VERSION ""

NS_ :

BS_:

BU_: SOBDMB_AWDC BCMC_CPDB BECMB_EPM PACM GWM _delete BCM ACCM DCDC_HEV GENERIC TSTR
VAL_TABLE_ AwdLckMde_D_Stat 7 "NotUsed_2" 6 "NotUsed_1" 5 "PrimaryAxleSpeedControl" 4 "DualAxleSpeedControl" 3 "EfficiencySplit" 2 "SecondaryAxleTorqueCtrl" 1 "SecondaryAxleSpeedCtrl" 0 "Off" ;
VAL_TABLE_ TlghtTestPrecnd_D2_Stat 7 "TrailerNotConnected" 6 "NotStationary" 5 "InteractionPresent" 4 "PreconditionsPassed" 3 "BattSocLessThan75Percent" 2 "TailLightsOn" 1 "IgnitionNotOn" 0 "Null" ;
VAL_TABLE_ TlghtTestLght_D2_Stat 7 "TestingRearFogLights" 6 "AllOff" 5 "TestingReverseLights" 4 "TestingBrakeLights" 3 "TestingLeftTurnSignal" 2 "TestingRightTurnSignal" 1 "ParkingLightsIlluminated" 0 "Null" ;
VAL_TABLE_ NoReqReqNoDataExistsFaulty 3 "Faulty" 2 "NoDataExists" 1 "Request" 0 "NoRequest" ;
VAL_TABLE_ LaActvStats_D2_Dsply 31 "Unused7" 30 "LA_Off" 29 "ECE_OFF_RTT" 28 "Unused4" 27 "Unused3" 26 "Unused2" 25 "Unused1" 24 "InerveneLeft_InterveneRght" 23 "WarnLeft_InterveneRight" 22 "SuppressLeft_InterveneRght" 21 "AvailLeft_InterveneRhtt" 20 "NoLeft_InterveneRight" 19 "InterveneLeft_WarnRight" 18 "WarnLeft_WarnRight" 17 "SuppressLeft_WarnRight" 16 "AvailableLeft_WarnRight" 15 "NoLeft_WarnRight" 14 "InterveneLeft_SuppressRght" 13 "WarnLeft_SuppressRight" 12 "SuppressLeft_SuppressRight" 11 "AvailLeft_SuppressRight" 10 "NoLeft_SuppressRight" 9 "InterveneLeft_AvailRight" 8 "WarnLeft_AvailRight" 7 "SuppressLeft_AvailRight" 6 "AvailableLeft_AvailRight" 5 "NoLeft_AvailableRight" 4 "InterveneLeft_NoRight" 3 "WarnLeft_NoRight" 2 "SuppressLeft_NoRight" 1 "AvailableLeft_NoRight" 0 "NoLeft_NoRight" ;
VAL_TABLE_ PwTrnkFrontRleas_D_Rq 7 "NotUsed_2" 6 "NotUsed_1" 5 "ActivationButtonRequest" 4 "FrontTrunkDiagnostics" 3 "ManualCinch" 2 "EmergencyRelease" 1 "IpSwitchRelease" 0 "Null" ;
VAL_TABLE_ PwTrnkFrontRleas_D_Src 15 "NotUsed_5" 14 "NotUsed_4" 13 "NotUsed_3" 12 "NotUsed_2" 11 "NotUsed_1" 10 "SelfTest" 9 "Diagnostics" 8 "EmergencyReleaseSwitch" 7 "ManualCinch" 6 "ExteriorSwitch" 5 "IpSwitch" 4 "Cpp" 3 "Sync" 2 "Keypad" 1 "Remote" 0 "PowerOff" ;
VAL_TABLE_ OffOnOverruled 3 "NotUsed" 2 "Overruled" 1 "On" 0 "Off" ;
VAL_TABLE_ BattTracThrml_D_Stat 15 "NotUsed_5" 14 "NotUsed_4" 13 "NotUsed_3" 12 "NotUsed_2" 11 "NotUsed_1" 10 "SysFill" 9 "AirPurge" 8 "VlvCalib" 7 "InActvHeaterCoreClntFlw" 6 "ActvHeaterCoreClntFlw" 5 "MxChlrClntFlw" 4 "ChlrClntFlw" 3 "RadClntFlwFan" 2 "RadClntFlwWoFan" 1 "ClntFlw" 0 "ThrmlSysOff" ;
VAL_TABLE_ Null_NoYes_NotUsed 3 "NotUsed" 2 "Yes" 1 "No" 0 "Null" ;
VAL_TABLE_ Bpt_D_StatEvse 15 "Faulty" 14 "NoDataExists" 13 "NotUsed_6" 12 "NotUsed_5" 11 "NotUsed_4" 10 "NotUsed_3" 9 "NotUsed_2" 8 "NotUsed_1" 7 "EvseFault" 6 "EvseEnergyTransferActive" 5 "EvsePreChargeReady" 4 "EvseBptReady" 3 "ConnectionTglNotConfirmed" 2 "ConnectionTglConfirmed" 1 "Initialization" 0 "NotReady" ;
VAL_TABLE_ BptComm_D_Stat 7 "Faulty" 6 "NoDataExists" 5 "LostCommunicationWithTcu" 4 "LostCommunicationWithEvse" 3 "CommunicationEstablished" 2 "EstablishingCommunication" 1 "EvseNotDetected" 0 "Standby" ;
VAL_TABLE_ BptStrtStop_D_Stat 3 "NotUsed_1" 2 "Start" 1 "Stop" 0 "NoRequest" ;
VAL_TABLE_ BptComm_D_RqHtrn 9 "EnergyTransferFault" 8 "EnergyTransferEnd" 7 "VehicleEnergyTransferActv" 6 "VehicleEnergyTransferReady" 5 "VehiclePreChargeReady" 4 "VehicleEnergyTransferWait" 3 "ConfirmConnection" 2 "VehicleReadyToToggle" 1 "AttemptDgtlCommunication" 0 "NoDigitalCommunication" 15 "NotUsed_6" 14 "NotUsed_5" 13 "NotUsed_4" 12 "NotUsed_3" 11 "NotUsed_2" 10 "NotUsed_1" ;
VAL_TABLE_ Bpt_D_StatHtrn 15 "Faulty" 14 "NotUsed_8" 13 "NotUsed_7" 12 "NotUsed_6" 11 "NotUsed_5" 10 "NotUsed_4" 9 "NotUsed_3" 8 "NotUsed_2" 7 "NotUsed_1" 6 "VehicleFault" 5 "EvseFault" 4 "BptActive" 3 "Precharge" 2 "BptReady" 1 "Initialization" 0 "NotReady" ;
VAL_TABLE_ BptMde_D_Stat 7 "NotUsed_4" 6 "NotUsed_3" 5 "NotUsed_2" 4 "NotUsed_1" 3 "Automatic" 2 "Manual" 1 "Off" 0 "Null" ;
VAL_TABLE_ Bpt_D_StatBattTrac 7 "Faulty" 6 "NotUsed_3" 5 "NotUsed_2" 4 "NotUsed_1" 3 "Active" 2 "Ready" 1 "Wait" 0 "NotReady" ;
VAL_TABLE_ OffRoadMde_D_Stat 7 "NotUsed_5" 6 "NotUsed_4" 5 "NotUsed_3" 4 "NotUsed_2" 3 "NotUsed_1" 2 "Off_Road2" 1 "Off_Road1" 0 "On_Road" ;
VAL_TABLE_ PersCtaSplitView_D_Rq 3 "EnabledFull" 2 "Enabled_180SwitchOnly" 1 "Disabled" 0 "Null" ;
VAL_TABLE_ BattChrgInhbt_D2_Rq 7 "NotUsed_4" 6 "NotUsed_3" 5 "NotUsed_2" 4 "NotUsed_1" 3 "MaintainTargetSoc" 2 "EndAtTarget" 1 "InhibitCharging" 0 "Enable_Charging" ;
VAL_TABLE_ AhbFeat_D_Stat 3 "ADB" 2 "GFHB" 1 "AHBC" 0 "None" ;
VAL_TABLE_ NotDetClosedAjarDisabled 5 "NotUsed_2" 4 "NotUsed_1" 3 "Disabled" 2 "Ajar" 1 "Closed" 0 "NotDetermined" 7 "Faulty" 6 "NotUsed_3" ;
VAL_TABLE_ TwoStatePressedNotPressed 3 "NotDetermined" 2 "SwitchState2" 1 "SwitchState1" 0 "NotPressed" ;
VAL_TABLE_ HybSov_D_Falt 7 "FetLowSideOpenOrShort" 6 "FetLifeLimitReached" 5 "FetOpenCircuit" 4 "FetOutputShortToPower" 3 "FetOutputShortToGround" 2 "FetNotControlled" 1 "OnPowerToLoad" 0 "OffNoPowerToLoad" ;
VAL_TABLE_ PaaKMyKeyChng_D_Stat 3 "NotUsed" 2 "ClearAll" 1 "MyKey" 0 "Null" ;
VAL_TABLE_ TemperatureColorDsply 3 "NotUsed" 2 "ColorForSeverlyLimited" 1 "ColorForLimited" 0 "ColorForNormal" ;
VAL_TABLE_ DcacRdy_D_Stat 7 "NotUsed_2" 6 "NotUsed_1" 5 "Faulted" 4 "ProtectionTempearture" 3 "ProtectionOverload" 2 "ProtectionGfci" 1 "Active" 0 "Idle" ;
VAL_TABLE_ HvacCmprLim_D_Stat 7 "NotUsed_2" 6 "NotUsed_1" 5 "CompressorHeadPressure" 4 "AvailableTorque" 3 "PedalPosition" 2 "RPM" 1 "ECT" 0 "NoLimit" ;
VAL_TABLE_ EvseDcChrgIso_D_Stat 7 "Faulty" 6 "NoDataExists" 5 "NotUsed_3" 4 "NotUsed_2" 3 "NotUsed_1" 2 "Valid" 1 "Warning" 0 "Invalid" ;
VAL_TABLE_ PtRmtRprt_D_Stat 15 "NotUsed_4" 14 "NotUsed_3" 13 "NotUsed_2" 12 "PlugInToMaintain12vBattery" 11 "SettingUpdated" 10 "FastChargeComplete" 9 "ChargeNotOccurring" 8 "OneTimeSocReached" 7 "BatteryTemperatureRemind" 6 "ReducedPerformance" 5 "LimitedPerformance" 4 "ChargeFault" 3 "ChargeComplete" 2 "VehiclePreconditioned" 1 "TripDistanceAchieved" 0 "NoReportRequest" ;
VAL_TABLE_ VehOnSrc_D_Stat 15 "NotUsed_11" 14 "NotUsed_10" 13 "NotUsed_9" 12 "NotUsed_8" 11 "NotUsed_7" 10 "NotUsed_6" 9 "EsclRssd" 8 "AutonomousVehicle" 7 "SecureIdle" 6 "FleetVehicleInhibit" 5 "StolenVehicleInhibit" 4 "OverTheAir" 3 "RemoteParkAssist" 2 "RemoteStart" 1 "Manual" 0 "Off" ;
VAL_TABLE_ OfbChrgSetSync_D_Rq 3 "Fail" 2 "Success" 1 "InProgress" 0 "NoSyncInProgress" ;
VAL_TABLE_ StrtrMtrCtlMsgTxt_D2_Rq 3 "NoRequestPcmStartingMsgCtl" 2 "ShiftToNeutralToStart" 1 "ShiftToParkToStart" 0 "NoRequestBcmStartingMsgCtl" ;
VAL_TABLE_ InvalidNotSupported_FE_FF 255 "NotSupported" 254 "Invalid" ;
VAL_TABLE_ PaakMyKey_D_Rq 3 "NotUsed" 2 "ConfirmNewPaakMyKey" 1 "RequestNewPaakMyKey" 0 "None" ;
VAL_TABLE_ PaakMyKeySearch_D_Stat 7 "PhoneErased" 6 "LockButtonTimeOut" 5 "PressLockButton" 4 "ConfirmHmi" 3 "MyKeyPaakFound" 2 "StandardPaakFound" 1 "NoValidPaakFound" 0 "Null" ;
VAL_TABLE_ GearPrkLck_D_Stat 7 "NotUsed_1" 6 "FetLifeLimitReached" 5 "FetOpenCircuit" 4 "FetOutputShortToPower" 3 "FetOutputShortToGround" 2 "FetNotControlled" 1 "OnPowerToLoad" 0 "OffNoPowerToLoad" ;
VAL_TABLE_ DcChrgRdy_D_Stat 15 "Faulty" 14 "NotUsed_4" 13 "NotUsed_3" 12 "NotUsed_2" 11 "CableCheck" 10 "EvseFault" 9 "EvseNotCompatible" 8 "EvsePaused" 7 "GbtPrecharge" 6 "ChargeComplete" 5 "Charging" 4 "Precharge" 3 "WeldCheck" 2 "ChargeReady" 1 "Initialization" 0 "NotReady" ;
VAL_TABLE_ DgtlCommGtwyMde_D_Stat 11 "NotUsed_3" 10 "DgtlCommFailed" 9 "DgtlCommEstablished" 8 "Inactive" 7 "RestartRequest" 6 "AcPnc_Eim" 5 "AcPnc" 4 "AcEim" 3 "DcPnc_Eim" 2 "DcPnc" 1 "DcEim" 0 "NotDetected" 15 "NotUsed_7" 14 "NotUsed_6" 13 "NotUsed_5" 12 "NotUsed_4" ;
VAL_TABLE_ InvalidValidWarningFaulty 3 "Faulty" 2 "Warning" 1 "Valid" 0 "Invalid" ;
VAL_TABLE_ BattChrgMde_D_Actl 3 "NotUsed" 2 "ConstantCurrent" 1 "ConstantVoltage" 0 "NotCharging" ;
VAL_TABLE_ BattTracType_D_Actl 15 "NotUsed_7" 14 "NotUsed_6" 13 "NotUsed_5" 12 "NotUsed_4" 11 "NotUsed_3" 10 "NotUsed_2" 9 "NotUsed_1" 8 "Other" 7 "LithiumTitanateOxide" 6 "LithiumIonPolymer" 5 "TernaryMaterial" 4 "LithiumCobaltOxide" 3 "LithiumManganese" 2 "LithiumIronPhosphate" 1 "NickelMetalHydride" 0 "LeadAcid" ;
VAL_TABLE_ PaakAddErase_D_Rq 3 "EraseAll" 2 "Erase" 1 "Add" 0 "Null" ;
VAL_TABLE_ NoSelect_LowMed_High 3 "High" 2 "Medium" 1 "Low" 0 "NoSelection" ;
VAL_TABLE_ LcwaMsgTxt_D_Stat 3 "SodXFaulty" 2 "SodXBlocked" 1 "TrailerConnected" 0 "NoMessage" ;
VAL_TABLE_ AirCondClu_D_Stat 7 "NotUsed" 6 "FetLifeLimitReached" 5 "FetOpenCircuit" 4 "FetOutputShortToPower" 3 "FetOutputShortToGround" 2 "FetNotControlled" 1 "OnPowerToLoad" 0 "OffNoPowerToLoad" ;
VAL_TABLE_ BattChrgTrgtSoC_D_Rq 7 "Percent_50" 6 "Percent_60" 5 "Percent_70" 4 "Percent_80" 3 "Percent_85" 2 "Percent_90" 1 "Percent_95" 0 "Percent_100" ;
VAL_TABLE_ KeyPadCodeProg_D_Rq 7 "NotUsed_3" 6 "NotUsed_2" 5 "NotUsed_1" 4 "DeleteAll" 3 "Delete" 2 "Add" 1 "ProgrammingMode" 0 "Null" ;
VAL_TABLE_ KeyPadCodeProg_D_Stat 7 "NotUsed_2" 6 "Duplicate" 5 "ProgrammingFailure" 4 "DeleteAll" 3 "Delete" 2 "Add" 1 "LearningMode" 0 "NormalMode" ;
VAL_TABLE_ FobTrgtZone_D_Rq 15 "NotUsed_9" 14 "NotUsed_8" 13 "NotUsed_7" 12 "NotUsed_6" 11 "NotUsed_5" 10 "NotUsed_4" 9 "NotUsed_3" 8 "NotUsed_2" 7 "NotUsed_1" 6 "Approach" 5 "RearInterior" 4 "RearExterior" 3 "Passenger" 2 "Driver" 1 "Interior" 0 "Null" ;
VAL_TABLE_ FobTrgtType_D_Rq 7 "NotUsed_4" 6 "NotUsed_3" 5 "NotUsed_2" 4 "NotUsed_1" 3 "Polling" 2 "Registry" 1 "Crypto" 0 "Null" ;
VAL_TABLE_ DgtlCommGtwyMde_D_Rq 15 "NotUsed_10" 14 "NotUsed_9" 13 "NotUsed_8" 12 "NotUsed_7" 11 "NotUsed_6" 10 "NotUsed_5" 9 "NotUsed_4" 8 "NotUsed_3" 7 "NotUsed_2" 6 "NotUsed_1" 5 "AcPnC" 4 "AcEIM" 3 "DcPnC" 2 "DcEIM" 1 "AttemptDgtlComm" 0 "NoDgtlComm" ;
VAL_TABLE_ BattDcCnnct_D_Cmd 7 "NotUsed_3" 6 "NotUsed_2" 5 "NotUsed_1" 4 "WeldCheck" 3 "OkToDischarge" 2 "Closed" 1 "Precharge" 0 "Open" ;
VAL_TABLE_ Null_NoFault_Fault 3 "NotUsed" 2 "Fault" 1 "NoFault" 0 "Null" ;
VAL_TABLE_ ModemReset_D_Stat 15 "NotUsed_10" 14 "NotUsed_9" 13 "NotUsed_8" 12 "NotUsed_7" 11 "NotUsed_6" 10 "NotUsed_5" 9 "NotUsed_4" 8 "NotUsed_3" 7 "NotUsed_2" 6 "NotUsed_1" 5 "WifiHotSpotResetComplete" 4 "CcsResetComplete" 3 "OnlineTrafficResetComplete" 2 "PaakResetComplete" 1 "ResetNotComplete" 0 "Null" ;
VAL_TABLE_ ModemReset_D_Rq 15 "NotUsed_11" 14 "NotUsed_10" 13 "NotUsed_9" 12 "NotUsed_8" 11 "NotUsed_7" 10 "NotUsed_6" 9 "NotUsed_5" 8 "NotUsed_4" 7 "NotUsed_3" 6 "BrandConnectReset2" 5 "BrandConnectReset1" 4 "CcsReset" 3 "OnlineTrafficReset" 2 "PaakReset" 1 "WifiHotspotReset" 0 "Null" ;
VAL_TABLE_ RstrnOnPsngr_D_RqMnu 15 "Faulty" 14 "NotUsed_11" 13 "NotUsed_10" 12 "ConfiguredOff" 11 "NotUsed_9" 10 "On" 9 "NotUsed_8" 8 "NotUsed_7" 7 "NotUsed_6" 6 "NotUsed_5" 5 "Off" 4 "NotUsed_4" 3 "NotUsed_3" 2 "NotUsed_2" 1 "NotUsed_1" 0 "NoAction" ;
VAL_TABLE_ SldrlUnlckSwtch_D_Stat 3 "InnerHandle" 2 "RearInteriorSwitch" 1 "IpSwitch" 0 "Null" ;
VAL_TABLE_ Sldrl_D_Stat 3 "NotCalibrated" 2 "Closing" 1 "Opening" 0 "NotMoving" ;
VAL_TABLE_ Null_NotAvail_Avail 3 "NotUsed" 2 "Available" 1 "NotAvailable" 0 "Null" ;
VAL_TABLE_ ChrgGoTMnte_D_Stat 15 "NotUsed_4" 14 "NotUsed_3" 13 "NotUsed_2" 12 "NotUsed_1" 11 "Minute_55" 10 "Minute_50" 9 "Minute_45" 8 "Minute_40" 7 "Minute_35" 6 "Minute_30" 5 "Minute_25" 4 "Minute_20" 3 "Minute_15" 2 "Minute_10" 1 "Minute_5" 0 "Minute_0" ;
VAL_TABLE_ NoData_Faulty_1E_1F 31 "Faulty" 30 "NoDataExists" ;
VAL_TABLE_ TrlrTngLoad_D_Stat 7 "Faulty" 6 "NoDataExists" 5 "NotUsed_3" 4 "NotUsed_2" 3 "NotUsed_1" 2 "AboveRange" 1 "InRange" 0 "BelowRange" ;
VAL_TABLE_ NoRequestReqNotUsedFaulty 3 "Faulty" 2 "NotUsed" 1 "Request" 0 "NoRequest" ;
VAL_TABLE_ VehFalr_D_Stat 7 "Faulty" 6 "NotUsed_3" 5 "NotUsed_2" 4 "NotUsed_1" 3 "HeightCorrectionCompleted" 2 "SecondMeasurementCollected" 1 "FirstMeasurementCollected" 0 "NotActive" ;
VAL_TABLE_ VehFalr_D_Rq 7 "NotUsed_3" 6 "NotUsed_2" 5 "NotUsed_1" 4 "NotComplete" 3 "Complete" 2 "RequestSecondMeasurement" 1 "RequestFirstMeasurement" 0 "NoRequest" ;
VAL_TABLE_ TailLghtLoadMde_D_Rq 7 "NotUsed_3" 6 "NotUsed_2" 5 "NotUsed_1" 4 "DeactivateAll" 3 "ActivateFalrMode" 2 "ActivateHitchLoadMode" 1 "ActivatePayloadMode" 0 "NoCommand" ;
VAL_TABLE_ VehPayloadScrn_D_Rq 7 "CheckLoadScreenActive" 6 "WeightCarryScreenActive" 5 "GooseneckScreenActive" 4 "FifthWheelScreenActive" 3 "WeightDistScreenActive" 2 "AddMassEstScreenActive" 1 "PayloadEstScreenActive" 0 "ScaleScreenNotActive" ;
VAL_TABLE_ TailLghtLoadMde_D_Stat 7 "Faulty" 6 "NotUsed_2" 5 "NotUsed_1" 4 "TailLightModeOverride" 3 "FalrModeActive" 2 "HitchLoadModeActive" 1 "PayloadModeActive" 0 "NoTailLightActive" ;
VAL_TABLE_ DrvBhavAudioAlrt_D_Rq 58 "NotUsed_51" 57 "NotUsed_50" 56 "NotUsed_49" 55 "NotUsed_48" 54 "NotUsed_47" 53 "NotUsed_46" 52 "NotUsed_45" 25 "NotUsed_18" 24 "NotUsed_17" 23 "NotUsed_16" 22 "NotUsed_15" 21 "NotUsed_14" 20 "NotUsed_13" 19 "NotUsed_12" 18 "NotUsed_11" 17 "NotUsed_10" 16 "NotUsed_9" 15 "NotUsed_8" 14 "NotUsed_7" 13 "NotUsed_6" 12 "NotUsed_5" 11 "NotUsed_4" 10 "NotUsed_3" 9 "NotUsed_2" 8 "NotUsed_1" 7 "ExcessiveIdleAndUnbuckled" 6 "ExcessiveSpeedAndUnbuckled" 5 "SeatbeltUnbuckled" 4 "HardBrakingBegin" 3 "HardAccelerationBegin" 2 "ExcessiveSpeedBegin" 1 "ExcessiveIdleBegin" 0 "NoMessage" 63 "NotUsed_56" 62 "NotUsed_55" 61 "NotUsed_54" 60 "NotUsed_53" 59 "NotUsed_52" ;
VAL_TABLE_ DcacFaltMsgTxt_D2_Rq 63 "NotUsed_47" 17 "NotUsed_1" 16 "HevDerate" 15 "HvacOn" 14 "OvercurrentLP" 13 "EngineRun" 12 "Service" 11 "NotAvailable" 10 "PlugWarn" 9 "PlugWarnDrive" 8 "BreakerC" 7 "BreakerB" 6 "BreakerA" 5 "FuelLow" 4 "AcOnOutput" 3 "Temperature" 2 "Gfci" 1 "Overcurrent" 0 "Ok" ;
VAL_TABLE_ NotAvail_OffOn_Faulty 3 "Faulty" 2 "On" 1 "Off" 0 "NotAvailable" ;
VAL_TABLE_ Mtr4_D_StatMntr 7 "Faulty" 6 "NotDataExists" 5 "NotUsed" 4 "ReadinessState" 3 "DeactivationState" 2 "PowerGeneration" 1 "PowerConsumption" 0 "Null" ;
VAL_TABLE_ Hour5bitNull 31 "NotUsed_7" 30 "NotUsed_6" 29 "NotUsed_5" 28 "NotUsed_4" 27 "NotUsed_3" 26 "NotUsed_2" 25 "NotUsed_1" 24 "Hour23_11pm" 23 "Hour22_10pm" 22 "Hour21_9pm" 21 "Hour20_8pm" 20 "Hour19_7pm" 19 "Hour18_6pm" 18 "Hour17_5pm" 17 "Hour16_4pm" 16 "Hour15_3pm" 15 "Hour14_2pm" 14 "Hour13_1pm" 13 "Hour12_12pm" 12 "Hour11_11am" 11 "Hour10_10am" 10 "Hour9_9am" 9 "Hour8_8am" 8 "Hour7_7am" 7 "Hour6_6am" 6 "Hour5_5am" 5 "Hour4_4am" 4 "Hour3_3am" 3 "Hour2_2am" 2 "Hour1_1am" 1 "Hour0_12am" 0 "Null" ;
VAL_TABLE_ SdarsAudioRtng_D_Stat 3 "NotUsed" 2 "APIMStereoOut" 1 "X40l2SStereoOut" 0 "NotDetermined" ;
VAL_TABLE_ OffOnOutageFaulty 3 "Faulty" 2 "Outage" 1 "On" 0 "Off" ;
VAL_TABLE_ PrkMde_D_ET 3 "NotUsed" 2 "FreeDrive" 1 "ParkIn" 0 "None" ;
VAL_TABLE_ RmtCtlPrkInSlot_D_ET 7 "NotUsed_3" 6 "NotUsed_2" 5 "NotUsed_1" 4 "Right" 3 "Left" 2 "Rear" 1 "Front" 0 "None" ;
VAL_TABLE_ MoveDir_D_ET 3 "NotUsed" 2 "Backward" 1 "Forward" 0 "None" ;
VAL_TABLE_ ApaMsgTxt_D2_Stat 15 "ReducedFunction" 14 "TrailerFeatureNotAvailable" 13 "AcceleratorPedalInactive" 12 "SensorsBlocked" 11 "TrailerAttached" 10 "TcsDeactivated" 9 "WheelSlip" 8 "HighInclination" 7 "DoorOpen" 6 "SteeringInteraction" 5 "WrongDirection" 4 "SpeedLimitExceeded" 3 "BrakeEvent" 2 "ObstacleInPath" 1 "WaitForSteering" 0 "None" ;
VAL_TABLE_ ApaDrvRq1MsgTxt_D_Rq 7 "NotUsed" 6 "ExitVehicle" 5 "PressApaButton" 4 "ShiftToP" 3 "ShiftToN" 2 "ShiftToD" 1 "ShiftToR" 0 "NoRequest" ;
VAL_TABLE_ DisplayMode 3 "NotUsed" 2 "FullScreen" 1 "Menu" 0 "Off" ;
VAL_TABLE_ ApaSys_D2_Stat 15 "NotUsed_5" 14 "NotUsed_4" 13 "NotUsed_3" 12 "NotUsed_2" 11 "NotUsed_1" 10 "NoSideSelectable" 9 "RightSideSelectable" 8 "LeftSideSelectable" 7 "BothSidesSelectable" 6 "Faulty" 5 "Finished" 4 "Cancelled" 3 "NotAvailable" 2 "Overspeed" 1 "Pause" 0 "NormalOperation" ;
VAL_TABLE_ ApaDrvRq2MsgTxt_D_Rq 15 "NotUsed_7" 14 "NotUsed_6" 13 "NotUsed_5" 12 "NotUsed_4" 11 "NotUsed_3" 10 "NotUsed_2" 9 "NotUsed_1" 8 "CloseDoor" 7 "TakeControl" 6 "ReleaseEpb" 5 "ReleaseSteering" 4 "ReleaseBrake" 3 "DriveBackward" 2 "DriveForward" 1 "Stop" 0 "NoRequest" ;
VAL_TABLE_ ApaSlotTrgt_D_Stat 15 "NotUsed_7" 14 "NotUsed_6" 13 "NotUsed_5" 12 "NotUsed_4" 11 "NotUsed_3" 10 "NotUsed_2" 9 "NotUsed_1" 8 "Front" 7 "Rear" 6 "Right3" 5 "Right2" 4 "Right1" 3 "Left3" 2 "Left2" 1 "Left1" 0 "None" ;
VAL_TABLE_ NtfctnConflict1_D_Rq 7 "NotUsed_4" 6 "NotUsed_3" 5 "NotUsed_2" 4 "NotUsed_1" 3 "ChargeWindow" 2 "DepartureTime" 1 "NoConflictExists" 0 "Null" ;
VAL_TABLE_ InactiveDisableEnableNotUsed 3 "NotUsed" 0 "Inactive" 2 "Enable" 1 "Disable" ;
VAL_TABLE_ ChrgStat_D2_Dsply 15 "ChargeStopCommanded" 14 "ChargeStartCommanded" 13 "ChargeTargetReached" 12 "DriveConditioning" 11 "CabinPreconditioning" 10 "ChargingSystemMaintain" 9 "ChargingInductive" 8 "ChargingDCFastCharge" 7 "ChargingAC" 6 "ChargeScheduled" 5 "EvsePaused" 4 "EvseNotDetected" 3 "EvseNotCompatible" 2 "FaultOutsideCar" 1 "FaultInsideCar" 0 "NotReady" ;
VAL_TABLE_ Null_Manual_Automatic 3 "NotUsed" 2 "Automatic" 1 "Manual" 0 "Null" ;
VAL_TABLE_ BattChrgStrtStop_D_Rq 3 "ReturnToSettings" 2 "StopCharge" 1 "StartCharge" 0 "NoNewRequest" ;
VAL_TABLE_ NoRequest_Mode1_2_3 3 "Mode_3" 2 "Mode_2" 1 "Mode_1" 0 "NoRequest" ;
VAL_TABLE_ RvltnMatchAllw_D_Stat 3 "RevolutionMatchDisabled" 2 "RevolutionMatchEnabled" 1 "ChangeWithDriveMode" 0 "NoSelection" ;
VAL_TABLE_ BattTracCnnct_D_Cmd 7 "NotUsed_3" 6 "NotUsed_2" 5 "NotUsed_1" 4 "WeldCheck" 3 "OkToDischarge" 2 "Closed" 1 "Precharge" 0 "Open" ;
VAL_TABLE_ Faulty_1F 31 "Faulty" ;
VAL_TABLE_ NotDiagnose_FailPass 3 "NotUsed" 2 "Pass" 1 "Fail" 0 "Not_Diagnose_Yet" ;
VAL_TABLE_ Off_On_NotUsed 3 "NotUsed_2" 2 "NotUsed_1" 1 "On" 0 "Off" ;
VAL_TABLE_ OffNoPowerToLoad 7 "NotUsed_1" 6 "FetLifeLimitReached" 5 "FetOpenCircuit" 4 "FetOutputShortToPower" 3 "FetOutputShortToGround" 2 "FetNotControlled" 1 "OnPowerToLoad" 0 "OffNoPowerToLoad" ;
VAL_TABLE_ BrkAppl_D_RqPt 3 "BrakesSlowRelease" 2 "BrakesFastRelease" 1 "BrakesEngage" 0 "NotActive" ;
VAL_TABLE_ TrailCtl_D_Stat 7 "Faulty" 6 "DescentOnly" 5 "EnabledDeny" 4 "StandbyOverThreshold" 3 "StandbyOverride" 2 "Active" 1 "EnabledDescent" 0 "Off" ;
VAL_TABLE_ Faulty_3F 63 "Faulty" ;
VAL_TABLE_ Quality_Data_Faulty 3 "OK" 2 "Not_Within_Specifications" 1 "Eval_In_Progress" 0 "Faulty" ;
VAL_TABLE_ AirAmbTePlgIn_D_Dsply 3 "NotUsed" 2 "Hot_Outside_Plg_In_Msg" 1 "Cold_Outside_Plg_In_Msg" 0 "No_Plg_In_Msg" ;
VAL_TABLE_ NoFault_Fault 1 "Fault" 0 "No_Fault" ;
VAL_TABLE_ OtaTrg_D_Stat 3 "NotUsed_1" 2 "Accepted" 1 "NotAccepted" 0 "Null" ;
VAL_TABLE_ PaakTrgtType_D_Rq 7 "NotUsed_4" 6 "NotUsed_3" 5 "NotUsed_2" 4 "NotUsed_1" 3 "Polling" 2 "Registry" 1 "Crypto" 0 "Null" ;
VAL_TABLE_ PaakTrgtZone_D_Rq 15 "NotUsed_9" 14 "NotUsed_8" 13 "NotUsed_7" 12 "NotUsed_6" 11 "NotUsed_5" 10 "NotUsed_4" 9 "NotUsed_3" 8 "NotUsed_2" 7 "NotUsed_1" 6 "Approach" 5 "RearInterior" 4 "RearExterior" 3 "Passenger" 2 "Driver" 1 "Interior" 0 "Null" ;
VAL_TABLE_ PaakTrgtData_D_Rq 5 "NotUsed_2" 4 "Not_Used1" 3 "Target1_IdBlock2" 2 "Target1_IdBlock1" 1 "Challenge" 0 "Idle" 7 "NotUsed_4" 6 "NotUsed_3" ;
VAL_TABLE_ PaakCtlActv_D_Rq 31 "NotUsed_13" 30 "NotUsed_12" 29 "NotUsed_11" 28 "NotUsed_10" 27 "NotUsed_9" 26 "NotUsed_8" 25 "NotUsed_7" 24 "NotUsed_6" 23 "NotUsed_5" 22 "NotUsed_4" 21 "NotUsed_3" 20 "TrunkFrontRelease" 19 "RemoteStop" 18 "RemoteStart" 17 "PowerDecklid" 16 "RightPowerSlidingDoor" 15 "LeftPowerSlidingDoor" 14 "PowerLiftgate" 13 "GlobalClose" 12 "GlobalOpen" 11 "PanicOff" 10 "PanicOn" 9 "LiftgateGlassRelease" 8 "LiftgateRelease" 7 "DecklidRelease" 6 "DoubleLock" 5 "LockAll" 4 "UnlockAllDoorsPlusCargo" 3 "UnlockCargoDoor" 2 "UnlockAllDoors" 1 "UnlockDriverDoor" 0 "Null" ;
VAL_TABLE_ Null_Invalid_Valid 3 "NotUsed" 2 "Valid" 1 "Invalid" 0 "Null" ;
VAL_TABLE_ PaakCtlData_D_Stat 7 "NotUsed_3" 6 "NotUsed_2" 5 "NotUsed_1" 4 "Response" 3 "EchoTargetIdBlock1" 2 "RequestTargetIdBlock2" 1 "RequestTargetIdBlock1" 0 "Idle" ;
VAL_TABLE_ EngAirFiltMsgTxt_D_Rq 7 "NotUsed_2" 6 "ReducedEngPwCheckAirFilter" 5 "EngineAirFilterMonitorFalt" 4 "ResetComplete" 3 "Clogged" 2 "ReplaceNow" 1 "ReplaceSoon" 0 "NoMessage" ;
VAL_TABLE_ ElPwPoint_D_Rq 3 "On" 2 "Off2" 1 "Off1" 0 "Null" ;
VAL_TABLE_ RearDiffThrml_D_Stat 3 "NotUsed_1" 2 "AboveThermalLimit" 1 "ThermalLimit" 0 "Normal" ;
VAL_TABLE_ NoInhibit_Inhibit 1 "Inhibit" 0 "NoInhibit" ;
VAL_TABLE_ PersRecallSrc_D_Actl 7 "NotUsed_3" 6 "NotUsed_2" 5 "NotUsed_1" 4 "MemorySwitch" 3 "RemoteStart" 2 "KeyFob" 1 "CenterStack" 0 "Null" ;
VAL_TABLE_ BattTracChiller_D_Stat 3 "NotUsed" 2 "ChillerNotAvailable" 1 "ChillerBrieflyAvailable" 0 "ChillerAvailable" ;
VAL_TABLE_ VehShutDownMsgTxt_D_Rq 3 "NotUsed" 2 "ProhibitedRestart" 1 "ShutdownWarning" 0 "NoMessage" ;
VAL_TABLE_ TrnkFrontRleas_D_Src 7 "NotUsed_3" 6 "NotUsed_2" 5 "NotUsed_1" 4 "Cpp" 3 "Sync" 2 "Keypad" 1 "Remote" 0 "Null" ;
VAL_TABLE_ StopoverType_D_Stat 7 "Faulty" 6 "NotUsed_1" 5 "Other" 4 "Work" 3 "Home" 2 "ChargeStation" 1 "FinalDestination" 0 "Null" ;
VAL_TABLE_ NoData_Faulty_3FFFE_3FFFF 262143 "Faulty" 262142 "NoDataExists" ;
VAL_TABLE_ KeylessIdl_D_Rq 3 "Cancel" 2 "IgnitionOff" 1 "Active" 0 "Inactive" ;
VAL_TABLE_ OBCCSerial_D_Rq 3 "PresentAndProvisioned" 2 "PresentAndProvAlertAck" 1 "PresentAndUnprovisioned" 0 "NotPresent" ;
VAL_TABLE_ VehInhbtMde_D_Stat 7 "NotUsed_3" 6 "NotUsed_2" 5 "NotUsed_1" 4 "FullVehicleOta" 3 "Iviota" 2 "SyncOta" 1 "NoOtaSupport" 0 "Unconfigured" ;
VAL_TABLE_ DsmcMsgTxt_D_Dsply 3 "Blockage" 2 "DriverNotSeen" 1 "Fault" 0 "NoMessage" ;
VAL_TABLE_ DgtlCommPnc_D_Stat 7 "Faulty" 6 "NotUsed_3" 5 "NotUsed_2" 4 "NotUsed_1" 3 "Enable" 2 "Disable" 1 "NoContractsInstalled" 0 "Null" ;
VAL_TABLE_ TlghtTest_D_Stat 3 "InProgress" 2 "Ended" 1 "Completed" 0 "Null" ;
VAL_TABLE_ TlghtTestPrecnd_D_Stat 7 "Error" 6 "NotStationary" 5 "InteractionPresent" 4 "PreconditionsPassed" 3 "BattSocLessThan75Percent" 2 "TailLightsOn" 1 "IgnitionNotOn" 0 "Null" ;
VAL_TABLE_ TlghtTestLght_D_Stat 7 "Error" 6 "AllOff" 5 "TestingReverseLights" 4 "TestingBrakeLights" 3 "TestingLeftTurnSignal" 2 "TestingRightTurnSignal" 1 "ParkingLightsIlluminated" 0 "Null" ;
VAL_TABLE_ TlightTest_D_Rq 3 "TestEndAcknowledge" 2 "StartTest" 1 "StopTest" 0 "Null" ;
VAL_TABLE_ NoFaultFaultTemporary 3 "NotUsed" 2 "TemporaryFault" 1 "Fault" 0 "NoFault" ;
VAL_TABLE_ Null_Disabled_Enabled 3 "NotUsed" 2 "Enabled" 1 "Disabled" 0 "Null" ;
VAL_TABLE_ LghtAmbDrvMde_B_Stat 1 "Automatic" 0 "Manual" ;
VAL_TABLE_ LghtAmbDrvMde_D_Rq 3 "NotUsed" 2 "Automatic" 1 "Manual" 0 "Null" ;
VAL_TABLE_ PaakLoclzd_D_Stat 15 "NotUsed_12" 14 "NotUsed_11" 13 "NotUsed_10" 12 "NotUsed_9" 11 "NotUsed_8" 10 "NotUsed_7" 9 "NotUsed_6" 8 "NotUsed_5" 7 "NotUsed_4" 6 "NotUsed_3" 5 "NotUsed_2" 4 "NotUsed_1" 3 "FullLoc" 2 "PausedLoc" 1 "MaintainLink" 0 "BackgroundScan" ;
VAL_TABLE_ NullMphKph 3 "NotUsed" 2 "Kph" 1 "Mph" 0 "Null" ;
VAL_TABLE_ GoTEditMnte_T_RqMnu 15 "Faulty" 14 "NoDataExists" 13 "NotUsed_2" 12 "NotUsed_1" 11 "Minute_55" 10 "Minute_50" 9 "Minute_45" 8 "Minute_40" 7 "Minute_35" 6 "Minute_30" 5 "Minute_25" 4 "Minute_20" 3 "Minute_15" 2 "Minute_10" 1 "Minute_5" 0 "Minute_0" ;
VAL_TABLE_ OffOnSuspendedFaulty 3 "Faulty" 2 "Suspended" 1 "On" 0 "Off" ;
VAL_TABLE_ DgtlCommGtwy_D_Falt 127 "NotUsed_63" 65 "NotUsed_1" 64 "EvseGbtCommTimeout" 63 "EvseGbtCrgVoltMismatch" 62 "EvseGbtChrgCurrntMismatch" 61 "EvseGbtOtherFalt" 60 "EvseGbtEmergShutdown" 59 "EvseGbtEnergyTransFalt" 58 "EvseGbtIntOverTemp" 57 "EvseGbtConnectorFalt" 56 "EvseGbtOverTemp" 55 "EvseResCpsRootCaCertRev" 54 "EvseResSubCA2CertRev" 53 "EvseResSubCA1CertRev" 52 "EvseResCpsProvCertRev" 51 "EvseResRootCaCertRev" 50 "EvseResMoSubCa2CertRev" 49 "EvseResMoSubCa1CertRev" 48 "EvseResMoProvCertRev" 47 "EvseResOemSubCa2CertRev" 46 "EvseResOemSubCa1CertRev" 45 "EvseResOemProvCertRev" 44 "EvseResMoUnknown" 43 "EvseResContractNotAccept" 42 "EvseResNoSuppAppProt" 41 "EvseResCertNotAllowed" 40 "EvseResContractErr" 39 "EvseResNoChrgSvcSelect" 38 "EvseResMeterSignNotVld" 37 "EvseResPwrDelNotApplied" 36 "EvseResTrfSelectInvld" 35 "EvseResChrgProfileInvld" 34 "EvseResWrongChrgParam" 33 "EvseResWrongEnrgyTransMde" 32 "EvseResChlgInvld" 31 "EvseResContractCancel" 30 "EvseResCertChainErr" 29 "EvseResNoCertAvail" 28 "EvseResCertRvk" 27 "EvseResCertExp" 26 "EvseResPymtSelectInvld" 25 "EvseResSvcldInvld" 24 "EvseResUnknownSession" 23 "EvseResSignErr" 22 "EvseResSeqErr" 21 "EvseResFailed" 20 "EvsePreChrgTimeout" 19 "EvseCableCheckTimeout" 18 "EvseCommSetupTimeout" 17 "EvseMsgTimeout" 16 "EvseTlsUnknownCA" 15 "EvseTlsCertExpired" 14 "EvseTlsBadCert" 13 "EvseTlsHandshakeFail" 12 "EvseTlsDecryptFail" 11 "EvseTlsBadRecordMac" 10 "EvseTlsUnexpectedMsg" 9 "EvseTlsFail" 8 "EvseTcpCnnctFail" 7 "EvseUpdErr" 6 "EvseSlaacErr" 5 "EvseStopNotification" 4 "EvseMalfunction" 3 "EvseEmergShutdown" 2 "EvseStatUtilityIntrpt" 1 "EvseStatShutdown" 0 "NoFault" ;
VAL_TABLE_ CellLock_D_Rq 7 "BEC_Enable" 6 "Cargo_Unlock" 5 "Cabin_Unlock" 4 "TrunkRelPopGlassLgCargo" 3 "LockAllDoorsandTailgate" 2 "UnlockDriversDoor" 1 "UnlockAllDoorsandTailgate" 0 "NoRequest" ;
VAL_TABLE_ KeyPadCodeDgt1_D_Stat 15 "NotUsed_4" 14 "NotUsed_3" 13 "NotUsed_2" 12 "NotUsed_1" 11 "Button7_8and9_0" 10 "Button0" 9 "Button9_0or9" 8 "Button8" 7 "Button7_8or7" 6 "Button6" 5 "Button5_6or5" 4 "Button4" 3 "Button3_4or3" 2 "Button2" 1 "Button1_2or1" 0 "EndofString" ;
VAL_TABLE_ Closed_Open 1 "Open" 0 "Closed" ;
VAL_TABLE_ FactoryReset_St 3 "NotUsed_2" 2 "NotUsed_1" 1 "FactoryDefaultsRestored" 0 "Null" ;
VAL_TABLE_ TelematicsSrvc_D_St 7 "NotUsed" 6 "NotifyNotActivatedYet" 5 "NotActivatedYet" 4 "NotifyExpired" 3 "Expired" 2 "ExpiringSoon" 1 "Active" 0 "Null" ;
VAL_TABLE_ FactoryReset_Rq 1 "ResetFactoryDefaults" 0 "Inactive" ;
VAL_TABLE_ Null_NotConnected_Conn 3 "NotUsed" 2 "Connected" 1 "NotConnected" 0 "Null" ;
VAL_TABLE_ TCU_Init_Actvtn_St 3 "NotUsed" 2 "InitialActivateDeny" 1 "InitialActivateAccept" 0 "Invalid" ;
VAL_TABLE_ TCU_Final_Actvtn_St 3 "NotUsed" 2 "FinalActivateDeny" 1 "FinalActivateAccept" 0 "Invalid" ;
VAL_TABLE_ Null_Disable_Enable 3 "NotUsed" 2 "Enable" 1 "Disable" 0 "Null" ;
VAL_TABLE_ BattTracCoolLvl_D_Rq 7 "Faulty" 6 "NotUsed" 5 "ChillerCoolingBattFirst" 4 "ChillerCoolingCabinFirst" 3 "ForcedCoolingRadiator" 2 "OpportunisticCoolingRad" 1 "CoolantFlowBypassLine" 0 "Off" ;
VAL_TABLE_ BattClntVlvOvrrd_D_Rq 3 "NotUsed" 2 "OverrideTbcvToChiller" 1 "OverrideTbcvToRadiator" 0 "NoOverrideToTbcvCLogic" ;
VAL_TABLE_ AutoTowAllw_D_StatMnu 3 "TowHaulCommandedOn" 2 "AutoTowHaulEnabled" 1 "AutoTowHaulDisabled" 0 "NoSelection" ;
VAL_TABLE_ SpkrStd_D_Stat 3 "Faulty" 2 "Normal" 1 "NotPresent" 0 "Null" ;
VAL_TABLE_ RearDiff_D_Stat 15 "NotUsed_7" 14 "NotUsed_6" 13 "NotUsed_5" 12 "NotUsed_4" 11 "NotUsed_3" 10 "NotUsed_2" 9 "NotUsed_1" 8 "TorqueReqNotHonored" 7 "MissingSignal" 6 "ModuleFault" 5 "HydroTempSensorFault" 4 "ClutchPressSensorFault" 3 "AccumPressSensorFault" 2 "ControlValveFault" 1 "MotorFault" 0 "Normal" ;
VAL_TABLE_ NotAllowed_Allowed 1 "Allowed" 0 "NotAllowed" ;
VAL_TABLE_ EngTrlrCnnct_D_Stat 3 "NotUsed_1" 2 "UnverifiedTrailer" 1 "HeavyTrailer" 0 "NoTrailer" ;
VAL_TABLE_ Faulty_FFFF 65535 "Faulty" ;
VAL_TABLE_ NoData_Faulty_3FFE_3FFF 16383 "Faulty" 16382 "NoDataExists" ;
VAL_TABLE_ Faulty_3FFF 16383 "Faulty" ;
VAL_TABLE_ NotExceeded_Exceeded 1 "Exceeded" 0 "NotExceeded" ;
VAL_TABLE_ EmgcyCall_D_Stat 7 "NotUsed_3" 6 "NotUsed_2" 5 "NotUsed_1" 4 "ManualEmergencyCall" 3 "AutoEmergencyCall" 2 "NoEvent" 1 "EmergencyCallNotSupported" 0 "Null" ;
VAL_TABLE_ NotAsserted_Asserted 1 "Asserted" 0 "NotAsserted" ;
VAL_TABLE_ GearLvr_D_ActlDrv 15 "Fault" 14 "Unknown_Position" 13 "NotUsed_2" 12 "NotUsed_1" 11 "Range6" 10 "Range5" 9 "Range4" 8 "Range3_M3_L3" 7 "Range2_M2_L2" 6 "Range1_M1_L1" 5 "Low" 4 "Sport_DriveSport_Mposition" 3 "Drive" 2 "Neutral" 1 "Reverse" 0 "Park" ;
VAL_TABLE_ ChrgrInPwMde_D_Actl 15 "NotUsed_5" 14 "NotUsed_4" 13 "NotUsed_3" 12 "NotUsed_2" 11 "NotUsed_1" 10 "DcBpt" 9 "DigitalCommEnd" 8 "EvseFault" 7 "EvseNotCompatible" 6 "IcCharging" 5 "DcCharging" 4 "AcDigital" 3 "AcBasic" 2 "DigitalCommDetected" 1 "EvsePaused" 0 "EvseNotDetected" ;
VAL_TABLE_ ChrgCordLck_D_Stat 7 "Faulty" 6 "LockFail" 5 "UnlockFail" 4 "LockInProgress" 3 "UnlockInProgress" 2 "Lock" 1 "Unlock" 0 "Retain" ;
VAL_TABLE_ OffOnNoDataFaulty 3 "Faulty" 2 "No_Data_Exists" 1 "On" 0 "Off" ;
VAL_TABLE_ NoMessage_Msg1_3 3 "Message3" 2 "Message2" 1 "Message1" 0 "NoMessage" ;
VAL_TABLE_ TrnRng_D_RqGsm 15 "Fault" 14 "UnknownPosition" 13 "Undefined_2" 12 "Undefined_1" 11 "_6" 10 "_5" 9 "_4" 8 "_3" 7 "_2" 6 "_1" 5 "Low" 4 "Sport_DriveSport" 3 "Drive" 2 "Neutral" 1 "Reverse" 0 "Park" ;
VAL_TABLE_ PrkBrkActv_D_RqGsmGear 3 "NotUsed" 2 "RequestParkBrakeEngage" 1 "NoRequest" 0 "Null" ;
VAL_TABLE_ TrnPrkSys_D_Actl 15 "Faulty" 14 "NotUsed_5" 13 "NotUsed_4" 12 "NotUsed_3" 11 "NotUsed_2" 10 "NotUsed_1" 9 "FrequencyError" 8 "OutOfRangeHigh" 7 "OutOfRangeLow" 6 "Override" 5 "OutOfPark" 4 "TransitionCloseToOutOfPark" 3 "AtNoSpring" 2 "TransitionCloseToPark" 1 "Park" 0 "NotKnown" ;
VAL_TABLE_ OKLowUnknownInvalid 3 "Invalid" 2 "Unknown" 1 "Low" 0 "OK" ;
VAL_TABLE_ PrkAidDrvDir_D_Stat 7 "NotUsed_2" 6 "NotUsed_1" 5 "BackwardNegative" 4 "ForwardNegative" 3 "BackwardPositive" 2 "ForwardPositive" 1 "NoMotion" 0 "DirectionNotKnown" ;
VAL_TABLE_ Pers1Phone_D_Stat 7 "SevenPhoneAssociated" 6 "SixPhoneAssociated" 5 "FivePhoneAssociated" 4 "FourPhoneAssociated" 3 "ThreePhoneAssociated" 2 "TwoPhoneAssociated" 1 "OnePhoneAssociated" 0 "NoPhoneAssociated" ;
VAL_TABLE_ EngExhMdeQuiet_D2_Stat 7 "Faulty" 6 "NotUsed_2" 5 "NotUsed_1" 4 "Track" 3 "Sport" 2 "Normal" 1 "Stealth" 0 "Null" ;
VAL_TABLE_ GasPrtc_D_RqDsply 7 "NotUsed_5" 6 "NotUsed_4" 5 "NotUsed_3" 4 "NotUsed_2" 3 "NotUsed_1" 2 "GpfOverLimit" 1 "GpfAtLimit" 0 "NormalOperation" ;
VAL_TABLE_ Faulty_7FF 2047 "Faulty" ;
VAL_TABLE_ PwSrcULowMde_D_Actl 3 "BuckSpecial" 2 "ReverseBoost" 1 "ForwardBuck" 0 "Standby" ;
VAL_TABLE_ CamraViewSplit_D_Actl 3 "NotUsed" 2 "Inactive" 1 "Active" 0 "Invalid" ;
VAL_TABLE_ ApaTrgtDist_D_Stat 15 "Step15" 14 "Step14" 13 "Step13" 12 "Step12" 11 "Step11" 10 "Step10" 9 "Step9" 8 "Step8" 7 "Step7" 6 "Step6" 5 "Step5" 4 "Step4" 3 "Step3" 2 "Step2" 1 "Step1" 0 "Off" ;
VAL_TABLE_ ApaMsgTxt_D_Rq 15 "NotUsed_6" 14 "NotUsed_5" 13 "NotUsed_4" 12 "NotUsed_3" 11 "ReleaseEpb" 10 "TrailerFeatureNotAvailable" 9 "AccelPedalInactive" 8 "WrongDirection" 7 "SteeringInteraction" 6 "BrakingActive" 5 "HighInclination" 4 "SpeedLimitExceeded" 3 "TcsDisabled" 2 "WheelSlip" 1 "None" 0 "Null" ;
VAL_TABLE_ Memory_2_SwPsngr_Stat 1 "Pressed" 0 "Null" ;
VAL_TABLE_ Pers3Key_D_Stat 3 "NotUsed_1" 2 "KeyUnAssociated" 1 "KeyAssociated" 0 "Null" ;
VAL_TABLE_ PwSrcULoMde_D_Rq 3 "BuckSpecial" 2 "ReverseBoost" 1 "ForwardBuck" 0 "Standby" ;
VAL_TABLE_ WakeAlarm0_B_Typ 1 "CanAndEcuDriveCircuit" 0 "CanOnly" ;
VAL_TABLE_ WakeAlarm0_D_Stat 3 "PublisherReset" 2 "Wake" 1 "AlarmRunning" 0 "AlarmOff" ;
VAL_TABLE_ EmPrflNo_D_Rq 7 "NotUsed_3" 6 "NotUsed_2" 5 "NotUsed_1" 4 "Pers4" 3 "Pers3" 2 "Pers2" 1 "Pers1" 0 "Null" ;
VAL_TABLE_ EmPrflKeyAssoc_D_Rq 7 "NotUsed_3" 6 "DisassociatePhone" 5 "EnterPhoneAssociation" 4 "OverwriteKey" 3 "DisassociateKey" 2 "ExitKeyAssociation" 1 "EnterKeyAssociation" 0 "Null" ;
VAL_TABLE_ Em_D_Stat 3 "NotSupported" 2 "ProfilesOff" 1 "ProfilesOn" 0 "Null" ;
VAL_TABLE_ EmButtn_D_Stat 7 "ButtonAssociationFailed" 6 "ButtonAssociationExited" 5 "ButtonAssociationEntered" 4 "Button4Pressed" 3 "Button3Pressed" 2 "Button2Pressed" 1 "Button1Pressed" 0 "Null" ;
VAL_TABLE_ EmPrflNo_D_Stat 7 "NotUsed_3" 6 "NotUsed_2" 5 "NotUsed_1" 4 "Pers4" 3 "Pers3" 2 "Pers2" 1 "Pers1" 0 "Null" ;
VAL_TABLE_ EmPrflKeyAssoc_D_Stat 7 "WrongDevice" 6 "KeyAssociateFailed" 5 "KeyAssociateSuccess" 4 "KeyAlreadyInUse" 3 "KeyDisassociated" 2 "KeyAssociationExited" 1 "KeyAssociationEntered" 0 "Null" ;
VAL_TABLE_ PersNo_D_Actl 7 "Unused_3" 6 "Unused_2" 5 "NotDetermined" 4 "Vehicle" 3 "PERS_4" 2 "PERS_3" 1 "PERS_2" 0 "PERS_1" ;
VAL_TABLE_ WiprFront_D_Stat2 15 "NO_DATA_EXISTS" 14 "STALLED" 13 "NotUsed" 12 "AUTO_ADJUST" 11 "COURTESYWIPE" 10 "AUTO_HIGH" 9 "AUTO_LOW" 8 "WASH" 7 "MIST_FLICK" 6 "MAN_HIGH" 5 "MAN_LOW" 4 "MAN_INT_ON" 3 "MAN_INT_OFF" 2 "OFF_MOVING" 1 "AUTO_OFF" 0 "OFF" ;
VAL_TABLE_ TurnLghtSwtch_D_Stat2 3 "NotUsed" 2 "Right" 1 "Left" 0 "Off" ;
VAL_TABLE_ SelDrvMdePos01_D_Stat 31 "Faulty" 30 "SelDrvMde31" 29 "SelDrvMde30" 28 "SelDrvMde29" 27 "SelDrvMde28" 26 "SelDrvMde27" 25 "SelDrvMde26" 24 "SelDrvMde25" 23 "SelDrvMde24" 22 "SelDrvMde23" 21 "SelDrvMde22" 20 "SelDrvMde21" 19 "SelDrvMde20" 18 "SelDrvMde19" 17 "SelDrvMde18" 16 "SelDrvMde17" 15 "SelDrvMde16" 14 "SelDrvMde15" 13 "SelDrvMde14" 12 "SelDrvMde13" 11 "SelDrvMde12" 10 "SelDrvMde11" 9 "SelDrvMde10" 8 "SelDrvMde09" 7 "SelDrvMde08" 6 "SelDrvMde07" 5 "SelDrvMde06" 4 "SelDrvMde05" 3 "SelDrvMde04" 2 "SelDrvMde03" 1 "SelDrvMde02" 0 "SelDrvMde01" ;
VAL_TABLE_ ImmedFastMediumSlow 3 "Slow" 2 "Medium" 1 "Fast" 0 "Immediately" ;
VAL_TABLE_ AdbHiBeamKeepOff_D_Rq 3 "KeepBothOff" 2 "KeepLeftOff" 1 "KeepRightOff" 0 "BothFreeRunning" ;
VAL_TABLE_ AdbLampOnOff_D_Rq 3 "BothOn" 2 "LeftOnRightOff" 1 "RightOnLeftOff" 0 "BothOff" ;
VAL_TABLE_ Fault_Occupied_Empty_Un 3 "Unknown" 2 "Empty" 1 "Occupied" 0 "Fault" ;
VAL_TABLE_ Off_On_Flash_Triggered 3 "Triggered" 2 "Flash" 1 "On" 0 "Off" ;
VAL_TABLE_ KeyOffMde_D_Actl 15 "NotUsed_11" 14 "NotUsed_10" 13 "NotUsed_9" 12 "NotUsed_8" 11 "NotUsed_7" 10 "NotUsed_6" 9 "NotUsed_5" 8 "NotUsed_4" 7 "NotUsed_3" 6 "NotUsed_2" 5 "NotUsed_1" 4 "CriticalBattery" 3 "Hibernate" 2 "Transport" 1 "Factory" 0 "Normal" ;
VAL_TABLE_ IaccVLim_D_Rq 252 "NotUsed_2" 250 "LimitSpeed_250" 240 "LimitSpeed_240" 230 "LimitSpeed_230" 220 "LimitSpeed_220" 210 "LimitSpeed_210" 200 "LimitSpeed_200" 190 "LimitSpeed_190" 150 "LimitSpeed_150" 140 "LimitSpeed_140" 130 "LimitSpeed_130" 120 "LimitSpeed_120" 110 "LimitSpeed_110" 100 "LimitSpeed_100" 90 "LimitSpeed_90" 80 "LimitSpeed_80" 70 "LimitSpeed_70" 60 "LimitSpeed_60" 50 "LimitSpeed_50" 40 "LimitSpeed_40" 30 "LimitSpeed_30" 20 "LimtSpeed_20" 251 "NotUsed_1" 255 "Faulty" 254 "NoDataExists" 253 "NotUsed_3" 180 "LimitSpeed_180" 179 "LimitSpeed_179" 178 "LimitSpeed_178" 177 "LimitSpeed_177" 176 "LimitSpeed_176" 175 "LimitSpeed_175" 174 "LimitSpeed_174" 173 "LimitSpeed_173" 172 "LimitSpeed_172" 171 "LimitSpeed_171" 170 "LimitSpeed_170" 169 "LimitSpeed_169" 168 "LimitSpeed_168" 167 "LimitSpeed_167" 166 "LimitSpeed_166" 165 "LimitSpeed_165" 164 "LimitSpeed_164" 163 "LimitSpeed_163" 162 "LimitSpeed_162" 161 "LimitSpeed_161" 160 "LimitSpeed_160" 15 "LimitSpeed_15" 14 "LimitSpeed_14" 13 "LimitSpeed_13" 12 "LimitSpeed_12" 11 "LimitSpeed_11" 10 "LimitSpeed_10" 9 "LimitSpeed_9" 8 "LimitSpeed_8" 7 "LimitSpeed_7" 6 "LimitSpeed_6" 5 "LimitSpeed_5" 4 "LimitSpeed_4" 3 "LimitSpeed_3" 2 "LimitSpeed_2" 1 "LimitSpeed_1" 0 "LimitSpeed_0" ;
VAL_TABLE_ IaccVLimUnit_D_Rq 3 "NoDataExists" 2 "Mph" 1 "Kph" 0 "Null" ;
VAL_TABLE_ SelDrvMdeAwd_D_Rq 31 "Faulty" 30 "NotUsed_17" 29 "NotUsed_16" 28 "NotUsed_15" 27 "NotUsed_14" 26 "NotUsed_13" 25 "NotUsed_12" 24 "NotUsed_11" 23 "NotUsed_10" 22 "NotUsed_9" 21 "NotUsed_8" 20 "CustomMode" 19 "OnePedalDrive" 18 "DragMode" 17 "EvLaterChargeMode" 16 "EvNowMode" 15 "TrackMode" 14 "RoughRoadMode" 13 "NotAvailable" 12 "HighSpeedDesertMode_Baja" 11 "SportAdaptiveMode" 10 "RockCrawlMode" 9 "MudRutsMode" 8 "SandMode" 7 "EconomyMode" 6 "GrassGravelSnow" 5 "TowHaulMode" 4 "SportMode" 3 "Normal_4L" 2 "Normal_4A" 1 "Normal_2H" 0 "NormalMode" ;
VAL_TABLE_ SelDrvMdeAwd_D_Stat 0 "NotAvailable" 1 "Available" 2 "TemporarilyNotAvailable" 3 "Faulty" ;
VAL_TABLE_ RearDiffLckMsg2_D_Rq 15 "NotUsed_3" 14 "NotUsed_2" 13 "NotUsed_1" 12 "ElsdReduced" 11 "LockingFeatureNotAvailable" 10 "EsldOff" 9 "ElsdRestored" 8 "ElsdOverheated" 7 "Locker_Disabled" 6 "Locker_Enabled" 5 "LockerSpeed5" 4 "LockerSpeed4" 3 "LockerSpeed3" 2 "LockerSpeed2" 1 "LockerSpeed1" 0 "NormalNoMessage " ;
VAL_TABLE_ EmgcyAsstActv_D_Stat 3 "ConfiguredOff" 2 "Active" 1 "Inactive" 0 "Null" ;
VAL_TABLE_ HeadLghtHiPrmsn_D_Stat 3 "CancelAndSuppress" 2 "Cancel" 1 "Hold" 0 "AllowChange" ;
VAL_TABLE_ SelDrvMdeSwtch 3 "Faulty" 2 "SwitchState2" 1 "SwitchState1" 0 "NotPressed" ;
VAL_TABLE_ ChrgCompltMsgTxt_D_Rq 3 "NotUsed_1" 2 "ChargeToFull" 1 "ChargeToFastChargeLimit" 0 "DefaultLabel" ;
VAL_TABLE_ AwdDrvMde 7 "Faulty" 6 "NotAvailable" 5 "RockCrawl" 4 "Baja" 3 "MudAndSand" 2 "Weather" 1 "Sport" 0 "Normal" ;
VAL_TABLE_ SelDrvMdePt_D_Rq 31 "Faulty" 30 "NotUsed15" 29 "NotUsed14" 28 "NotUsed13" 27 "NotUsed12" 26 "NotUsed11" 25 "NotUsed10" 24 "NotUsed9" 23 "NotUsed8" 22 "NotUsed7" 21 "CustomMode" 20 "TrackMode" 19 "OnePedalDrive" 18 "EvLaterChargerMode" 17 "EvNowMode" 16 "DragMode" 15 "HighSpeedDesertMode_Baja" 14 "SportAdaptiveMode" 13 "NotAvailable_13" 12 "NotAvailable_12" 11 "NotAvailable_11" 10 "NotAvailable_10" 9 "RockCrawlMode" 8 "MudRutsMode" 7 "SandMode" 6 "EconomyMode" 5 "GrassGravelSnow" 4 "NotAvailable_04" 3 "TowHaulMode" 2 "NotAvailable_02" 1 "SportMode" 0 "NormalMode" ;
VAL_TABLE_ OffLockUnlockFaulty 3 "Faulty" 2 "Unlock" 1 "Lock" 0 "Off" ;
VAL_TABLE_ OffOnOutOfRange 3 "NotUsed" 2 "OutOfRange" 1 "On" 0 "Off" ;
VAL_TABLE_ NoMessage_Msg1_15 15 "Message15" 14 "Message14" 13 "Message13" 12 "Message12" 11 "Message11" 10 "Message10" 9 "Message9" 8 "Message8" 7 "Message7" 6 "Message6" 5 "Message5" 4 "Message4" 3 "Message3" 2 "Message2" 1 "Message1" 0 "NoMessage" ;
VAL_TABLE_ NotAvailable_Available 1 "Available" 0 "NotAvailable" ;
VAL_TABLE_ PwStep_D_DrvInhbt 3 "NotUsed" 2 "DriveInhibitMalfunction" 1 "DriveInhibited" 0 "DriveNotInhibited" ;
VAL_TABLE_ NoMessage_Msg1_31 31 "Message31" 30 "Message30" 29 "Message29" 28 "Message28" 27 "Message27" 26 "Message26" 25 "Message25" 24 "Message24" 23 "Message23" 22 "Message22" 21 "Message21" 20 "Message20" 19 "Message19" 18 "Message18" 17 "Message17" 16 "Message16" 15 "Message15" 14 "Message14" 13 "Message13" 12 "Message12" 11 "Message11" 10 "Message10" 9 "Message9" 8 "Message8" 7 "Message7" 6 "Message6" 5 "Message5" 4 "Message4" 3 "Message3" 2 "Message2" 1 "Message1" 0 "NoMessage" ;
VAL_TABLE_ TrnRng_D_RqFap 7 "NotUsed3" 6 "NotUsed2" 5 "NotUsed1" 4 "Backwards" 3 "Forwards" 2 "NoMotion" 1 "Immobilize" 0 "NoRequest" ;
VAL_TABLE_ FuelLvlWarn_D_ActlEng 7 "DteLevel5Lowest" 6 "DteLevel4" 5 "DteLevel3" 4 "DteLevel2NonMyKey" 3 "DteLevel1MyKey" 2 "VeryLow" 1 "Low" 0 "OK" ;
VAL_TABLE_ OffLowMedHigh 3 "High" 2 "Medium" 1 "Low" 0 "Off" ;
VAL_TABLE_ RstrnMdulePw_D_Falt 3 "NotUsed_1" 2 "NoFault" 1 "Fault" 0 "Null" ;
VAL_TABLE_ HeadLghtHiCtrl_D_RqAhb 7 "NotUsed2" 6 "NotUsed1" 5 "Auto_HiBeam" 4 "Auto_LoBeam" 3 "Flash" 2 "Man_HiBeam" 1 "Man_LoBeam" 0 "Null" ;
VAL_TABLE_ AhbHiBeam_D_Rq 3 "NotUsed" 2 "HighBeamRecommended" 1 "LowBeamRecommended" 0 "DeactivatedUnavailable" ;
VAL_TABLE_ AhbcRampingV_D_Rq 3 "Slow" 2 "Medium" 1 "Fast" 0 "Immediately" ;
VAL_TABLE_ ApaGearShif_D_RqDrv 7 "NotUSed2" 6 "NotUsed1" 5 "ShiftToP" 4 "ShiftToN" 3 "ShiftToD" 2 "ShiftToR" 1 "NoRequest" 0 "Null" ;
VAL_TABLE_ ApaLongCtl_D_RqDrv 7 "NotUsed3" 6 "NotUsed2" 5 "ReleaseBrake" 4 "DriveBackward" 3 "DriveForward" 2 "Stop" 1 "NoRequest" 0 "Null" ;
VAL_TABLE_ ApaActvSide2_D_Stat 3 "NoSide" 2 "Right" 1 "Left" 0 "Null" ;
VAL_TABLE_ ApaScan_D_Stat 3 "ParkSlotReady" 2 "ParkSlotFound" 1 "NoParkSlot" 0 "Null" ;
VAL_TABLE_ ApaSelSapp_D_Stat 3 "NotConfigured" 2 "NotSelectable" 1 "Selectable" 0 "Null" ;
VAL_TABLE_ ApaSys_D_Stat 7 "Faulty" 6 "Finished" 5 "NotAccessible" 4 "ApaCancelled" 3 "Overspeed" 2 "On" 1 "Off" 0 "Null" ;
VAL_TABLE_ ApaSteScanMde_D_Stat 3 "Steering" 2 "Scanning" 1 "NotScanning" 0 "Null" ;
VAL_TABLE_ ApaAcsy_D_RqDrv 7 "CloseDoor" 6 "SelectSideRight" 5 "SelectSideLeft" 4 "CheckForObject" 3 "PressApaButton" 2 "SelectSide" 1 "NoRequest" 0 "Null" ;
VAL_TABLE_ ApaSteWhl_D_RqDrv 3 "TakeControl" 2 "RemoveHands" 1 "NoRequest" 0 "Null" ;
VAL_TABLE_ WiprFrontSwtch_D_Stat 15 "NotUsed6" 14 "NotUsed5" 13 "NotUsed4" 12 "NotUsed3" 11 "NotUsed2" 10 "NotUsed1" 9 "PositionNotDetermined" 8 "High" 7 "Low" 6 "Position6" 5 "Position5" 4 "Position4" 3 "Position3" 2 "Position2" 1 "Position1" 0 "Off" ;
VAL_TABLE_ Chirp_D_RqTrlr 3 "NotUsed" 2 "Chirp_2" 1 "Chirp_1" 0 "NoRequest" ;
VAL_TABLE_ Off_On_Unknown_Invalid 3 "Invalid" 2 "Unknown" 1 "On" 0 "Off" ;
VAL_TABLE_ Unknown_7FFE_Invalid_7FFF 32767 "Invalid" 32766 "Unknown" ;
VAL_TABLE_ OffOnNotUsedFaulty 3 "Faulty" 2 "NotUsed" 1 "On" 0 "Off" ;
VAL_TABLE_ HeadLghtOn_D_Rq 7 "NotUsed2" 6 "NotUsed1" 5 "DrlBoth" 4 "DrlRight" 3 "DrlLeft" 2 "High" 1 "Low" 0 "Off" ;
VAL_TABLE_ PoliceIdlMde_D_Stat 15 "NotUsed_7" 14 "NotUsed_6" 13 "NotUsed_5" 12 "NotUsed_4" 11 "NotUsed_3" 10 "UtilityIdleActive" 9 "PepsActive" 8 "Decommissioned" 7 "ActiveFault" 6 "ArmFault" 5 "PrearmedFault" 4 "OffFault" 3 "Active" 2 "Arm" 1 "Prearmed" 0 "Off" ;
VAL_TABLE_ GrdAsstAllw_D_DsplyPt 3 "NotUsed" 2 "On" 1 "Off" 0 "NoModeSelected" ;
VAL_TABLE_ PrkBrkMsgTxt_D_Rq 15 "Message15" 14 "Message14" 13 "Message13" 12 "Message12" 11 "Message11" 10 "Message10" 9 "Message9" 8 "Message8" 7 "Message7" 6 "Message6" 5 "Message5" 4 "Message4" 3 "Message3" 2 "Message2" 1 "Message1" 0 "No_Message" ;
VAL_TABLE_ AutoRgenTxt_B_RqDsply 1 "AutExhFilterCleanOFF" 0 "AutExhFilterCleanON" ;
VAL_TABLE_ TrnGearMsgTxt_D_Rq 15 "Message_15" 14 "Message_14" 13 "Message_13" 12 "Message_12" 11 "Message_11" 10 "Message_10" 9 "Message_9" 8 "Message_8" 7 "Message_7" 6 "Message_6" 5 "Message_5" 4 "Message_4" 3 "Message_3" 2 "Message_2" 1 "Message_1" 0 "NoMessage" ;
VAL_TABLE_ ACU_AutoStoreResult_St 2 "No_Station_Found" 1 "Inactive" 0 "Invalid" ;
VAL_TABLE_ ACU_DirectTune_St 2 "Valid_Station" 1 "Invalid_Station" 0 "Invalid" ;
VAL_TABLE_ ACU_RadioSeekMode2_St 16 "ContAutoDown" 15 "ContAutoUp" 14 "PISeek" 13 "TpSeek" 12 "Autostore" 11 "PtySeekDown" 10 "PtySeekUp" 9 "ScanDown" 8 "ScanUp" 7 "ContManualDown" 6 "ContManualUp" 5 "ManSingleStepDown" 4 "ManSingleStepUp" 3 "AutoDown" 2 "AutoUp" 1 "SeekOff" 0 "Invalid" ;
VAL_TABLE_ ACU_CurrTUBand_St 10 "SAT2" 9 "SAT1" 8 "DAB2" 7 "DAB1" 6 "Fm3" 5 "AmAst" 4 "Am" 3 "FmAst" 2 "Fm2" 1 "Fm1" 0 "Invalid" 13 "reserved1" 15 "reserved_last" 12 "DAB3" 11 "SAT3" ;
VAL_TABLE_ ChargeProfIDPref_Rq 3 "NotUsed" 2 "Value" 1 "ChargeNow" 0 "Inactive" ;
VAL_TABLE_ EngExhMdeQuiet_D_Stat 3 "Faulty" 2 "QuietExhaust" 1 "LoudExhaust" 0 "Null" ;
VAL_TABLE_ GearSelLck_D_Rq 3 "PreventionBlocker" 2 "Unlock" 1 "Lock" 0 "Null" ;
VAL_TABLE_ SuspDrvMde_D_Rq 7 "Faulty" 6 "NotUsed2" 5 "NotUsed1" 4 "Drag" 3 "Track" 2 "Snow_Wet" 1 "Sport" 0 "Normal" ;
VAL_TABLE_ NotPressed_PressedNotUsed 3 "NotUsed2" 2 "NotUsed1" 1 "Pressed" 0 "Not_Pressed" ;
VAL_TABLE_ WhlRearDual_D_Stat 3 "NotUsed" 2 "Dual" 1 "Single" 0 "NoDataExists" ;
VAL_TABLE_ TracKeyMde_D_Stat 3 "NotUsed" 2 "NotActive" 1 "Active" 0 "ModeNotDetermined" ;
VAL_TABLE_ TrnManShifGear_D_IndDrv 7 "Indicate_Reverse_Gear" 6 "Indicate_Gear6" 5 "Indicate_Gear5" 4 "Indicate_Gear4" 3 "Indicate_Gear3" 2 "Indicate_Gear2" 1 "Indicate_Gear1" 0 "No_Indication" ;
VAL_TABLE_ LsmcBrkDecel_D_Stat 7 "NotUsed_3" 6 "NotUsed_2" 5 "NotUsed_1" 4 "Denied" 3 "FaultDegraded" 2 "FaultExt" 1 "On" 0 "Off" ;
VAL_TABLE_ OffOn_RampUpDown 3 "Ramp_Down" 2 "Ramp_Up" 1 "On" 0 "Off" ;
VAL_TABLE_ DieslMsgTxt_D_Rq 3 "NotUsed2" 2 "NotUsed1" 1 "ReducedEnginePower" 0 "NoMessage" ;
VAL_TABLE_ NoMessage_Msg1_7 7 "Message7" 6 "Message6" 5 "Message5" 4 "Message4" 3 "Message3" 2 "Message2" 1 "Message1" 0 "NoMessage" ;
VAL_TABLE_ LnchCtl 3 "NotUsed2" 2 "NotUsed1" 1 "LC_On" 0 "LC_Off" ;
VAL_TABLE_ LnchCtlSys_D_Stat 7 "NotUsed3" 6 "NotUsed2" 5 "NotUsed1" 4 "On_LC_Unavailable_TC_On" 3 "On_LC_Unavailable" 2 "On_LC_Available" 1 "On_LC_Active" 0 "LC_OFF" ;
VAL_TABLE_ Rght_Lefthand_Traffic 1 "Left_Hand_Traffic" 0 "Right_Hand_Traffic" ;
VAL_TABLE_ IsaOffst_D_Stat 15 "Faulty" 14 "Null" 13 "Thirteen" 12 "Twelve" 11 "Eleven" 10 "Ten" 9 "Nine" 8 "Eight" 7 "Seven" 6 "Six" 5 "Five" 4 "Four" 3 "Three" 2 "Two" 1 "One" 0 "Zero" ;
VAL_TABLE_ IsaVLimUnit_D_Rq 3 "NoDataExists" 2 "Mph" 1 "Kph" 0 "Null" ;
VAL_TABLE_ ApaChime_D_Rq 7 "NotUsed2" 6 "NotUsed1" 5 "Warning_Chime" 4 "Finish_Chime" 3 "Stop_Now_Chime" 2 "Spot_Ready_Chime" 1 "Spot_Found_Chime" 0 "No_Chime" ;
VAL_TABLE_ SlMde_D_RqDsply 3 "NotUsed" 2 "ManualSpeed_LimiterSymbol" 1 "AutoSpeed_LimiterSymbol" 0 "NoSpeed_LimiterSymbol" ;
VAL_TABLE_ SlMde_D_Rq 3 "IsaNotConfigured" 2 "Manual_Mode" 1 "Auto_Mode" 0 "Null" ;
VAL_TABLE_ Faulty_FF 255 "Faulty" ;
VAL_TABLE_ BrkDrvMde_D_Rq 7 "Faulty" 6 "RockCrawl" 5 "Baja" 4 "DragOrMudAndSand" 3 "Track" 2 "Snow_Wet" 1 "Sport" 0 "Normal" ;
VAL_TABLE_ NoYesNoDataFaulty 3 "Faulty" 2 "NoDataExists" 1 "Yes" 0 "No" ;
VAL_TABLE_ SidePrkSnsR4_D_Stat 15 "NotUsed" 14 "NotFullyScannedYet" 13 "NoObjectInSector" 12 "Zone12" 11 "Zone11" 10 "Zone10" 9 "Zone9" 8 "Zone8" 7 "Zone7" 6 "Zone6" 5 "Zone5" 4 "Zone4" 3 "Zone3" 2 "Zone2" 1 "Zone1" 0 "Off" ;
VAL_TABLE_ PtDrvMde_D_Rq 15 "Faulty" 14 "NotUsed11" 13 "NotUsed10" 12 "NotUsed9" 11 "NotUsed8" 10 "NotUsed7" 9 "NotUsed6" 8 "Track" 7 "Drag" 6 "Rock" 5 "Baja" 4 "Sand" 3 "TowHaulGradeAssist" 2 "SnowWet" 1 "Sport" 0 "Normal" ;
VAL_TABLE_ SteEffort_D_Stat 7 "NotUsed_3" 6 "NotUsed_2" 5 "NotUsed_1" 4 "SpecialMode_2" 3 "SpecialMode_1" 2 "Comfort" 1 "Sport" 0 "Normal" ;
VAL_TABLE_ Null_Off_On 3 "NotUsed" 2 "On" 1 "Off" 0 "Null" ;
VAL_TABLE_ NoData_Faulty_E_F 15 "Faulty" 14 "NoDataExists" ;
VAL_TABLE_ Invalid_7F 127 "Invalid" ;
VAL_TABLE_ Faulty_1FFF 8191 "Faulty" ;
VAL_TABLE_ VehStab_D_Stat 15 "Faulty" 14 "No_Data_Exists" 13 "NotUsed6" 12 "NotUsed5" 11 "NotUsed4" 10 "NotUsed3" 9 "NotUsed2" 8 "Combined_OS_and_US" 7 "High_SSRA_no_OS" 6 "Straight" 5 "Post_Oversteer" 4 "Post_Transition" 3 "Countersteer" 2 "Understeer" 1 "Oversteer" 0 "Linear" ;
VAL_TABLE_ FohEng_D_Rq 3 "AutoEnable_ParkEnable" 2 "AutoDisable_ParkEnable" 1 "AutoEnable_ParkDisable" 0 "Disable_Stop" ;
VAL_TABLE_ Null_Hi_NotUsed_Low 3 "Low" 2 "Not_Used" 1 "High" 0 "Null" ;
VAL_TABLE_ Current_Color 15 "NotUsed7" 14 "NotUsed6" 13 "NotUsed5" 12 "NotUsed4" 11 "NotUsed3" 10 "NotUsed2" 9 "NotUsed1" 8 "Null" 7 "Color7" 6 "Color6" 5 "Color5" 4 "Color4" 3 "Color3" 2 "Color2" 1 "Color1" 0 "Off" ;
VAL_TABLE_ Blended_Color 15 "NotUsed10" 14 "NotUsed9" 13 "NotUsed8" 12 "NotUsed7" 11 "NotUsed6" 10 "NotUsed5" 9 "NotUsed4" 8 "NotUsed3" 7 "NotUsed2" 6 "NotUsed1" 5 "_5" 4 "_4" 3 "_3" 2 "_2" 1 "_1" 0 "Null" ;
VAL_TABLE_ OffOn_Null_NotUsed 3 "NotUsed" 2 "Null" 1 "On" 0 "Off" ;
VAL_TABLE_ DieslPrtc2_D_RqDsply 15 "NotUsed4" 14 "NotUsed3" 13 "NotUsed2" 12 "NotUsed1" 11 "OCR_ExhFilterClean_Stopped" 10 "OCR_ExhFilterCleaned" 9 "RgnOff_AtLimit" 8 "RgnOff_Overloaded" 7 "RgnOff_Loaded" 6 "Exhaust_Filter_Full" 5 "DPF_Overlimit" 4 "DPF_AtLimit" 3 "ExhFilter_Drive_Completed" 2 "Cleaning_Exhaust_Filter" 1 "DPF_Overloaded" 0 "DPF_Normal_Operation" ;
VAL_TABLE_ Null_Pers1_4_Vehicle 7 "Unused_2" 6 "Unused_1" 5 "Vehicle" 4 "PERS_4" 3 "PERS_3" 2 "PERS_2" 1 "PERS_1" 0 "Null" ;
VAL_TABLE_ PrkLckCtlEnbl_D_RqIpc 3 "Rq_Towing" 2 "Rq_Enable" 1 "Rq_Disable" 0 "Null" ;
VAL_TABLE_ PrkLckCtlUnlck_D_Stat 3 "Trans_And_Steer_Unlckd" 2 "Steering_Unlckd" 1 "Transmission_Unlckd" 0 "Null" ;
VAL_TABLE_ VehKeyActv_D_Stat 15 "NotUsed7" 14 "NotUsed6" 13 "NotUsed5" 12 "NotUsed4" 11 "NotUsed3" 10 "NotUsed2" 9 "NotUsed1" 8 "Key8Active" 7 "Key7Active" 6 "Key6Active" 5 "Key5Active" 4 "Key4Active" 3 "Key3Active" 2 "Key2Active" 1 "Key1Active" 0 "NoKeyActive" ;
VAL_TABLE_ VehLckInd_D_Rq 3 "NotUsed" 2 "On_Day" 1 "On_Night" 0 "Off" ;
VAL_TABLE_ PrkBrkDynmc_D_Allw 3 "NotUsed" 2 "EPB_ECD_NotPossible" 1 "EPB_ECD_Possible" 0 "Used_at_Start_Up" ;
VAL_TABLE_ NoData_Faulty_3E_3F 63 "Faulty" 62 "NoDataExists" ;
VAL_TABLE_ Unknown_Invalid_3E_3F 63 "Invalid" 62 "Unknown" ;
VAL_TABLE_ Faulty_1FF 511 "Faulty" ;
VAL_TABLE_ NoData_Faulty_1FFF_1FFE 8191 "Faulty" 8190 "NoDataExists" ;
VAL_TABLE_ Null_Off_On_Faulty 3 "Faulty" 2 "On" 1 "Off" 0 "Null" ;
VAL_TABLE_ AwdSys_D_Stat 3 "Faulty" 2 "NotUsed" 1 "_4x4_L_H_Active" 0 "_4x4_L_H_Inactive" ;
VAL_TABLE_ EmotiveType_D_Dsply 3 "EmotiveDisplay_3" 2 "EmotiveDisplay_2" 1 "EmotiveDisplay_1" 0 "Null" ;
VAL_TABLE_ TrnSrvcRqd_B_Rq 1 "On" 0 "Off" ;
VAL_TABLE_ immoSecureIdleMode 3 "NotUsed2" 2 "NotUsed1" 1 "Active" 0 "Inactive" ;
VAL_TABLE_ SteMdule_D_Stat 7 "NotUsed" 6 "EPAS_Failure3" 5 "EPAS_Failure2" 4 "System_Failure" 3 "EPAS_Shutdown" 2 "Normal_Op_Full_Assist" 1 "Normal_Op_Limited_Assist" 0 "EPAS_Initialization" ;
VAL_TABLE_ Faulty_FFF 4095 "Faulty" ;
VAL_TABLE_ Faulty_3FF 1023 "Faulty" ;
VAL_TABLE_ Invalid_F 15 "Invalid" ;
VAL_TABLE_ Invalid_1F 31 "Invalid" ;
VAL_TABLE_ NoData_Faulty_FE_FF 255 "Faulty" 254 "NoDataExists" ;
VAL_TABLE_ PtRmtRprt_D_Rq 15 "NotUsed_4" 14 "NotUsed_3" 13 "NotUsed_2" 12 "PlugInToMaintain12vBattery" 11 "SettingUpdated" 10 "FastChargeComplete" 9 "ChargeNotOccurring" 8 "OneTimeSocReached" 7 "BatteryTemperatureReminder" 6 "ReducedPerformance" 5 "LimitedPerformance" 4 "ChargeFault" 3 "ChargeComplete" 2 "VehiclePreconditioned" 1 "TripDistanceAchieved" 0 "NoReportRequest" ;
VAL_TABLE_ Invalid_NotReq_Req 0 "Invalid" 1 "Not_Requested" 2 "Requested" 3 "NotUsed" ;
VAL_TABLE_ Inactive_NotReq_Req 0 "Inactive" 1 "Not_Requested" 2 "Requested" 3 "NotUsed" ;
VAL_TABLE_ BattElecPerf_D_Actl 7 "NotUsed" 6 "Hot_Batt_Severe_Lim_Perf" 5 "Hot_Batt_Reduced_Perf" 4 "Hot_Batt_Close_to_lim_Per" 3 "Cold_Batt_Severe_Lim_Perf" 2 "Cold_Batt_Reduced_Perf" 1 "Cold_Batt_Close_to_lim_Pe" 0 "Ok_no_message_displayed" ;
VAL_TABLE_ ChkPlgtoStrt_D_Dsply 3 "NotUsed" 2 "Is_VehicleUnplugged_Prompt" 1 "Check_Plug_to_Start" 0 "No_Message_Display" ;
VAL_TABLE_ PwrFlowTxt_D_Dsply 15 "NotUsed7" 14 "NotUsed6" 13 "NotUsed5" 12 "NotUsed4" 11 "Disply_Rgen_Chrg_Txt" 10 "Disp_Fast_Charge_Txt" 9 "Disp_Fast_Charge_Cmplt_Txt" 8 "Disp_Charge_Cmplt_Txt" 7 "Disp_Remote_Start_Txt" 6 "Disp_Eng_Drv_Txt" 5 "Disp_Elec_Drv_Txt" 4 "Disp_Idle_with_Chrg_Txt" 3 "Disp_Idle_Txt" 2 "Disp_Charg_HV_Batt_Txt" 1 "Disp_Hyb_Drive_Txt" 0 "No_Text" ;
VAL_TABLE_ EngOnMsg_D_Dsply 14 "_0xE_to_1F_NotUsed" 12 "Battery_Temperature" 11 "Hill_Decent_Control" 10 "Fuel_Maintenance" 9 "Oil_Maintenance" 8 "Normal_Operation" 7 "Low_Gear" 6 "Batt_Charging" 5 "Engine_Cold" 4 "Neutral_Gear" 3 "Heater_Setting" 2 "High_Speed" 1 "Acceleration" 0 "No_Display" 13 "Drive_Mode_Selection" ;
VAL_TABLE_ PtDataKeyId_D_Stat 15 "NotUsed5" 14 "NotUsed4" 13 "NotUsed3" 12 "NotUsed2" 11 "NotUsed1" 10 "Tot_Veh_NUT" 9 "Cust_4_NUT" 8 "Cust_3_NUT" 7 "Cust_2_NUT" 6 "Cust_1_NUT" 5 "Tot_Veh_Stat" 4 "Cust_4_Stat" 3 "Cust_3_Stat" 2 "Cust_2_Stat" 1 "Cust_1_Stat" 0 "Null" ;
VAL_TABLE_ ChrgStat_D_Dsply 7 "NotUsed" 6 "Complete" 5 "Scheduled" 4 "In_Progress" 3 "Fault_Outside_Car" 2 "Fault_Inside_Car" 1 "Fault_Unknown_Location" 0 "Not_Ready" ;
VAL_TABLE_ TrnLvrV_D_Rq 3 "Full_Speed" 2 "Aggressive" 1 "Normal" 0 "Quiet" ;
VAL_TABLE_ EngStrtStop_B_SrcOil 1 "Eng_start_stop_for_oilmnt" 0 "Not_Requested" ;
VAL_TABLE_ FuelMaintMde_D_Rq 3 "Feature_Not_Present" 2 "Fuel_Maint_Req_Now" 1 "Fuel_Maint_Req_Soon" 0 "NoRequest" ;
VAL_TABLE_ FuelMaintMde_D_Dsply 3 "Feature_Not_Present" 2 "In_Fuel_Maint_Mode" 1 "Close_to_Fuel_Maint" 0 "OK" ;
VAL_TABLE_ DynoMde_B_Cmd 1 "DynomometerMode" 0 "NormalOperation" ;
VAL_TABLE_ HvacPrecondRecirc_D_Rq 3 "Last_User_Setting" 2 "Auto" 1 "Recirc" 0 "Outside" ;
VAL_TABLE_ HvacPrecondAC_D_Rq 3 "Last_User_Setting" 2 "Auto" 1 "On" 0 "Off" ;
VAL_TABLE_ HybMdeStat_D_Dsply 7 "NotUsed2" 6 "EV_Charge" 5 "EV_Override" 4 "Forced_EV_Mode" 3 "Forced_Charge_Sustain_Mode" 2 "Auto_Charge_Sustain_Mode" 1 "Auto_Charge_Deplete_Mode" 0 "Null_State" ;
VAL_TABLE_ PwFlowPlgBatt_D_Dsply 3 "NotUsed" 2 "Flow_from_Plug_to_Batt" 1 "Flow_from_Batt_to_Plug" 0 "No_Flow" ;
VAL_TABLE_ PwFlowEngMtr_D_Dsply 3 "NotUsed" 2 "Flow_from_Eng_to_Mtr" 1 "Flow_from_Mtr_to_Eng" 0 "No_Flow" ;
VAL_TABLE_ PwFlowEngFuel_D_Dsply 3 "NotUsed" 2 "Flow_from_Eng_to_Fuel" 1 "Flow_from_Fuel_to_Eng" 0 "No_Flow" ;
VAL_TABLE_ PwFlowMtrDrv_D_Dsply 3 "NotUsed" 2 "Flow_from_Mtr_to_Axle" 1 "Flow_from_Axle_to_Mtr" 0 "No_FLow" ;
VAL_TABLE_ PwFlowEngDrv_D_Dsply 3 "NotUsed" 2 "Flow_from_Eng_to_Axle" 1 "Flow_from_Axle_to_Eng" 0 "No_Flow" ;
VAL_TABLE_ PwFlowBattMtr_D_Dsply 3 "NotUsed" 2 "Flow_from_Batt_to_Mtr" 1 "Flow_from_Mtr_to_Batt" 0 "No_Flow" ;
VAL_TABLE_ HybMdeLimMsgTxt_D_Rq 3 "Limited_Req_Full_Defrost" 2 "Limited_Climate_Defrost" 1 "Limited_System_Performance" 0 "Null" ;
VAL_TABLE_ CenterStackRing_D_Actl 3 "LimitedOn" 2 "On" 1 "Off" 0 "Null" ;
VAL_TABLE_ ConsTipUnitPt_D_Dsply 3 "NotUsed" 2 "FuelEconomy" 1 "Distance" 0 "Percentage" ;
VAL_TABLE_ ConsTipMsg1_D_Dsply 15 "NotUsed10" 14 "NotUsed9" 13 "NotUsed8" 12 "NotUsed7" 11 "NotUsed6" 10 "NotUsed5" 9 "NotUsed4" 8 "NotUsed3" 7 "NotUsed2" 6 "NotUsed1" 5 "ReduceIdleTime" 4 "ClimateUsage" 3 "VehicleSpeed" 2 "Deceleration" 1 "Acceleration" 0 "NoDisplay" ;
VAL_TABLE_ NoData_Faulty_FFFE_FFFF 65535 "Faulty" 65534 "NoDataExists" ;
VAL_TABLE_ NoData_Faulty_FFE_FFF 4095 "Faulty" 4094 "NoDataExists" ;
VAL_TABLE_ NoData_Faulty_7FFE_7FFF 32767 "Faulty" 32766 "NoDataExists" ;
VAL_TABLE_ NoData_Faulty_3FE_3FF 1023 "Faulty" 1022 "NoDataExists" ;
VAL_TABLE_ ReFuelSysStat_D_Dsply 7 "NotUsed3" 6 "NotUsed2" 5 "NotUsed1" 4 "Refuel_Err" 3 "Close_Fuel_Door" 2 "Refuel_Ready" 1 "Wait_To_Fuel" 0 "Null" ;
VAL_TABLE_ OffOn_NotUsed 3 "NotUsed2" 2 "NotUsed1" 1 "On" 0 "Off" ;
VAL_TABLE_ DrQltyDrv_D_StatGsm 7 "Faulty" 6 "NoDataExists" 5 "NotUsed2" 4 "NotUsed1" 3 "ClosedDegraded" 2 "OpenDegraded" 1 "ClosedOkay" 0 "OpenOkay" ;
VAL_TABLE_ ChrgrInPwType_D_Actl 6 "NotUsed3" 5 "NotUsed2" 4 "NotUsed1" 3 "DC_Fast_Charging" 2 "AC_Level2_240v" 1 "AC_Level1_120v" 0 "EVSE_Not_Detected" ;
VAL_TABLE_ ChrgrSysFalt1_D_Stat 3 "NotUsed" 2 "Pass" 1 "Fail" 0 "NotDiagnoseYet" ;
VAL_TABLE_ PepsKeyActv_D_Stat 15 "NotUsed11" 14 "NotUsed10" 13 "NotUsed9" 12 "NotUsed8" 11 "NotUsed7" 10 "NotUsed6" 9 "NotUsed5" 8 "Key4Active" 7 "NotUsed4" 6 "NotUsed3" 5 "NotUsed2" 4 "Key3Active" 3 "NotUsed1" 2 "Key2Active" 1 "Key1Active" 0 "NoKeyActive" ;
VAL_TABLE_ CellRstrt_D_Rq 3 "NotUsed" 2 "RemoteCancel" 1 "RemoteStart" 0 "NoRequest" ;
VAL_TABLE_ CellChirp_D_Rq 7 "NotUsed3" 6 "NotUsed2" 5 "NotUsed1" 4 "Honk" 3 "ChirpHonk" 2 "Chirp2" 1 "Chirp1" 0 "NoRequest" ;
VAL_TABLE_ CellLock_D_Rq_Rsm 7 "NotUsed3" 6 "NotUsed2" 5 "NotUsed1" 4 "TrunkRelPopGlassLgCargo" 3 "LockAllDoorsandTailgate" 2 "UnlockDriversDoor" 1 "UnlockAllDoorsandTailgate" 0 "NoRequest" ;
VAL_TABLE_ BattTracHazrd_D_Stat 3 "Disabled" 2 "HazardConfirmed" 1 "ExternalMonitoringRequired" 0 "NoHazardDetected" ;
VAL_TABLE_ RmtCtlBody_D_Stat 15 "NotUsed_6" 14 "NotUsed_5" 13 "NotUsed_4" 12 "NotUsed_3" 11 "NotUsed_2" 10 "NotUsed_1" 9 "Shutdown" 8 "ManeuverFinished" 7 "ReadyForResume" 6 "Pause" 5 "Maneuvering" 4 "ReadyForManeuvering" 3 "Activation" 2 "Initialize" 1 "Preparation" 0 "Disabled" ;
VAL_TABLE_ RmtCtlTrgt_D_Rq 3 "NotUsed" 2 "Null" 1 "RemoteParkAssist" 0 "ManeuverId" ;
VAL_TABLE_ RmtCtl_D_RqBody 7 "NotUsed_2" 6 "NotUsed_1" 5 "Error" 4 "Abort" 3 "PauseKeypad" 2 "PauseHazard" 1 "PauseDoorHandle" 0 "Null" ;
VAL_TABLE_ Null_NoPolling_Polling 3 "NotUsed" 2 "Polling" 1 "NoPolling" 0 "Null" ;
VAL_TABLE_ RmtCtl_D_Stat 15 "Faulty" 14 "NotUsed_5" 13 "NotUsed_4" 12 "NotUsed_3" 11 "NotUsed_2" 10 "NotUsed_1" 9 "Shutdown" 8 "ManeuverFinished" 7 "ReadyForResume" 6 "Pause" 5 "Maneuvering" 4 "ReadyForManeuvering" 3 "Activation" 2 "Initialize" 1 "Preparation" 0 "Disabled" ;
VAL_TABLE_ RmtCtlRngSet_D_Rq 3 "NotUsed" 2 "RangeSetB" 1 "RangeSetA" 0 "None" ;
VAL_TABLE_ SelDrvMde_1_31 31 "Faulty" 30 "SelDrvMde31" 29 "SelDrvMde30" 28 "SelDrvMde29" 27 "SelDrvMde28" 26 "SelDrvMde27" 25 "SelDrvMde26" 24 "SelDrvMde25" 23 "SelDrvMde24" 22 "SelDrvMde23" 21 "SelDrvMde22" 20 "SelDrvMde21" 19 "SelDrvMde20" 18 "SelDrvMde19" 17 "SelDrvMde18" 16 "SelDrvMde17" 15 "SelDrvMde16" 14 "SelDrvMde15" 13 "SelDrvMde14" 12 "SelDrvMde13" 11 "SelDrvMde12" 10 "SelDrvMde11" 9 "SelDrvMde10" 8 "SelDrvMde09" 7 "SelDrvMde08" 6 "SelDrvMde07" 5 "SelDrvMde06" 4 "SelDrvMde05" 3 "SelDrvMde04" 2 "SelDrvMde03" 1 "SelDrvMde02" 0 "SelDrvMde01" ;
VAL_TABLE_ WndwRearHeat_D_Stat 7 "NotUsed" 6 "FetLiftLimitReached" 5 "FetOpenCircuit" 4 "FetOutputShortToPower" 3 "FetOutputShortToGround" 2 "FetNotControlled" 1 "OnPowerToLoad" 0 "OffNoPowerToLoad" ;
VAL_TABLE_ Faulty_7F 63 "Faulty" ;
VAL_TABLE_ DcacHw_D_Confg 15 "NotUsed_11" 14 "NotUsed_10" 13 "NotUsed_9" 12 "NotUsed_8" 11 "NotUsed_7" 10 "NotUsed_6" 9 "NotUsed_5" 8 "NotUsed_4" 7 "NotUsed_3" 6 "NotUsed_2" 5 "NotUsed_1" 4 "Power_2300W" 3 "Power_7200W" 2 "Power_2400W" 1 "Power_2000W" 0 "NoDcacHardware" ;
VAL_TABLE_ DcacFaltMsgTxt_D_Rq 15 "HvacOn" 14 "OvercurrentLP" 13 "EngineRun" 12 "Service" 11 "NotAvailable" 10 "PlugWarn" 9 "PlugWarnDrive" 8 "BreakerC" 7 "BreakerB" 6 "BreakerA" 5 "FuelLow" 4 "AcOnOutput" 3 "Temperature" 2 "Gfci" 1 "Overcurrent" 0 "Ok" ;
VAL_TABLE_ DcacLoFuelMsgTxt_D_Rq 31 "Minute_31" 30 "Minute_30" 29 "Minute_29" 28 "Minute_28" 27 "Minute_27" 26 "Minute_26" 25 "Minute_25" 24 "Minute_24" 23 "Minute_23" 22 "Minute_22" 21 "Minute_21" 20 "Minute_20" 19 "Minute_19" 18 "Minute_18" 17 "Minute_17" 16 "Minute_16" 15 "Minute_15" 14 "Minute_14" 13 "Minute_13" 12 "Minute_12" 11 "Minute_11" 10 "Minute_10" 9 "Minute_9" 8 "Minute_8" 7 "Minute_7" 6 "Minute_6" 5 "Minute_5" 4 "Minute_4" 3 "Minute_3" 2 "Minute_2" 1 "Minute_1" 0 "Ok" ;
VAL_TABLE_ DcacEngOnMsgTxt_D_Rq 3 "NotUsed" 2 "DisplayQuestion" 1 "DisplayWarning" 0 "Ok" ;
VAL_TABLE_ OffPendingActiveNotUsed 3 "NotUsed" 2 "Active" 1 "Pending" 0 "Off" ;
VAL_TABLE_ OffLowHighNotUsed 3 "NotUsed" 2 "High" 1 "Low" 0 "Off" ;
VAL_TABLE_ Null_Off_On_NoControl 3 "NoControl" 2 "On" 1 "Off" 0 "Null" ;
VAL_TABLE_ NotDeterminedNotPresentFaulty 3 "Faulty" 2 "Present" 1 "NotPresent" 0 "NotDetermined" ;
VAL_TABLE_ VehStrtInhbt_D_Dsply 15 "NotUsed_12" 14 "NotUsed_11" 13 "NotUsed_10" 12 "NotUsed_9" 11 "NotUsed_8" 10 "NotUsed_7" 9 "NotUsed_6" 8 "NotUsed_5" 7 "NotUsed_4" 6 "FleetPhoneNumber" 5 "FleetGeneral" 4 "OtaSuccess" 3 "PostOtaActivatePermFail" 2 "PostOtaActivateWarning" 1 "DuringOtaActivate" 0 "NoMessage" ;
VAL_TABLE_ VehOnRqstr_D_Stat 11 "NotUsed_8" 10 "NotUsed_7" 9 "NotUsed_6" 8 "NotUsed_5" 7 "NotUsed_4" 6 "NotUsed_3" 5 "NotUsed_2" 4 "NotUsed_1" 3 "FleetVehInhbt" 2 "StolenVehInhbt" 1 "OverTheAir" 0 "NoRequestor" 15 "NotUsed_12" 14 "NotUsed_11" 13 "NotUsed_10" 12 "NotUsed_9" ;
VAL_TABLE_ OtaActv_D_Stat 15 "NotUsed_10" 14 "NotUsed_9" 13 "NotUsed_8" 12 "NotUsed_7" 11 "NotUsed_6" 10 "NotUsed_5" 9 "NotUsed_4" 8 "NotUsed_3" 7 "NotUsed_2" 6 "NotUsed_1" 5 "NonInterruptible_Pending" 4 "NonInterruptible_Config" 3 "NonInterruptible_ER" 2 "NonInterruptible_AB" 1 "Interruptible_AB" 0 "NoInVehicleOta" ;
VAL_TABLE_ ULoBattTransfer_D_Stat 7 "NotUsed_2" 6 "NotUsed_1" 5 "TransferError" 4 "TransferComplete" 3 "TransferThroughGridEnergy" 2 "InsufficientEnergyToXfer" 1 "TransferInProgress" 0 "NoTransfer" ;
VAL_TABLE_ PwRnngBoardPoll_D_Stat 3 "NotUsed" 2 "PkPresent" 1 "PkNotPresent" 0 "NotPolling" ;
VAL_TABLE_ BrkHold_D_Stat 7 "NotUsed_3" 6 "NotUsed_2" 5 "NotUsed_1" 4 "HeldSecondary" 3 "HeldSecure" 2 "Held" 1 "Inactive" 0 "Off" ;
VAL_TABLE_ Null_Left_Right 3 "NotUsed" 2 "Right" 1 "Left" 0 "Null" ;
VAL_TABLE_ TrlrHitch_D_RqMnu 15 "NotUsed_10" 14 "NotUsed_9" 13 "NotUsed_8" 12 "NotUsed_7" 11 "NotUsed_6" 10 "NotUsed_5" 9 "NotUsed_4" 8 "NotUsed_3" 7 "NotUsed_2" 6 "NotUsed_1" 5 "GoToTraileringDomain" 4 "Confirm" 3 "TurnOnTba" 2 "TurnOnAutohitch" 1 "CancelAutohitch" 0 "NoRequest" ;
VAL_TABLE_ DcacRdy_D2_Stat 3 "Faulted" 2 "RecoverableFault" 1 "Active" 0 "Idle" ;
VAL_TABLE_ NotFaulted_Faulted 1 "Faulted" 0 "NotFaulted" ;
VAL_TABLE_ BattULoChrgHyb_D_Stat 7 "NotUsed_4" 6 "NotUsed_3" 5 "NotUsed_2" 4 "NotUsed_1" 3 "VehicleServiceRequired" 2 "EvRangeLossDueToLoadActive" 1 "BatteryServiceRequired" 0 "Null" ;
VAL_TABLE_ PoliceDmngLvl_D_Stat 7 "NotUsed" 6 "Off_Night" 5 "Off_Day" 4 "Low1Night" 3 "Low1Day" 2 "Inactive" 1 "Decommissioned" 0 "Null" ;
VAL_TABLE_ VehWlcmFrwl_D_Stat 3 "RunStart" 2 "Farewell" 1 "Welcome" 0 "Null" ;
VAL_TABLE_ VehWlcmFrwlMde_D_Stat 7 "IlluminatedExit" 6 "CourtesyLightingDelayExt" 5 "CourtesyLightingExtended" 4 "CourtesyLightingDelayAll" 3 "CourtesyLightingAll" 2 "IlluminatedEntry" 1 "Approach" 0 "Null" ;
VAL_TABLE_ OnePdlDrvBrk_D_Rq 3 "Active_FbrkStandstillApply" 2 "Active_FbrkStopApply" 1 "Active_NoFbrkAllow" 0 "Inactive" ;
VAL_TABLE_ OnePdlDrv_D_Stat 3 "Enabled_BrkLampAndFbrk" 2 "Enabled_BrkLamp" 1 "Enabled_NoAction" 0 "Disabled" ;
VAL_TABLE_ HybMdeMsgTxt_D2_Rq 15 "NotUsed_4" 14 "NotUsed_3" 13 "NotUsed_2" 12 "NotUsed_1" 11 "EvOverride_Avail" 10 "EvLaterActv_EvAuto_NowAvai" 9 "EvNowActv_EvAuto_LaterAvai" 8 "EvAutoActv_EvNow_LaterAvai" 7 "EvAutoActv_NoOtherMdeAvail" 6 "EvChrgActv_EvAutoMdeAvail" 5 "EvAutoActv_EvChrgMdeAvail" 4 "EvChrgActv_AllPhevMdeAvail" 3 "EvLaterActv_AllPhevMdeAvai" 2 "EvNowActv_AllPhevMdeAvail" 1 "EvAutoActv_AllPhevMdeAvail" 0 "Null" ;
VAL_TABLE_ TsrRegionTxt_D_Stat 31 "Faulty" 30 "NotUsed_8" 29 "NotUsed_7" 28 "NotUsed_6" 27 "NotUsed_5" 26 "NotUsed_4" 25 "NotUsed_3" 24 "NotUsed_2" 23 "NotUsed_1" 22 "Region_22" 21 "Region_21" 20 "Region_20" 19 "Region_19" 18 "Region_18" 17 "Region_17" 16 "Region_16" 15 "Region_15" 14 "Region_14" 13 "Region_13" 12 "Region_12" 11 "Region_11" 10 "Region_10" 9 "Region_09" 8 "Region_08" 7 "Region_07" 6 "Region_06" 5 "Region_05" 4 "Region_04" 3 "Region_03" 2 "Region_02" 1 "Region_01" 0 "NotDetermined" ;
VAL_TABLE_ Inactive_On_NotUsed 7 "NotUsed_6" 6 "NotUsed_5" 5 "NotUsed_4" 4 "NotUsed_3" 0 "Inactive" 1 "On" 2 "NotUsed_1" 3 "NotUsed_2" ;
VAL_TABLE_ _S_No_Yes 1 "Yes" 0 "No" ;
VAL_TABLE_ UpDownNotUsedFaulty 3 "Faulty" 2 "NotUsed" 1 "Down" 0 "Up" ;
VAL_TABLE_ PtWakeReas_D_Stat 15 "NotUsed_9" 14 "NotUsed_8" 13 "NotUsed_7" 12 "NotUsed_6" 11 "NotUsed_5" 10 "NotUsed_4" 9 "NotUsed_3" 8 "NotUsed_2" 7 "NotUsed_1" 6 "ElapsedTime" 5 "ThirdPartyWakeup" 4 "DoorAjar" 3 "EarlyWake" 2 "NonMotiveStart" 1 "MotiveStart" 0 "Null" ;
VAL_TABLE_ ExtLghtLeft_D_RqMnu 7 "NotUsed" 6 "PressToOn3" 5 "PressToOff3" 4 "PressToOn2" 3 "PressToOff2" 2 "PressToOn1" 1 "PressToOff1" 0 "Reset" ;
VAL_TABLE_ ExtLght_D_Falt 3 "Error" 2 "NoStationary" 1 "StartEngine" 0 "Null" ;
VAL_TABLE_ MemStoreMsgTxt_D_Rq 10 "NotUsed_2" 9 "NotUsed_1" 8 "Mem4Saved_ShowLinkMsg" 7 "Mem3Saved_ShowLinkMsg" 6 "Mem2Saved_ShowLinkMsg" 5 "Mem1Saved_ShowLinkMsg" 4 "Mem4Saved_DoNotShowLinkMsg" 3 "Mem3Saved_DoNotShowLinkMsg" 2 "Mem2Saved_DoNotShowLinkMsg" 1 "Mem1Saved_DoNotShowLinkMsg" 0 "Null" ;
VAL_TABLE_ MemSetButtnMsgTxt_D_Rq 3 "NotUsed" 2 "Press1or2or3" 1 "Press1or2" 0 "Null" ;
VAL_TABLE_ MildHybStat_D_Dsply 7 "NotUsed" 6 "Recovery" 5 "Charge" 4 "Assist" 3 "Boost" 2 "SystemInhibited" 1 "SystemError" 0 "Off" ;
VAL_TABLE_ ChrgCrdLck_D_Falt 3 "NotUsed" 2 "HardwareFault" 1 "CsiFault" 0 "NoFault" ;
VAL_TABLE_ AltFuelLvlWarn_D_Actl 7 "DteLevel5Lowest" 6 "DteLevel4" 5 "DteLevel3" 4 "DteLevel2NonMyKey" 3 "DteLevel1MyKey" 2 "VeryLow" 1 "Low" 0 "Ok" ;
VAL_TABLE_ AltFuelOpMde_D_Stat 7 "NotUSed" 6 "AltFuelMde_To_GasMde" 5 "GasMde_To_AltFuelMde" 4 "ForcedAltFuelMde" 3 "AltFuelMde" 2 "ForcedGasMde_AltFuelSysErr" 1 "ForcedGasMde_AltFuelLow" 0 "GasMde" ;
VAL_TABLE_ Normal_FaultNoMIL 3 "NotUsed" 2 "Fault_MIL" 1 "Fault_NoMIL" 0 "Normal" ;
VAL_TABLE_ DgtlCommPnc_D_Rq 3 "DeleteAll" 2 "Disable" 1 "Reset" 0 "NoRequest" ;
VAL_TABLE_ BattTracClntVlv_D_Stat 7 "FetLowSideOpenOrShort" 6 "FetLifeLimitReached" 5 "FetOpenCircuit" 4 "FetOutputShortToPower" 3 "FetOutputShortToGround" 2 "FetNotControlled" 1 "OnPowerToLoad" 0 "OffNoPowerToLoad" ;
VAL_TABLE_ EngMdeMsgTxt_D_Rq 7 "NotUsed_3" 6 "NotUsed_2" 5 "NotUsed_1" 4 "Charge" 3 "GlowingCharge" 2 "Hybrid" 1 "Ev" 0 "NoMessage" ;
VAL_TABLE_ NoReqHiDecelLowDecel 3 "NotUsed" 2 "LowDecel" 1 "HighDecel" 0 "NoRequest" ;
VAL_TABLE_ BattRgenLoStat_D_Qlty 3 "OK" 2 "Not_Within_Spec" 1 "Eval_In_Progress" 0 "Faulty" ;
VAL_TABLE_ OpenClosedRetainDisable 3 "Disable" 2 "Retain" 1 "Closed" 0 "Open" ;
VAL_TABLE_ OpenClosedStuckOpenClosed 3 "StuckClosed" 2 "StuckOpen" 1 "Closed" 0 "Open" ;
VAL_TABLE_ OpenClosedRetainDoNotCare 3 "DoNotCare" 2 "Retain" 1 "Closed" 0 "Open" ;
VAL_TABLE_ NoData_Faulty_7FE_7FF 2047 "Faulty" 2046 "NoDataExists" ;
VAL_TABLE_ EngIdlShutDwnTxt_D_Rq 3 "NotUsed" 2 "EngineShutdownOnPrevDrive" 1 "FeatureDisabledDueToFault" 0 "NoMessage" ;
VAL_TABLE_ NoData_Fault_1FF_1FE 511 "Fault" 510 "NoDataExists" ;
VAL_TABLE_ NoData_Fault_FFE_FFF 4095 "Fault" 4094 "NoDataExists" ;
VAL_TABLE_ EngIdlShutDown_D_Stat 3 "Not_used" 2 "Engine_Shutdown" 1 "Initiated_Countdown" 0 "Normal_Operation" ;
VAL_TABLE_ StopStrtDrvMde_D_Indic 3 "NotUsed" 2 "StartStop_IndirectDeselect" 1 "StopStart_Deselected" 0 "StopStart_Selected" ;
VAL_TABLE_ StopStrtStdby_D_Indic 6 "Telltale_On_Grey" 5 "Telltale_Struck_Out" 4 "Telltale_Flashing_Amber" 3 "Telltale_On_Amber" 2 "Telltale_Flashing_Green" 1 "Telltale_On_Green" 0 "Telltale_Off" 7 "NotUsed3" ;
VAL_TABLE_ Quality_Faulty 3 "OK" 2 "Degraded" 1 "No_Data_Exists" 0 "Faulty" ;
VAL_TABLE_ TrnDtpCmd_D_Actl 7 "NotUsed4" 6 "NotUsed3" 5 "NotUsed2" 4 "Relatch" 3 "Deploy" 2 "Self_Test" 1 "No_Command" 0 "NotUsed1" ;
VAL_TABLE_ TrnGsmNtmState_D_Actl 3 "Faulty" 2 "Neutral_Tow_Mode" 1 "Car_Wash_Mode" 0 "None" ;
VAL_TABLE_ RgenBrkDynoMde_B_Actl 1 "TwoWheelDyno" 0 "NormalOperation" ;
VAL_TABLE_ Fault_3FFF 16383 "Fault" ;
VAL_TABLE_ PrkBrkActv_D_RqTrnGear 3 "NotUsed2" 2 "RequestParkBrakeEngage" 1 "NoRequest" 0 "NotUsed1" ;
VAL_TABLE_ NoRequest_Request 1 "Request" 0 "NoRequest" ;
VAL_TABLE_ Fault_FFF_NoData 4094 "NoDataExists" 4095 "Fault" ;
VAL_TABLE_ Fault_3FF_NoData 1022 "NoDataExists" 1023 "Fault" ;
VAL_TABLE_ Foh_D_Stat 7 "Unused3" 6 "Unused2" 5 "Unused1" 4 "Stopping" 3 "Running" 2 "Starting" 1 "Prestart" 0 "Off" ;
VAL_TABLE_ WindowPosition 7 "Unused2" 6 "Unused1" 5 "Fully_Open" 4 "Bet60Percent_FullyOpen" 3 "Bet10Percent_60Percent" 2 "BetFully_10PercentOpen" 1 "Fully_Closed" 0 "Undefined" ;
VAL_TABLE_ FohFalt_D_Stat 15 "NotUsed4" 14 "NotUsed3" 13 "NotUsed2" 12 "NotUsed1" 11 "FuelTypeDoesNotMatchFOH" 10 "Lifecycle_ModeNotSet" 9 "AuxElectricCoolantPumpInop" 8 "TimeDelayAvoidExcessCycl" 7 "Fuel_Level_OutofRange" 6 "External_Fault" 5 "Internal_Fault" 4 "Voltage_limitation" 3 "Impact_Event" 2 "CoolantTemp_OutofRange" 1 "AmbientTemp_OutofRange" 0 "No_Disable" ;
VAL_TABLE_ FohRqRun_B_Rq 1 "SubmitRequest_toRun" 0 "DoesNotSubmitRequest_toRun" ;
VAL_TABLE_ OffOnUnusedFault 3 "Fault" 2 "Unused" 1 "On" 0 "Off" ;
VAL_TABLE_ NoMessage_DisplayMessage 1 "DisplayMessage" 0 "NoMessage" ;
VAL_TABLE_ EngineBrakeOff_Active 1 "Engine_Braking_Activated" 0 "Engine_Braking_Off" ;
VAL_TABLE_ NoEngineBrake_Brake 1 "Engine_Braking" 0 "No_Engine_Braking" ;
VAL_TABLE_ PlgActv_D_ActlChrgr 3 "Faulty" 2 "NoDataExists" 1 "On_Plug__Connected_" 0 "Off_Plug__Disconnected_" ;
VAL_TABLE_ EngSrvcRqd_B_Rq 1 "Engine_Service_Required" 0 "No_engine_service_required" ;
VAL_TABLE_ Allowed_Denied 1 "Denied" 0 "Allowed" ;
VAL_TABLE_ PrkAidSns_D_Stat 15 "Zone_15" 14 "Zone_14" 13 "Zone_13" 12 "Zone_12" 11 "Zone_11" 10 "Zone_10" 9 "Zone_9" 8 "Zone_8" 7 "Zone_7" 6 "Zone_6" 5 "Zone_5" 4 "Zone_4" 3 "Zone_3" 2 "Zone_2" 1 "Zone_1" 0 "Off" ;
VAL_TABLE_ PrkAid_D_Falt 7 "NotUsed2" 6 "NotUsed1" 5 "Failure_Front_PSM_Sensors" 4 "No_Data_Exists" 3 "Failure_Rear_Sensors" 2 "Speaker_Fault" 1 "ECU_Fault" 0 "No_Fault" ;
VAL_TABLE_ OffOnNoDataFault 3 "Fault" 2 "No_Data_Exists" 1 "On" 0 "Off" ;
VAL_TABLE_ ApaMdeStat_D_RqDrv 7 "Faulty" 6 "Off" 5 "NotUsed2" 4 "NotUsed1" 3 "POA" 2 "PPA" 1 "SAPP" 0 "Inactive" ;
VAL_TABLE_ FrostWarn_D_Stat 3 "NotUsed" 2 "On_Amber" 1 "On_Red" 0 "Off" ;
VAL_TABLE_ SteWhlLckMsgTxt_D_Rq 3 "Message_3" 2 "Message_2" 1 "Message_1" 0 "No_Message" ;
VAL_TABLE_ Null_Off_LowHigh 3 "High" 2 "Low" 1 "Off" 0 "Null" ;
VAL_TABLE_ GearRvrse_D_Actl 7 "Fault" 6 "NotUsed_3" 5 "NotUsed_2" 4 "NotUsed_1" 3 "Active_confirmed" 2 "Active_not_confirmed" 1 "Inactive_confirmed" 0 "Inactive_not_confirmed" ;
VAL_TABLE_ DrTGate_D_Rq 3 "NotUsed" 2 "Closing" 1 "Opening" 0 "Not_Moving" ;
VAL_TABLE_ WndwSide_D_Stat 3 "BothWindow_Operating" 2 "RearWindow_Operating" 1 "FrontWindow_Operating" 0 "NoWindows_Operating" ;
VAL_TABLE_ DcacElPw_D_Rq 3 "NotUsed" 2 "AC_HighPower_Requested" 1 "AC_LowPower_Requested" 0 "AC_Power_NotRequested" ;
VAL_TABLE_ False_True 1 "True" 0 "False" ;
VAL_TABLE_ Null_Ack_Nack_NotUsed 3 "Not_Used" 2 "Nack" 1 "Ack" 0 "Null" ;
VAL_TABLE_ Null_Reset 1 "Reset" 0 "Null" ;
VAL_TABLE_ Unknown_FFFD_Invalid_NotSup 65535 "Not_Supported" 65534 "Invalid" 65533 "Unknown" ;
VAL_TABLE_ HvacBlwrFront_D_Stat 31 "Not_Used" 20 "Full_On" 19 "95_Percent" 18 "90_Percent" 17 "85_Percent" 16 "80_Percent" 15 "75_Percent" 14 "70_Percent" 13 "65_Percent" 12 "60_Percent" 11 "55_Percent" 10 "50_Percent" 9 "45_Percent" 8 "40_Percent" 7 "35_Percent" 6 "30_Percent" 5 "25_Percent" 4 "20_Percent" 3 "15_Percent" 2 "10_Percent" 1 "5_Percent" 0 "Off" ;
VAL_TABLE_ immoMsgTxt_D_Rq 15 "Immo_Msg_15" 14 "Immo_Msg_14" 13 "Immo_Msg_13" 12 "Immo_Msg_12" 11 "Immo_Msg_11" 10 "Immo_Msg_10" 9 "Immo_Msg_9" 8 "Immo_Msg_8" 7 "Immo_Msg_7" 6 "Immo_Msg_6" 5 "Immo_Msg_5" 4 "Immo_Msg_4" 3 "Immo_Msg_3" 2 "Immo_Msg_2" 1 "Immo_Msg_1" 0 "Immo_Msg_0_Null" ;
VAL_TABLE_ BattTracWarnLamp_B_Rq 1 "On" 0 "Off" ;
VAL_TABLE_ BattTracSrvcRqd_B_Rq 1 "On" 0 "Off" ;
VAL_TABLE_ HtrnWarnLamp_B_Dsply 1 "On" 0 "Off" ;
VAL_TABLE_ HtrnSrvcRqd_B_Dsply 1 "On" 0 "Off" ;
VAL_TABLE_ NoData_Faulty_7E_7F 127 "Faulty" 126 "NoDataExists" ;
VAL_TABLE_ PtWakeupActv1_B_Rq 1 "Wake_up_Powertrain_via_HW" 0 "Don_t_Wake_Up_Powertrain" ;
VAL_TABLE_ HMI_HMIMode_St 7 "NotUsed2" 6 "NotUsed1" 5 "Load_Shed_Active" 0 "Invalid" 1 "OffMode" 2 "On" 3 "Phone" 4 "Climate" ;
VAL_TABLE_ FuelPumpPwr_D_Stat 7 "NotUsed3" 6 "NotUsed2" 5 "NotUsed1" 4 "Power_Off_Default" 3 "Power_Off_Command" 2 "Power_Off_Service" 1 "Power_Off_Impact" 0 "Power_On" ;
VAL_TABLE_ ChrgrRdyStat_D_Actl 7 "NotUsed4" 6 "NotUsed3" 5 "NotUsed2" 4 "NotUsed1" 3 "Charging" 2 "ChargerFault" 1 "ChargerReady" 0 "NotReady" ;
VAL_TABLE_ PrmtrAlrmEvnt_D_Stat 15 "Diag_Tamper" 14 "Trailer" 13 "Shock_Sensor" 12 "Post_Crash" 11 "Panic" 10 "Intrusion" 9 "Inclination" 8 "Ign_Tamper" 7 "LG_Door" 6 "Decklid" 5 "Hood" 4 "PR_Door" 3 "PF_Door" 2 "DR_Door" 1 "DF_Door" 0 "Null" ;
VAL_TABLE_ SecurityMsgTxt_D_Rq 3 "Message3" 2 "Message2" 1 "Message1" 0 "NoMessage" ;
VAL_TABLE_ BattChrgRdyStat_D_Actl 7 "NotUsed2" 6 "NotUsed1" 5 "Faulted" 4 "ChargeComplete" 3 "Charging" 2 "BatteryChargeReady" 1 "ChargeWait" 0 "NotReady" ;
VAL_TABLE_ BattChrgInhbt_D_Rq 3 "MaintainTargetSoc" 2 "NotUsed" 1 "InhibitChargingThermal" 0 "Enable_Charging" ;
VAL_TABLE_ Fault_7FF_NoData 2047 "Fault" 2046 "NoDataExists" ;
VAL_TABLE_ Deactivate_Activate 1 "Activate" 0 "Deactivate" ;
VAL_TABLE_ PtcHtr_D_Stat 3 "Faulty" 2 "NotUsed" 1 "On" 0 "Off" ;
VAL_TABLE_ PtcHtr_D_Cmd 3 "TurnOn" 2 "AutoMode" 1 "TurnOff" 0 "NoDecision_Initializing" ;
VAL_TABLE_ Fault_FFFFFF 16777215 "Fault" ;
VAL_TABLE_ NoData_Fault_FFFE_FFFF 65535 "Fault" 65534 "NoDataExists" ;
VAL_TABLE_ EngOffTe_B_Dsply 1 "Eng_warm_engh_for_pd" 0 "Eng_not_warm_engh_for_pd" ;
VAL_TABLE_ DrvEffLvlIncDec_D_Cmd 3 "NotUsed" 2 "Decrease_Level_by_1" 1 "Increase_Level_by_1" 0 "Null_State" ;
VAL_TABLE_ Fault_FFFF_NoData_FFFE 65535 "Fault" 65534 "NoDataExists" ;
VAL_TABLE_ Fault_1FFF 8191 "Fault" ;
VAL_TABLE_ ElPw_D_StatStrtStop 15 "NotUsed6" 14 "NotUsed5" 13 "NotUsed4" 12 "NotUsed3" 11 "NotUsed2" 10 "NotUsed1" 9 "Supported_Level_4" 8 "Supported_Level_3" 7 "Supported_Level_2" 6 "Supported_Level_1" 5 "Limited_Support" 4 "Fault_Limited" 3 "LV_Event_in_Progress" 2 "Not_Supported_Imminent" 1 "Supported_All" 0 "Not_Supported" ;
VAL_TABLE_ ImpactEvntFdbck_D_Stat 3 "NotUsed" 2 "EventComplete" 1 "EventInProgress" 0 "Normal" ;
VAL_TABLE_ StopStrtIODTxt_D_Rq 31 "Message31" 30 "Message30" 29 "Message29" 28 "Message28" 27 "Message27" 26 "Message26" 25 "Message25" 24 "Message24" 23 "Message23" 22 "Message22" 21 "Message21" 20 "Message20" 19 "Message19" 18 "Message18" 17 "Message17" 16 "Message16" 15 "Message15" 14 "Message14" 13 "Message13" 12 "Message12" 11 "Message11" 10 "Message10" 9 "Message9" 8 "Message8" 7 "Message7" 6 "Message6" 5 "Message5" 4 "Message4" 3 "Message3" 2 "Message2" 1 "Message1" 0 "NoMessage" ;
VAL_TABLE_ NoData_Fault_7FFE_7FFF 32767 "Fault" 32766 "NoDataExists" ;
VAL_TABLE_ NoData_Fault_3E_3F 63 "Fault" 62 "NoDataExists" ;
VAL_TABLE_ DrvSte_D_Stat 15 "NotUsed10" 14 "NotUsed9" 13 "NotUsed8" 12 "NotUsed7" 11 "NotUsed6" 10 "NotUsed5" 9 "NotUsed4" 8 "NotUsed3" 7 "NotUsed2" 6 "NotUsed1" 5 "Request_Active" 4 "Ignition_Off" 3 "DSR_in_Normal_Idle_Mode" 2 "EPAS_Comm_Disturbed" 1 "DSR_Request_Not_Applicable" 0 "DSR_Deactivated" ;
VAL_TABLE_ StrtrMtrCtlMsgTxt_D_Rq 7 "Start_In_Gear_Allowed" 6 "Pending_Start_Cancelled" 5 "Start_Pending_Please_Wait" 4 "Cranking_Limit_Exceeded" 3 "Press_Brk_and_Shift_to_P_N" 2 "Press_Clutch_and_Brake" 1 "Press_Clutch_To_Start" 0 "No_Display" ;
VAL_TABLE_ Null_Open 1 "Open" 0 "Null" ;
VAL_TABLE_ HeadLghtHiFdbck_D_Stat 3 "NotUsed" 2 "Cancel" 1 "Hold" 0 "Allow_Change" ;
VAL_TABLE_ Backlit_LED_Status 15 "Unused3" 14 "Unused2" 13 "Unused1" 12 "Night_12" 11 "Night_11" 10 "Night_10" 9 "Night_9" 8 "Night_8" 7 "Night_7" 6 "Night_6" 5 "Night_5" 4 "Night_4" 3 "Night_3" 2 "Night_2" 1 "Night_1" 0 "Off" ;
VAL_TABLE_ Veh_Lock_Status 3 "UNLOCK_DRV" 2 "UNLOCK_ALL" 1 "LOCK_ALL" 0 "LOCK_DBL" ;
VAL_TABLE_ PrkLckCtlMsgTxt_D_Rq 3 "BTSI_DI_3" 2 "BTSI_DI_2" 1 "BTSI_DI_1" 0 "Null_BTSI_DI" ;
VAL_TABLE_ NoShift_Shift 1 "Shift" 0 "NoShift" ;
VAL_TABLE_ CrashEvnt_D_Stat 3 "Invalid" 2 "Fuel_Cutoff_Event" 1 "Deploy_Event" 0 "No_Event" ;
VAL_TABLE_ ReducedGuard_D_Stat 3 "NotUsed" 2 "Alarm_On" 1 "Alarm_Off_Previously_On" 0 "Alarm_Off" ;
VAL_TABLE_ HvacPrecondBlwr_D_Rq 15 "NotUsed6" 14 "NotUsed5" 13 "NotUsed4" 12 "NotUsed3" 11 "NotUsed2" 10 "NotUsed1" 9 "Last_User_Setting" 8 "Auto" 7 "Speed7" 6 "Speed6" 5 "Speed5" 4 "Speed4" 3 "Speed3" 2 "Speed2" 1 "Speed1" 0 "Off" ;
VAL_TABLE_ HvacPrecondMode_D_Rq 15 "NotUsed4" 14 "NotUsed3" 13 "NotUsed2" 12 "NotUsed1" 11 "Last_User_Settings" 10 "Auto" 9 "Max_Defrost" 8 "Windshield_Panel_Floor" 7 "Windshield_Panel" 6 "Windshield" 5 "Windshield_Floor" 4 "Floor" 3 "Panel_Floor" 2 "Panel" 1 "MAX_AC" 0 "Off" ;
VAL_TABLE_ ButtonNotPressed 1 "Button_Pressed" 0 "Button_Not_Pressed" ;
VAL_TABLE_ Null_Pressed 1 "Pressed" 0 "Null" ;
VAL_TABLE_ FobComm_D_Stat 3 "NotUsed" 2 "RemEngStartOK" 1 "RemEngStartFail" 0 "Null" ;
VAL_TABLE_ PudLamp_D_Rq 3 "RAMP_DOWN" 2 "RAMP_UP" 1 "ON" 0 "OFF" ;
VAL_TABLE_ WndwGlbl_D_Cmd 7 "NotUsed3" 6 "NotUsed2" 5 "NotUsed1" 4 "GLEARN" 3 "GCLOSE" 2 "GOPEN" 1 "GSTOP" 0 "Null" ;
VAL_TABLE_ LockMsg 7 "MSG7" 6 "MSG6" 5 "MSG5" 4 "MSG4" 3 "MSG3" 2 "MSG2" 1 "MSG1" 0 "NO_WARNING" ;
VAL_TABLE_ ChildLockDisplay 3 "NOT_SUPPORTED" 2 "ERROR" 1 "CHILD_UNLOCK" 0 "CHILD_LOCK" ;
VAL_TABLE_ Null_Lock_Unlock 3 "NotUsed" 2 "Unlock" 1 "Lock" 0 "Null" ;
VAL_TABLE_ NotDown_Down 1 "Down" 0 "Not_Down" ;
VAL_TABLE_ NotUp_Up 1 "Up" 0 "Not_Up" ;
VAL_TABLE_ Wiper 15 "NO_DATA_EXISTS" 14 "STALLED" 13 "RESERVED" 12 "AUTO_ADJUST" 11 "COURTESYWIPE" 10 "AUTO_HIGH" 9 "AUTO_LOW" 8 "WASH" 7 "MIST_FLICK" 6 "MAN_HIGH" 5 "MAN_LOW" 4 "MAN_INT_ON" 3 "MAN_INT_OFF" 2 "OFF_MOVING" 1 "AUTO_OFF" 0 "OFF" ;
VAL_TABLE_ Turn_switch 3 "Unused_Treat_As_Off" 2 "Right" 1 "Left" 0 "Off" ;
VAL_TABLE_ PrkLght_D_Stat 3 "Park_Both" 2 "Park_Right" 1 "Park_Left" 0 "Off" ;
VAL_TABLE_ LghtAmb_D_Sns 7 "No_Data_Exists" 6 "Unused2" 5 "Unused1" 4 "Tunnel_Off" 3 "Tunnel_On" 2 "Twilight" 1 "Light" 0 "Dark" ;
VAL_TABLE_ HeadLghtSwtch_D_Stat 3 "Autolamp" 2 "Headlamp" 1 "Parklamp" 0 "Off" ;
VAL_TABLE_ EmgcyBrkLamp_D_Rq 3 "NotUsed" 2 "Active_at_standstill" 1 "Active_at_speed" 0 "Inactive" ;
VAL_TABLE_ GearLvrPos_D_Unfilt 7 "Invalid" 6 "NotUsed" 5 "In_between" 4 "Low" 3 "Drive" 2 "Neutral" 1 "Reverse" 0 "Park" ;
VAL_TABLE_ EDrvTqMntrRconfg_D_Cmd 7 "OK" 6 "Disable_Cruise" 5 "NotUsed4" 4 "Supercreep" 3 "NotUsed3" 2 "NotUsed2" 1 "Engine_shutdown" 0 "NotUsed" ;
VAL_TABLE_ OpenPressedFault 3 "Fault" 2 "Unused" 1 "Pressed" 0 "Open" ;
VAL_TABLE_ LaHandsOff_D_Dsply 3 "Suppressed" 2 "Level2" 1 "Level1" 0 "HandsOn" ;
VAL_TABLE_ Avail_Unavail 1 "Unavailable" 0 "Available" ;
VAL_TABLE_ GrllShtrPos_D_Cmd 15 "Fully_Open" 14 "Position14" 13 "Position13" 12 "Position12" 11 "Position11" 10 "Position10" 9 "Position9" 8 "Position8" 7 "Position7" 6 "Position6" 5 "Position5" 4 "Position4" 3 "Position3" 2 "Position2" 1 "Position1" 0 "Fully_Closed" ;
VAL_TABLE_ LifeCycMde_D_Actl 3 "Transport" 2 "NotUsed" 1 "Factory" 0 "Normal" ;
VAL_TABLE_ TrnMsgTxt_D_Rq 15 "Message_15" 14 "Message_14" 13 "Message_13" 12 "Message_12" 11 "Message_11" 10 "Message_10" 9 "Message_9" 8 "Message_8" 7 "Message_7" 6 "Message_6" 5 "Message_5" 4 "Message_4" 3 "Message_3" 2 "Message_2" 1 "Message_1" 0 "NoMessage" ;
VAL_TABLE_ DieslPrtcRgen_D_Rq 7 "Unused_2" 6 "Unused_1" 5 "Full_Regen_2" 4 "Full_Regen_1" 3 "HeatUp_3" 2 "HeatUp_2" 1 "HeatUp_1" 0 "Normal_Mode_NoRegen" ;
VAL_TABLE_ ClimtHeat_D_Rq 7 "NotUsed4" 6 "NotUsed3" 5 "HtrCoreClntFlwOnly" 4 "PtcHtrTestMde" 3 "Defrost_Defog" 2 "FastTempPullDownHeatingReq" 1 "OpportunisticHeatingReq" 0 "NoHeatingRequest" ;
VAL_TABLE_ TrnSecPrkStat_D_Actl 7 "Faulty" 6 "Fault_Released" 5 "Fault_Latched" 4 "Recouple_in_Progress" 3 "Mechanism_Released" 2 "RTP_in_Progress" 1 "Pending" 0 "Latched" ;
VAL_TABLE_ TrnGear_D_Actl 7 "Fault" 6 "NotUsed" 5 "Manual" 4 "Drive" 3 "Neutral" 2 "Reverse" 1 "Park" 0 "Transition_State" ;
VAL_TABLE_ TrnNtrlTowCmd_D_Actl 3 "NotUsed" 2 "Neutral_Tow_Entry" 1 "Car_Wash_Mode" 0 "Normal_Mode" ;
VAL_TABLE_ TrnValidGear_D_Cnfm 3 "Accept" 2 "Reject" 1 "Internal_Request" 0 "No_Command" ;
VAL_TABLE_ TrnGear_D_RqPt 7 "Fault" 6 "NotUsed" 5 "Manual" 4 "Drive" 3 "Neutral" 2 "Reverse" 1 "Park" 0 "No_Gear" ;
VAL_TABLE_ TrnValidGearRq_D_Stat 3 "Valid_Request" 2 "Valid_Degraded_Request" 1 "Invalid_Request" 0 "No_Request" ;
VAL_TABLE_ NoData_Fault_3FE_3FF 1023 "Fault" 1022 "NoDataExists" ;
VAL_TABLE_ ClimtCool_D_Rq 7 "NotUsed4" 6 "NotUsed3" 5 "NotUsed2" 4 "ElACTestMde" 3 "Defrost_Defog" 2 "FastTempPullDownCoolReq" 1 "OpportunisticCoolingReq" 0 "NoCoolingRequest" ;
VAL_TABLE_ HtrnHvilOpen_B_Actl 1 "HVIL_is_Open" 0 "Normal_Operation" ;
VAL_TABLE_ EngTeHi_B_Actl 1 "EngineTempHigh" 0 "Normal" ;
VAL_TABLE_ Eng_D_StatPwPck 7 "NotUsed3" 6 "NotUsed2" 5 "Engine_Start_Cold_Cat" 4 "Engine_Disabled" 3 "Engine_Running" 2 "Engine_Run_CSER" 1 "Engine_Start" 0 "Off" ;
VAL_TABLE_ EngFuelCutFull_B_Inhbt 1 "Inhibit_DFSO" 0 "Normal" ;
VAL_TABLE_ EngFuelCutFull_B_Rq 1 "FuelCutRequest" 0 "NormalOperation" ;
VAL_TABLE_ Fault_7FF 2047 "Fault" ;
VAL_TABLE_ EngStopFst_B_Rq 1 "FastEngineShutdown" 0 "NormalOperation" ;
VAL_TABLE_ EngStrtCold_B_Rq 1 "ExtremeColdStart" 0 "NormalStart" ;
VAL_TABLE_ EngStrtSmooth_D_Rq 7 "NotUsed" 6 "Smooth_NoPedal" 5 "Smooth_LightPedal" 4 "Smooth_MediumPedal" 3 "Smooth_HeavyPedal" 2 "Smooth_WOP" 1 "Smooth_Cold" 0 "Smooth_ExtremeCold" ;
VAL_TABLE_ Fault_FFF 4095 "Fault" ;
VAL_TABLE_ VehStrtStop_D_Rq 3 "NotUsed" 2 "Vehicle_Start_Request" 1 "Vehicle_Stop_Request" 0 "NoRequest" ;
VAL_TABLE_ HvacRec_D_RqMxBatt 15 "NotUsed5" 14 "NotUsed4" 13 "NotUsed3" 12 "NotUsed2" 11 "NotUsed1" 10 "No_Override" 9 "90Percent_RecircMax" 8 "80Percent_RecircMax" 7 "70Percent_RecircMax" 6 "60Percent_RecircMax" 5 "50Percent_RecircMax" 4 "40Percent_RecircMax" 3 "30Percent_RecircMax" 2 "20Percent_RecircMax" 1 "10Percent_RecircMax" 0 "0Percent_RecircFullOpen" ;
VAL_TABLE_ FuelCtlOpenLp_B_Inhbt 1 " Inhibit_FullPedal_Actions" 0 "Normal_Operation" ;
VAL_TABLE_ EngStrtStop_B_SrcSrvc 1 "Eng_StartStop_for_Service" 0 "Not_Requested" ;
VAL_TABLE_ EngStrtStop_B_SrcCat 1 "Eng_StartStop_for_Catalyst" 0 "Not_Requested" ;
VAL_TABLE_ PrkBrkStatus 7 "GeneralFault_MaintenceMode" 6 "ECD_by_Brake_ECU_Active" 5 "EPB_Limphome_Active" 4 "Rear_Caliper_Open" 3 "RWU_By_EPB_Active" 2 "Rear_Caliper_Transition" 1 "Rear_Caliper_Closed" 0 "Not_Supported" ;
VAL_TABLE_ ElLoadCtl_D_Rq 7 "Unused3" 6 "Unused2" 5 "Unused1" 4 "HoldAllDrvrInvisibleLoads" 3 "StdDriverInvisibleLoadsOn" 2 "AllDriverInvisibleLoadsOn" 1 "All_Possible_Loads_Off" 0 "No_Request" ;
VAL_TABLE_ BattTracCool 3 "NotUsed" 2 "DCDC_Overtemperature" 1 "CoolingRequiredbyDCDC" 0 "NoCoolingRequiredbyDCDC" ;
VAL_TABLE_ Quality_Data 3 "OK" 2 "Not_Within_Specifications" 1 "Eval_In_Progress" 0 "Fault" ;
VAL_TABLE_ PwSrcULoFalt_D_Stat 3 "Fault_No_Output" 2 "Fault_Reduced_Output" 1 "Fault_NonSpecific" 0 "No_Fault" ;
VAL_TABLE_ Connect_Discon_Loose 1 "Loose_or_Disconnected" 0 "Connected" ;
VAL_TABLE_ DontCare_StartInhibit 1 "Start_Inhibit" 0 "Dont_Care" ;
VAL_TABLE_ BattULoChrg_D_Rq 3 "Low_Battery_Temperature" 2 "Charging_Requested" 1 "Chrg_Requested_HighCurrent" 0 "No_Request" ;
VAL_TABLE_ PwSysULoFalt_D_Stat 15 "Not_Used_6" 14 "LowBatterySOC" 13 "PSS_Shed2_Contin" 12 "Not_Used_4" 11 "Not_Used_3" 10 "Not_Used_2" 9 "BattMonitoringSensorFault" 8 "LowBattVoltDuringPwSrcOn" 7 "LowBatt2_PowerSaveMode" 6 "LowBatt1_Warning" 5 "Overvoltage" 4 "Fault_NoOutput" 3 "Fault_ReducedOutput" 2 "Fault_Nonspecific" 1 "Cluster_Proveout" 0 "No_Fault" ;
VAL_TABLE_ AccStopMde_D_Rq 3 "Stop_Mode_Active" 2 "EPBApplyOrBrakeReleaseWarn" 1 "Limit_Rolling_Speed" 0 "Stop_Mode_Not_Active" ;
VAL_TABLE_ EngFuelCutFull_B_Sched 1 "DFSO_Event_Scheduled" 0 "Normal" ;
VAL_TABLE_ Eng_D_Stat 3 "NotUsed" 2 "EngAutoStopped" 1 "EngOn" 0 "EngOff" ;
VAL_TABLE_ ElPw_D_Stat 7 "NotUsed_3" 6 "NotUsed_2" 5 "NotUsed_1" 4 "Fault_Limited" 3 "LV_Event_In_Progress" 2 "Not_Supported_Imminent" 1 "Supported" 0 "Not_Supported" ;
VAL_TABLE_ PwPckTq_D_Stat 3 "PwPckOn_TqAvailable" 2 "StartInPrgrss_TqNotAvail" 1 "PwPckOn_TqNotAvailable" 0 "PwPckOff_TqNotAvailable" ;
VAL_TABLE_ BattTracCool_D_Falt 3 "NotUsed" 2 "CoolSysPartialyOperational" 1 "Cooling_System_Faulted" 0 "Cooling_System_Operational" ;
VAL_TABLE_ Fault_FF 255 "Fault" ;
VAL_TABLE_ ElCmprOverTe_D_Stat 3 "OverTempStop" 2 "OverTempWarning" 1 "Normal" 0 "Undefined" ;
VAL_TABLE_ ElCmprUHi_D_Stat 3 "Overvoltage" 2 "Undervoltage" 1 "InRange" 0 "Undetermined" ;
VAL_TABLE_ ElCmpr_D_Stat 7 "Signal_Invalid" 6 "Comp_Off_ActlSpd_Abnormal" 5 "Comp_Off_TrgtSpd_OutRange" 4 "Comp_Shutdown" 3 "Comp_Stopped_Self_Protect" 2 "Comp_Degraded" 1 "Comp_On" 0 "Comp_Off" ;
VAL_TABLE_ PsngrFrntDetct_D_Actl 3 "Unknown" 2 "Empty" 0 "Faulty" 1 "Occupied" ;
VAL_TABLE_ Normal_Mode1_2 3 "Undefined" 2 "Mode2" 1 "Mode1" 0 "Normal_Mode" ;
VAL_TABLE_ Fault_3FF 1023 "Fault" ;
VAL_TABLE_ LockInhibit 1 "Inhibit" 0 "No_Inhibit" ;
VAL_TABLE_ Invalid_FFF 4095 "Invalid" ;
VAL_TABLE_ Off_0x0 0 "Off" ;
VAL_TABLE_ Shed_Feature_Group_ID 16 "PtcHeater" 30 "NotUsed_7" 29 "NotUsed_6" 28 "NotUsed_5" 27 "NotUsed_4" 26 "NotUsed_3" 25 "NotUsed_2" 24 "NotUsed_1" 23 "Dcac" 22 "UpFitter_6" 21 "UpFitter_5" 20 "UpFitter_4" 19 "UpFitter_3" 18 "UpFitter_2" 17 "UpFitter_1" 14 "HtdMirr" 13 "HvacRearBlwr_Third" 12 "HvacRearBlwr_Second" 11 "HvacRearBlwr_First" 31 "All LSHED1 Features" 10 "Htd_Windscrn" 9 "SpltHtdBcklight_HtdMirr" 8 "HtdBcklight_HtdMirr" 7 "HtdCoolSeat_FrtDriver" 6 "HtdCoolSeat_FrtPass" 5 "HtdCoolSeat_RearPass" 4 "HtdCoolSeat_RearDriver" 3 "SmartTrlrTowBattCharge" 2 "Htd_StrWhl" 1 "Htd_Washer_Fluid" 0 "No_LSHED1_Features" 15 "Engine_Coolant_Fan" ;
VAL_TABLE_ CoolantFanStepAct 31 "Unused7" 30 "Unused6" 29 "Unused5" 28 "Unused4" 27 "Unused3" 26 "Unused2" 25 "Unused1" 23 "Step23" 22 "Step22" 21 "Step21" 20 "Step20" 19 "Step19" 18 "Step18" 17 "Step17" 16 "Step16" 15 "Step15" 14 "Step14" 13 "Step13" 12 "Step12" 11 "Step11" 10 "Step10" 9 "Step9" 8 "Step8" 7 "Step7" 6 "Step6" 5 "Step5" 4 "Step4" 3 "Step3" 2 "Step2" 1 "Step1" 24 "Max_Fan_Speed_Req" 0 "Fan_Cmd_Off" ;
VAL_TABLE_ Veh_Lock_Requestor 31 "Walk_Away_Locking" 30 "Remote_Park_Assist" 29 "DoorsOffToOn_Smart_Unlock" 28 "Rgtm_Shutlock_Switch" 27 "Boundary_Alert" 26 "Transit_Vehicle_Relock" 25 "Transit_Cargo_Relock" 24 "Transit_Ajar_Lock" 23 "Diagnostics" 22 "Console_Lock" 21 "Child_Lock" 20 "Double_Lock" 19 "Passive_Pasenger" 18 "Passive_Driver" 17 "Slam_Lock_Protect" 16 "SYNC" 15 "Passport" 14 "Passive_Smart_Unlock" 13 "Autorelock" 12 "RemoteStart" 0 "Null" 1 "Autolock" 11 "Smart_Unlock" 10 "Sliding_Door" 9 "Passive" 8 "Remote" 7 "Programming" 6 "Powerslide" 5 "Keypad" 4 "Key_Cylinder" 3 "Interior" 2 "Auto_Unlock" ;
VAL_TABLE_ EPAS_FAILURE 3 "SERVICE_POWER_STEERING_NOW" 2 "SERVICE_POWER_STEERING" 1 "POWER_STRG_ASSIST_FAULT" 0 "EPAS_OK_NO_MESSAGE" ;
VAL_TABLE_ Perimeter_Alarm_Mode 3 "Activated" 2 "Armed" 1 "Prearmed" 0 "Disarmed" ;
VAL_TABLE_ Invalid_FFFF 65535 "Invalid" ;
VAL_TABLE_ OilPressureWarning 1 "Low_Pressure_Lamp_On" 0 "Normal_Pressure_Lamp_Off" ;
VAL_TABLE_ MyKey_KeyTypeChangeReq 3 "Search_PE_BackupSlot" 2 "Clear_All_MyKeys" 1 "Request_New_MyKey" 0 "None" ;
VAL_TABLE_ MyKey_Key_Count 13 "Thirteen" 12 "Twelve" 11 "Eleven" 10 "Ten" 9 "Nine" 8 "Eight" 7 "Seven" 6 "Six" 5 "Five" 4 "Four" 3 "Three" 2 "Two" 1 "One" 0 "Zero" 15 "Invalid" 14 "Unlimited" ;
VAL_TABLE_ GearEngag_D_Actl 7 "Undefined" 6 "Fwd_Clutch_Fully_Engaged" 5 "Neutral_Idle" 4 "Disengaged_to_Neutral_Idle" 3 "Disengaged_to_Neutral_Park" 2 "Engagement_in_Progress" 1 "InitializeFwdClutchEngagmt" 0 "Park_Neutral" ;
VAL_TABLE_ Shed_Level_Req 7 "SHED3" 6 "Loads_On" 5 "SHED_ENG_OFF" 4 "SOON_ENG_OFF" 3 "SHED2_CONTIN" 2 "SHED2_TRANS" 1 "SHED1" 0 "NO_SHED" ;
VAL_TABLE_ BpedMove_D_Actl 3 "Unknown" 2 "DriverApplyingBrakePedal" 1 "NoAutonomousBrkPdlMovement" 0 "AutonomousBrkPedalMove" ;
VAL_TABLE_ BattTracOffFst_D_Actl 3 "Unexpected_Contactor_Open" 2 "Restraints_Impact_Event" 1 "Interlock_Open" 0 "Normal" ;
VAL_TABLE_ Invalid_1FF 511 "Invalid" ;
VAL_TABLE_ ChargeMode 7 "Undefined_2" 6 "Undefined_1" 5 "Battery_Identify" 4 "Battery_Refresh" 3 "SlowRegenAllowNoDischarge" 2 "Fast_Regen_Allowed" 1 "Slow_Regen_Allowed" 0 "Conventional_Charging" ;
VAL_TABLE_ Unknown_FFFE_Invalid_FFFF 65535 "Invalid" 65534 "Unknown" ;
VAL_TABLE_ eCallConfirmation 7 "Unused_2" 6 "CallComplete_DTMF_Timeout" 5 "eCall_Configured_Off" 4 "Call_Unsuccessful" 3 "Call_Cancelled" 2 "Call_Completed" 1 "Call_In_Progress" 0 "Normal" ;
VAL_TABLE_ RKE_Filter_Ctrl 3 "Streaming" 2 "Filter" 1 "Not_Used" 0 "Null" ;
VAL_TABLE_ SAPPAngleControlStat5 1 "StrgColTorqueExceed_EAROn" 0 "ExternalSigContentOKforEAC" ;
VAL_TABLE_ Closed_Open_Active_Fault 3 "Fault" 2 "Active" 1 "Open" 0 "Closed" ;
VAL_TABLE_ SAPPAngleControlStat2 1 "Rel_ExtSteeringAngleReqx" 0 "NoRel_ExtSteeringAngleReqx" ;
VAL_TABLE_ SAPPAngleControlStat3 1 "EARactiveNoReverseEngage" 0 "ExternalSigContentOKforEAC" ;
VAL_TABLE_ RstrnImpactEvntStatus 7 "Invalid" 6 "Not_Used_4" 5 "Threshold_2_Exceeded" 4 "Not_Used_3" 3 "Threshold_1_Exceeded" 2 "Not_Used_2" 1 "Not_Used_1" 0 "Normal" ;
VAL_TABLE_ EDRTriggerEvntSync 1 "Threshold_Exceeded" 0 "Normal" ;
VAL_TABLE_ EngTeColdPrtct_D_Stats 3 "Engine_Warm_RdcPwr" 2 "OK_to_Drive" 1 "Engine_Warm_PlsWait" 0 "Normal_Operation" ;
VAL_TABLE_ HILL_DESC_MC 7 "Fault_Detected" 6 "Cooling_Down" 5 "Abort_Apply_Brakes" 4 "Active" 3 "Disabled" 2 "Enabled" 1 "Off_Road" 0 "Normal" ;
VAL_TABLE_ Closed_Ajar 1 "Ajar" 0 "Closed" ;
VAL_TABLE_ Quality_Factor 3 "OK" 2 "Not_Within_Specifications" 1 "No_Data_Exists" 0 "Faulty" ;
VAL_TABLE_ Null_Day_Night 3 "NotUsed" 2 "Night" 1 "Day" 0 "Null" ;
VAL_TABLE_ Null_Flash_High 3 "NotUsed" 2 "High" 1 "Flash_to_Pass" 0 "Null" ;
VAL_TABLE_ GearPos_D_Actl 15 "Unknown" 14 "Reverse" 13 "Undefined_5" 12 "Undefined_4" 11 "Undefined_3" 10 "Tenth" 9 "Ninth" 8 "Eighth" 7 "Seventh" 6 "Sixth" 5 "Fifth" 4 "Fourth" 3 "Third" 2 "Second" 1 "First" 0 "Neutral" ;
VAL_TABLE_ OffOn_SlowFast_Flash 3 "Fast_Flash" 2 "Slow_Flash" 1 "On" 0 "Off" ;
VAL_TABLE_ AwdStat_D_RqDsply 31 "Rear_Diff_Lock_Not_Avail" 30 "_4wd_Lock_Required" 29 "Cfg_Perf_Redc_See_Manual" 28 "To_Engage_4x4_Release_Aped" 27 "To_Engage_4x4_Slow_To_3MPH" 26 "Shift_To_Neutral" 25 "Lkr_Mode_Unavail_TMS" 24 " _4x4_Mode_Unavail_TMS" 23 "Out_of_4Low_Crawl" 22 "AWD_PTU_Oil_Changed" 21 "Change_AWD_PTU_Oil" 20 "Neutral_Tow_Disabled" 19 "Neutral_Tow_Enabled" 18 "AWD_OFF" 17 "_4x4_Off_Road_Speed" 16 "_4x4_Extreme_Off_Road_Mode" 15 "_4x4_Exiting_Off_Road" 14 "_4x4_Off_Road_Mode" 10 "_4x4_Locked_Temporarily" 9 "Shift_In_Progress" 13 "Blocked_Shift_Assist" 12 "_4x4_Auto_Restored" 11 "_4x4_Disabled_Temporarily" 7 "Out_of_4Low__Neutral" 6 "Out_of_4Low__Brake" 5 "Out_of_4Low__Speed" 4 "Into_4Low__Clutch" 3 "Into_4Low__Neutral" 2 "Into_4Low__Brake" 1 "Into_4Low__Speed" 0 "Normal__No_Message" 8 "Out_of_4Low__Clutch" ;
VAL_TABLE_ AngleReached 1 "RequestedAngleNotReached" 0 "RequestedAngleCanBeReached" ;
VAL_TABLE_ WhlDir 3 "Faulty" 2 "NoDataExists" 1 "Backward" 0 "Forward" ;
VAL_TABLE_ VehVLimStat_D_Actl 7 "Undefined_3" 6 "Undefined_2" 5 "Undefined_1" 4 "ASL_Fault_Condition" 3 "Active_and_Limiting" 2 "Active_but_Not_Limiting" 1 "Standby" 0 "Off" ;
VAL_TABLE_ Fault_NoFault 1 "Fault" 0 "No_Fault" ;
VAL_TABLE_ TerrMde_D_Actl 7 "Fail_Safe_Default" 6 "Dynamic_Mode" 5 "Rock_Crawl_Mode" 4 "Mud_Ruts_Mode" 3 "Sand_Mode" 2 "Undefined" 1 "Low_Mu_Mode" 0 "Special_Operating_Mode_Off" ;
VAL_TABLE_ TerrMdeChng_D_Rdy 7 "Fault" 6 "Undefined_2" 5 "Undefined_1" 4 "ModeUnavailDrInputRqd" 3 "SpOpModes_NotSupported" 2 "ModeUnavailDynamicCond" 1 "Module_In_Initialization" 0 "Mode_Change_Available" ;
VAL_TABLE_ Unknown_Fault_FFFE_FFFF 65535 "Fault" 65534 "Unknown" ;
VAL_TABLE_ Invalid_FFFFFF 16777215 "Invalid" ;
VAL_TABLE_ AutoParkSpdExitCond 1 "SpeedLimitExceededEAROn" 0 "ExternalSigContentOKforEAC" ;
VAL_TABLE_ EngOilLvlDsply_D_Rq 15 "EngOil_LevelSys_CheckFault" 14 "Reserved_2" 13 "Reserved_1" 12 "Conditions_Unsuitable" 11 "Dipstick_Below_Minimum" 10 "Dipstick_Above_Maximum" 9 "Dipstick_Minimum" 8 "Dipstick_12_5_MinMaxRange" 7 "Dipstick_25_MinMaxRange" 6 "Dipstick_37_5_MinMaxRange" 5 "Dipstick_50_MinMaxRange" 4 "Dipstick_62_5_MinMaxRange" 3 "Dipstick_75_MinMaxRange" 2 "Dipstick_87_5_MinMaxRange" 1 "Dipstick_Maximum_Displayed" 0 "No_Message" ;
VAL_TABLE_ HdcMde_D_Actl 7 "Fault" 6 "Temporarily_Unavailable" 5 "NotEnabled_WrongGearSel" 4 "NotEnabled_SpdLimitExceed" 3 "Active_Braking" 2 "Not_Active_Braking" 1 "Off" 0 "Undefined" ;
VAL_TABLE_ GearLvrPos_D_Actl 15 "Fault" 14 "Unknown_Position" 13 "Undefined_Treat_as__Fault" 12 "Undefined_Treat_as_Fault" 11 "sixth" 10 "fifth" 9 "fourth" 8 "third" 7 "second" 6 "first" 5 "Low" 4 "Sport_DriveSport" 3 "Drive" 2 "Neutral" 1 "Reverse" 0 "Park" ;
VAL_TABLE_ EngTurboMde_D_Actl 3 "Fault" 2 "One_Turbo_Active" 1 "Two_Turbos_Active" 0 "Initializing" ;
VAL_TABLE_ EngPullUpPullDown 15 "Undefined_7" 14 "Undefined_6" 13 "Undefined_5" 12 "Undefined_4" 8 "Force_Pull_Down" 7 "Force_Pull_Up" 6 "PullDown_Inhibit_PullUp" 5 "Inhibit_Change" 4 "Inhibit_Pull_Up" 3 "Pull_Down" 2 "Inhibit_Pull_Down" 1 "Pull_Up" 0 "No_Request" 11 "Undefined_3" 10 "Undefined_2" 9 "Undefined_1" ;
VAL_TABLE_ EngMde_D_Rq 8 "VSC_Sets_Speed_Type_3" 7 "VSC_Sets_Speed_Type_2" 6 "VSC_Sets_Torque_Type_2" 5 "Dependability_Shutdown" 4 "Dependability_Follow" 3 "Start" 2 "VSC_Sets_Torque_Type_1" 1 "VSC_Sets_Speed_Type_1" 0 "Off" 15 "Undefined_7" 14 "Undefined_6" 13 "Undefined_5" 12 "Undefined_4" 11 "Undefined_3" 10 "Undefined_2" 9 "Undefined_1" ;
VAL_TABLE_ DrvHdcMsg_D_Rq 7 "Undefined" 6 "Speed_too_High" 5 "Temporarily_Unavailable" 4 "System_Fault" 3 "Select_Gear" 2 "Off" 1 "On" 0 "No_Message" ;
VAL_TABLE_ CcStat_D_Actl 7 "Undefined_2" 6 "Undefined_1" 5 "Active" 4 "Active_Que_Assist" 3 "Standby" 2 "Standby_Denied" 1 "Denied" 0 "Off" ;
VAL_TABLE_ BpedDrvAppl_D_Actl 3 "_Not_Allowed" 2 "Driver_Braking" 1 "Driver_Not_Braking" 0 "Not_Allowed" ;
VAL_TABLE_ AslIconDsply_D_Rq 3 "On_Passive_Overridden" 2 "On_Active" 1 "On_Passive" 0 "Off" ;
VAL_TABLE_ AccEngStat_D_Actl 7 "Undefined_2" 6 "Undefined_1" 5 "ACCSoonCancel_due_Low_Spd" 4 "Shift_Down_Recommendation" 3 "Shift_Up_Recommendation" 2 "ACCNotAllowedToBeActivated" 1 "ACCStandby_due_Auto_Cancel" 0 "Normal_Operation" ;
VAL_TABLE_ NotPressed_Pressed 1 "Pressed" 0 "Not_Pressed" ;
VAL_TABLE_ TrnGear_D_RqDrv 31 "Fault" 30 "NotUsed_25" 29 "NotUsed_24" 28 "NotUsed_23" 27 "NotUsed_22" 26 "NotUsed_21" 25 "NotUsed_20" 24 "NotUsed_19" 23 "NotUsed_18" 22 "NotUsed_17" 21 "Return_To_Park" 20 "NotUsed_15" 19 "NotUsed_14" 18 "NotUsed_13" 17 "NotUsed_12" 16 "Manual" 15 "Not_Used11" 14 "Not_Used10" 13 "NotUsed_9" 12 "NotUsed_8" 11 "NotUsed_7" 10 "NotUsed_6" 9 "NotUsed_5" 8 "Drive" 7 "NotUsed_4" 6 "NotUsed_3" 5 "NotUsed_2" 4 "Neutral" 3 "NotUsed_1" 2 "Reverse" 1 "Park" 0 "No_Gear" ;
VAL_TABLE_ Open_Close 1 "Close" 0 "Open" ;
VAL_TABLE_ OpenCloseRetainUndef 3 "Undefined" 2 "Retain" 1 "Close" 0 "Open" ;
VAL_TABLE_ DasWarn 3 "Undefined" 2 "Warning_Level_2" 1 "Warning_Level_1" 0 "No_Warning" ;
VAL_TABLE_ DasAlert 5 "Alertness_Level_5" 4 "Alertness_Level_4" 3 "Alertness_Level_3" 2 "Alertness_Level_2" 1 "Alertness_Level_1" 0 "Undefined" ;
VAL_TABLE_ DasStat 3 "Available" 2 "Unavailable_Other" 1 "Feedback_due_to_Speed" 0 "Off" ;
VAL_TABLE_ No_Crank_Req 1 "Crank_Request" 0 "No_Crank_Request" ;
VAL_TABLE_ DrvSlipCtlMde_D_Rq 3 "App_Specific_Off_Mode_3" 2 "App_Specific_Off_Mode_2" 1 "App_Specific_Off_Mode_1" 0 "Default_Mode" ;
VAL_TABLE_ AwdOffRoadMode 3 "Invalid" 2 "Extreme_Off_Road" 1 "Off_Road" 0 "Normal_Mode" ;
VAL_TABLE_ NotQuiet_Quiet 1 "Quiet" 0 "Not_Quiet" ;
VAL_TABLE_ Remote_Device_Feedback 7 "Unused3" 6 "Unused2" 5 "Unused1" 4 "Shutdown" 3 "Running" 2 "Starting" 1 "Acknowledge" 0 "Null" ;
VAL_TABLE_ Remote_Start_Req 3 "Not_Used" 2 "Remote_Cancel" 1 "Remote_Start" 0 "No_Request" ;
VAL_TABLE_ Modulation_Ctrl 3 "Unused" 2 "FSK" 1 "ASK_FSK" 0 "ASK" ;
VAL_TABLE_ TrnManShif_D_IndDrv 7 "Undefined_3" 6 "Undefined_2" 5 "Shift_to_Neutral" 4 "Downshift_Recommendation" 3 "Upshift_Warning" 2 "Upshift_Performance" 1 "Upshift_Fuel_Economy" 0 "No_Indication" ;
VAL_TABLE_ Unlock_Lock 1 "Locked" 0 "Unlock" ;
VAL_TABLE_ DieslPrtc_D_RqDsply 7 "Unused_2" 6 "Unused_1" 5 "DPF_SOOT_Level3_Blocked" 4 "DPFSootLvl2_SevereOverload" 3 "DPFRegen_ExhFilterComplete" 2 "DPFRegen_CleanExhFilter" 1 "DPF_Soot_Level1_Overloaded" 0 "DPF_OK_Normal_Operation" ;
VAL_TABLE_ PE_BackupSlot_Status 3 "No_Valid_FOB_In_Slot" 2 "MyKey_FOB_In_Slot" 1 "Standard_FOB_In_Slot" 0 "Null" ;
VAL_TABLE_ Unknown_Fault_FFE_FFF 4095 "Fault" 4094 "Unknown" ;
VAL_TABLE_ Unknown_Fault_1FFE_1FFF 8191 "Fault" 8190 "Unknown" ;
VAL_TABLE_ TrnCnvtClu_D_Actl 3 "Transition_or_Micro_Slip" 2 "Lock_Up_Fixed" 1 "Lock_Up_Slip" 0 "No_Lock_Up" ;
VAL_TABLE_ InhibitNoinhibit 1 "Inhibit" 0 "No_Inibit" ;
VAL_TABLE_ DisableEnable 1 "Enable" 0 "Disable" ;
VAL_TABLE_ Unknown_Fault_7FFE_7FFF 32767 "Fault" 32766 "Unknown" ;
VAL_TABLE_ Litval_values 255 "Invalid" 254 "Unknown" 5 "Day" 4 "Twilight_4" 3 "Twilight_3" 2 "Twilight_2" 1 "Twilight_1" 0 "Night" ;
VAL_TABLE_ Dimming_Lvl 255 "Invalid" 254 "Unknown" 18 "Day_6" 17 "Day_5" 16 "Day_4" 15 "Day_3" 14 "Day_2" 13 "Day_1" 12 "Night_12" 11 "Night_11" 10 "Night_10" 9 "Night_9" 8 "Night_8" 7 "Night_7" 6 "Night_6" 5 "Night_5" 4 "Night_4" 3 "Night_3" 2 "Night_2" 1 "Night_1" 0 "Off" ;
VAL_TABLE_ EngStrtStop_B_SrcChtLo 1 "Eng_StartStop_for_CHT_Low" 0 "Not_Requested" ;
VAL_TABLE_ EngStrtStop_B_SrcChtHi 1 "Eng_StartStop_for_CHT_Hi" 0 "Not_Requested" ;
VAL_TABLE_ EngDiag_D_RqHtrn 7 "NotUsed4" 6 "NotUsed3" 5 "NotUsed2" 4 "NoUsed1" 3 "Eng_Diag_Cstdn" 2 "Eng_Diag_Run" 1 "Eng_Diag_Crank" 0 "Eng_Diag_Normal" ;
VAL_TABLE_ NotOperating 1 "Operating" 0 "Not_Operating" ;
VAL_TABLE_ CamraStat 3 "FrtCam_TempUnavailOther" 2 "FrtCam_TempUnavailVisibile" 1 "Front_Camera_Service_Reqd" 0 "Front_Camera_OK" ;
VAL_TABLE_ EngPtoMde_D_Actl 7 "Undefined" 6 "Split_Shaft_Stationary" 5 "Not_Used_2" 4 "PTO_Mobile" 3 "Not_Used_1" 2 "PTO_Stationary" 1 "BCP" 0 "Off" ;
VAL_TABLE_ Remote_Start_Status 3 "Invalid" 2 "Unknown" 1 "Remote" 0 "Null" ;
VAL_TABLE_ Lock_Subld 15 "Unused7" 14 "Unused6" 13 "Unused5" 12 "Unused4" 11 "Unused3" 10 "Unused2" 9 "Unused1" 8 "Customer_8" 7 "Customer_7" 6 "Customer_6" 5 "Customer_5" 4 "Customer_4" 3 "Customer_3" 2 "Customer_2" 1 "Customer_1" 0 "Null" ;
VAL_TABLE_ Brake_Fluid 3 "Invalid" 2 "Unknown" 1 "Low" 0 "OK" ;
VAL_TABLE_ Unknown_Invalid_FE_FF 255 "Invalid" 254 "Unknown" ;
VAL_TABLE_ Invalid_FF 255 "Invalid" ;
VAL_TABLE_ NotLow_Low 1 "Low" 0 "Not_Low" ;
VAL_TABLE_ Key_In_Ignition_Status 1 "In" 0 "Out" ;
VAL_TABLE_ Ignition_Status 0 "Unknown" 1 "Off" 15 "Invalid" 8 "Start" 4 "Run" 2 "Accessory" ;
VAL_TABLE_ Disabled_Enabled_Faulted 3 "Faulted" 2 "Unused" 1 "Enabled" 0 "Disabled" ;
VAL_TABLE_ Unknown_Fault_FE_FF 255 "Fault" 254 "Unknown" ;
VAL_TABLE_ Null_Unlock 1 "Unlock" 0 "Null" ;
VAL_TABLE_ Null_Active 1 "Active" 0 "Null" ;
VAL_TABLE_ HsaStat_D_Actl 7 "Faulty" 6 "FaultyWithDriverIndication" 5 "SlowRelease" 4 "FastRelease" 3 "ActiveBrakePedalReleased" 2 "ActiveBrakePedalPressed" 1 "FindingGradient" 0 "Inactive" ;
VAL_TABLE_ Off_Auto_Manual 3 "Undefined" 2 "Manual" 1 "Automatic" 0 "Off" ;
VAL_TABLE_ HsaStat_D_Dsply 7 "NotUsed3" 6 "NotUsed2" 5 "NotUsed1" 4 "NotAvailable" 3 "SlowReleaseWithChime" 2 "SlowReleaseWithoutChime" 1 "Active" 0 "Inactive" ;
VAL_TABLE_ EngMsgTxt_D_Rq 3 "Undefined_2" 2 "Undefined_1" 1 "Power_Reduced_to_LowerTemp" 0 "No_Message" ;
VAL_TABLE_ PassRstrnInd_Req 3 "ABOnNotIllum_OffNotIllum" 2 "AirbagOnNot_Illum_OffIllum" 1 "AirbagOn_Illum_OffNotIllum" 0 "AirbagOn_Illum_Off_Illum" ;
VAL_TABLE_ DrvHdcWarnInfo_D_Rq 3 "Undefined" 2 "Lamp_On_Continuously" 1 "Lamp_Flashing" 0 "Lamp_Off_Continuously" ;
VAL_TABLE_ DieslPrtcRgen_D_Actl 3 "Undefined" 2 "Regen_Level_2" 1 "Regen_Level_1" 0 "No_regen" ;
VAL_TABLE_ Off_On 1 "On" 0 "Off" ;
VAL_TABLE_ CcMde_D_Actl 7 "TapDownWaiting" 6 "TapUpWaiting" 5 "Resuming_Low" 4 "Resuming_High" 3 "Decelerating" 2 "Accelerating" 1 "Keeping_Speed" 0 "Not_Active" ;
VAL_TABLE_ InactiveActive 1 "Active" 0 "Inactive" ;
VAL_TABLE_ ManRgenTxt_D_RqDsply 7 "NotUsed3" 6 "NotUsed2" 5 "NotUsed1" 4 "Cleaning_Aborted_Stopped" 3 "Cleaning_Completed" 2 "Cleaning_In_Progress" 1 "Cleaning_Allowed" 0 "Cleaning_Not_Allowed" ;
VAL_TABLE_ Fault_FFFF 65535 "Fault" ;
VAL_TABLE_ Fault_7F 127 "Fault" ;
VAL_TABLE_ EngOilLvlWarn_D_Rq 7 "Undefined_3" 6 "Undefined_2" 5 "Engine_Oil_Monitor_Fault" 3 "Engine_Oil_High" 2 "Engine_Oil_Critical_Low" 1 "Engine_Oil_Low" 0 "No_Message" 4 "Engine_Oil_Critical_High" ;
VAL_TABLE_ Unknown_Invalid_1E_1F 31 "Invalid" 30 "Unknown" ;
VAL_TABLE_ NoYes 1 "Yes" 0 "No" ;
VAL_TABLE_ AwdRnge_D_Actl 7 "Unknown" 6 "High_Range_2wd" 5 "High_Range_Auto" 4 "High_Range_Locked" 3 "Neutral" 2 "Low_Range_2wd" 1 "Low_Range_Auto" 0 "Low_Range_Locked" ;
VAL_TABLE_ AwdLck_D_Stat 9 "Undefined" 8 "Under_External_Torque_Ctrl" 7 "Torque_Limited_by_Cmd" 6 "Fully_Locked_by_Cmd" 5 "Disabled" 4 "Warning" 3 "Fault" 2 "Inactive" 1 "Completely_Opened_by_Cmd" 0 "OK" ;
VAL_TABLE_ Unknown_Fault_3FE_3FF 1023 "Fault" 1022 "Unknown" ;
VAL_TABLE_ LockSwStat 3 "Invalid" 2 "Unlock" 1 "Lock" 0 "Null" ;
VAL_TABLE_ Null_Override 1 "Override" 0 "Null" ;
VAL_TABLE_ Off_On_Flash 3 "Not_Used" 2 "Flash" 1 "On" 0 "Off" ;
VAL_TABLE_ immoTargetStatCoding 7 "Unused4" 6 "Unused3" 5 "Unused2" 4 "ENABLED_LIMITEDMOTIVE_STAR" 3 "DISABLED_RESET   " 2 "ENABLED_NONMOTIVE_START" 1 "ENABLED_MOTIVE_START" 0 "DISABLED" ;
VAL_TABLE_ BeltBuckle 3 "Unknown" 2 "Unbelted" 1 "Belted" 0 "Faulty" ;
VAL_TABLE_ RILReqCoding 3 "Not_Used" 2 "Plant_Mode" 1 "On" 0 "Off" ;
VAL_TABLE_ Update_Bit 1 "Fresh_data" 0 "Unchanged_data" ;
VAL_TABLE_ Tire_Pressure_Stat 4 "Alert" 15 "Not_Supported" 3 "Fault" 2 "Low" 1 "Normal" 0 "Unknown" ;
VAL_TABLE_ Tire_Pressure_System2 13 "Training_Complete" 12 "Train_InsideLeftRear_tire" 11 "Train_OutsideLeftRear_tire" 10 "Train_LeftRear_tire" 9 "Train_InsideRtRear_tire" 8 "Train_OutsideRtRear_tire" 7 "Train_RightRear_tire" 14 "Tires_not_trained" 6 "Train_RightFront_tire" 5 "Train_LeftFront_tire" 4 "Systm_Activ_Composite_Stat" 3 "Low_Composite_Stat" 2 "Sensr_Fault_Composite_Stat" 1 "Systm_Fault_Composite_Stat" 0 "Unknown_Composite_Stat" ;
VAL_TABLE_ Turn_Seq 3 "Seq" 2 "On" 1 "Off" 0 "Null" ;
VAL_TABLE_ immoTargetCmdCoding 7 "Unused4" 6 "Unused3" 5 "Unused2" 4 "Unused1" 3 "TARGET1_IDBLOCK2" 2 "TARGET1_IDBLOCK1" 1 "CHALLENGE" 0 "IDLE" ;
VAL_TABLE_ immoCtrlCmd2Coding 0 "IDLE" 1 "MOTIVE_START_RQST" 2 "NONMOTIVE_START_RQST" 3 "RQST_TARGET2_IDBLOCK1" 4 "RQST_TARGET2_IDBLOCK2" 5 "LIMITEDMOTIVE_START_RQST" 6 "ECHO_TARGET2_IDBLOCK2" 7 "SHUTDOWN" ;
VAL_TABLE_ immoCtrlCmdCoding 0 "IDLE" 1 "MOTIVE_START_RQST" 2 "NONMOTIVE_START_RQST" 3 "RQST_TARGET1_IDBLOCK1" 4 "RQST_TARGET1_IDBLOCK2" 5 "LIMITEDMOTIVE_START_RQST" 6 "ECHO_TARGET1_IDBLOCK2" 7 "SHUTDOWN" ;
VAL_TABLE_ Invalid_Active_Inactive 3 "Not_Used" 2 "Inactive" 1 "Active" 0 "Invalid" ;
VAL_TABLE_ Rvc_Zoom 7 "Unknown" 6 "Invalid" 5 "Zoom_Level_V" 4 "Zoom_Level_IV" 3 "Zoom_Level_III" 2 "Zoom_Level_II" 1 "Zoom_Level_I" 0 "Off" ;
VAL_TABLE_ NotPark 1 "Park" 0 "Not_Park" ;
VAL_TABLE_ PersOptIn 1 "OPTED_IN" 0 "NOT_OPTED_IN" ;
VAL_TABLE_ PersonalSetUp 3 "Non_Moveable_Person" 2 "Moveable_Person" 1 "Vehicle" 0 "Factory" ;
VAL_TABLE_ Full_Limited 1 "Limited" 0 "Full" ;
VAL_TABLE_ NoConflict_Conflict 1 "Conflict" 0 "No_Conflict" ;
VAL_TABLE_ Assoc_Confirm 0 "None" 7 "Associate" 6 "Keycode_Rejected" 5 "Keycode_Accepted" 4 "In_Progress" 3 "Erase" 2 "Duplicate" 1 "Disassociate" ;
VAL_TABLE_ Check_KeyCode 7 "Unused_2" 6 "Cancel" 5 "Set_Keycode" 4 "RKE" 3 "Null" 2 "Key" 1 "Erase_KeyCode" 0 "Check_KeyCode" ;
VAL_TABLE_ Complete_Inprogress 3 "Unused" 2 "Null" 1 "InProgress" 0 "Complete" ;
VAL_TABLE_ Null_Pers1_4 7 "Unused_3" 6 "Unused_2" 5 "Unused_1" 4 "PERS_4" 3 "PERS_3" 2 "PERS_2" 1 "PERS_1" 0 "Null" ;
VAL_TABLE_ Pers1_4 7 "Unused_3" 6 "Unused_2" 5 "Unused_1" 4 "Vehicle" 3 "PERS_4" 2 "PERS_3" 1 "PERS_2" 0 "PERS_1" ;
VAL_TABLE_ Null_Query 7 "Unused_2" 6 "Unused_1" 5 "Copy" 4 "Restore" 3 "Upload" 2 "Set" 1 "Query" 0 "Null" ;
VAL_TABLE_ EngExhBrkMde_D_Actl 6 "ExhBrkDisable_NoError" 5 "ExhBrkActive_AUTO" 4 "ExhBrkActive_ON" 3 "ExhBrkRequest_AUTO" 2 "ExhBrkRequest_ON" 1 "ExhBrkNoRequest_OFF" 0 "ExhBrkUnavailable_Error" ;
VAL_TABLE_ CCOverridden 1 "Cruise_Overridden" 0 "Cruise_Req_Not_Overridden" ;
VAL_TABLE_ Ign_Key_Device_Type 15 "Invalid" 14 "Unknown" 3 "Key_Not_Prgrm_Read_Failure" 2 "Key_In_Ign_My_Key" 1 "Key_In_Ign_Standard_Key" 0 "Key_Read_In_Progress" ;
VAL_TABLE_ Off_No_Eff_Unknown_Invalid 3 "Invalid" 2 "Unknown" 1 "No_Effect" 0 "Off" ;
VAL_TABLE_ Null_Out 1 "Out" 0 "Null" ;
VAL_TABLE_ FUEL_SENSORS 1 "Dual_Sensors" 0 "Single_Sensor" ;

BO_ 2612037848 PARSEDPushFcGWMECGtoSOBDMB: 8 GWM
 SG_ PARSEDPushFcGWMECGtoSOBDMB : 7|29@0+ (1,0) [0|536870911] "unitless"  SOBDMB_AWDC

BO_ 2610989272 PARSEDPhysGWM_ECGtoSOBDMB: 8 GWM
 SG_ PARSEDPhysGWM_ECGtoSOBDMB : 7|29@0+ (1,0) [0|536870911] "Unitless"  SOBDMB_AWDC

BO_ 2609940696 OTAPhysGWM_ECGtoSOBDMB: 8 GWM
 SG_ OTAPhysGWM_ECGtoSOBDMB : 7|29@0+ (1,0) [0|536870911] "unitless"  SOBDMB_AWDC

BO_ 2023 TesterPhysicalReqSOBDMB: 8 TSTR
 SG_ TesterPhysicalReqSOBDMB : 7|64@0+ (1,0) [0|1.84467E+019] "unitless"  SOBDMB_AWDC

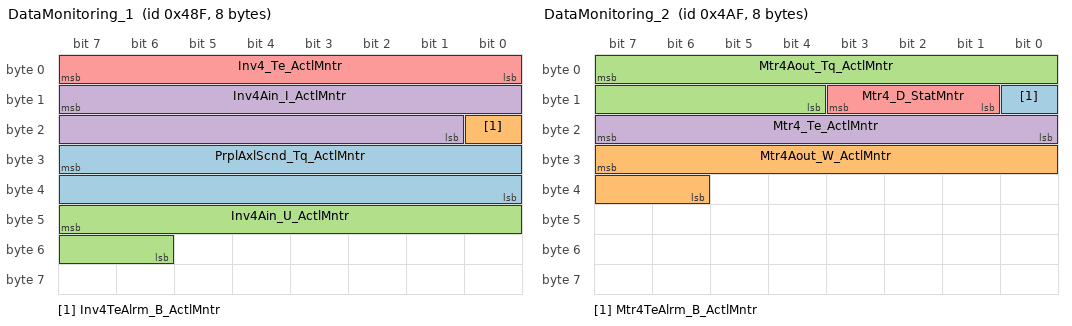
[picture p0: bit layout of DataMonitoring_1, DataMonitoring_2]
BO_ 1167 DataMonitoring_1: 8 SOBDMB_AWDC
 SG_ PrplAxlScnd_Tq_ActlMntr : 31|16@0+ (4,-131072) [-131072|131060] "Nm"  GWM
 SG_ Inv4TeAlrm_B_ActlMntr : 16|1@0+ (1,0) [0|1] "SED"  GWM
 SG_ Inv4Ain_U_ActlMntr : 47|10@0+ (0.5,0) [0|510.5] "volt"  GWM
 SG_ Inv4Ain_I_ActlMntr : 15|15@0+ (0.1,-1000) [-1000|2276.5] "ampere"  GWM
 SG_ Inv4_Te_ActlMntr : 7|8@0+ (1,-40) [-40|213] "degC"  GWM

BO_ 1199 DataMonitoring_2: 8 SOBDMB_AWDC
 SG_ Mtr4TeAlrm_B_ActlMntr : 8|1@0+ (1,0) [0|1] "SED"  GWM
 SG_ Mtr4Aout_W_ActlMntr : 31|10@0+ (6.28,-3209) [-3209|3209.16] "radians/sec"  GWM
 SG_ Mtr4Aout_Tq_ActlMntr : 7|12@0+ (1,-2047) [-2047|2048] "Nm"  GWM
 SG_ Mtr4_Te_ActlMntr : 23|8@0+ (1,-40) [-40|213] "degC"  GWM
 SG_ Mtr4_D_StatMntr : 11|3@0+ (1,0) [0|7] "SED"  GWM

BO_ 1705 SOBDMB_RapidDataResponse_2: 8 SOBDMB_AWDC
 SG_ UUDTSOBDMBResponse2 : 7|64@0+ (1,0) [0|1.84467440737096E+019] "unitless"  TSTR

BO_ 1704 SOBDMB_RapidDataResponse_1: 8 SOBDMB_AWDC
 SG_ UUDTSOBDMBResponse1 : 7|64@0+ (1,0) [0|1.84467440737096E+019] "unitless"  TSTR

BO_ 2612224034 PARSEDPushSOBDMBtoGWM_ECG: 8 SOBDMB_AWDC
 SG_ PARSEDPushSOBDMBtoGWM_ECG : 7|29@0+ (1,0) [0|536870911] "unitless"  GWM

BO_ 2611175458 PARSEDPhysSOBDMBtoGWM_ECG: 8 SOBDMB_AWDC
 SG_ PARSEDPhysSOBDMBtoGWM_ECG : 7|29@0+ (1,0) [0|536870911] "unitless"  GWM

BO_ 2610126882 OTAPhysSOBDMBtoGWM_ECG: 8 SOBDMB_AWDC
 SG_ OTAPhysSOBDMBtoGWM_ECG : 7|29@0+ (1,0) [0|536870911] "unitless"  GWM

BO_ 2031 TesterPhysicalResSOBDMB: 8 SOBDMB_AWDC
 SG_ TesterPhysicalResSOBDMB : 7|64@0+ (1,0) [0|1.84467E+019] "unitless"  TSTR

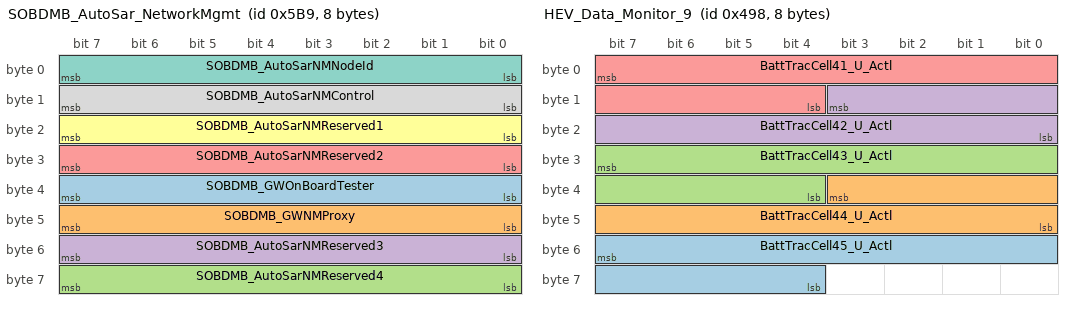
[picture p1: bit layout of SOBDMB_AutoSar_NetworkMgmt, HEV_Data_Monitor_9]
BO_ 1465 SOBDMB_AutoSar_NetworkMgmt: 8 SOBDMB_AWDC
 SG_ SOBDMB_GWOnBoardTester : 39|8@0+ (1,0) [0|255] "unitless"  GWM
 SG_ SOBDMB_GWNMProxy : 47|8@0+ (1,0) [0|255] "unitless"  GWM
 SG_ SOBDMB_AutoSarNMReserved4 : 63|8@0+ (1,0) [0|255] "unitless"  GWM
 SG_ SOBDMB_AutoSarNMReserved3 : 55|8@0+ (1,0) [0|255] "unitless"  GWM
 SG_ SOBDMB_AutoSarNMReserved2 : 31|8@0+ (1,0) [0|255] "unitless"  GWM
 SG_ SOBDMB_AutoSarNMReserved1 : 23|8@0+ (1,0) [0|255] "unitless"  GWM
 SG_ SOBDMB_AutoSarNMNodeId : 7|8@0+ (1,0) [0|255] "unitless"  GWM
 SG_ SOBDMB_AutoSarNMControl : 15|8@0+ (1,0) [0|255] "unitless"  GWM

BO_ 1176 HEV_Data_Monitor_9: 8 GWM
 SG_ BattTracCell45_U_Actl : 55|12@0+ (0.001,1) [1|5.093] "volt" Vector__XXX
 SG_ BattTracCell44_U_Actl : 35|12@0+ (0.001,1) [1|5.093] "volt" Vector__XXX
 SG_ BattTracCell43_U_Actl : 31|12@0+ (0.001,1) [1|5.093] "volt" Vector__XXX
 SG_ BattTracCell42_U_Actl : 11|12@0+ (0.001,1) [1|5.093] "volt" Vector__XXX
 SG_ BattTracCell41_U_Actl : 7|12@0+ (0.001,1) [1|5.093] "volt" Vector__XXX

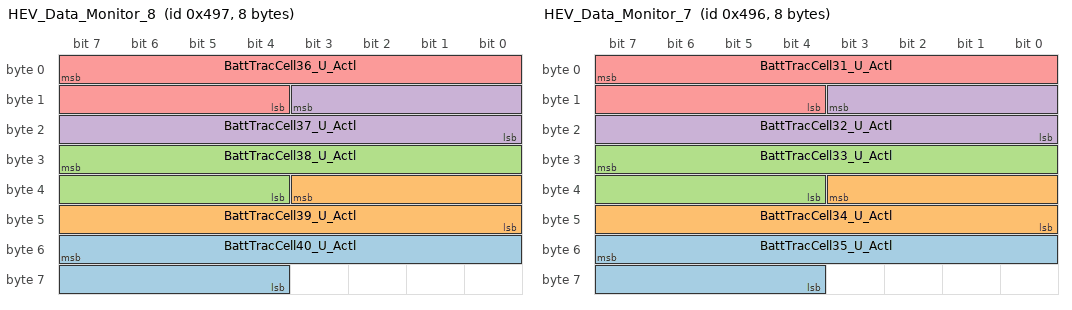
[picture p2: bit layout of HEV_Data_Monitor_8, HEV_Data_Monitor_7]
BO_ 1175 HEV_Data_Monitor_8: 8 GWM
 SG_ BattTracCell40_U_Actl : 55|12@0+ (0.001,1) [1|5.093] "volt" Vector__XXX
 SG_ BattTracCell39_U_Actl : 35|12@0+ (0.001,1) [1|5.093] "volt" Vector__XXX
 SG_ BattTracCell38_U_Actl : 31|12@0+ (0.001,1) [1|5.093] "volt" Vector__XXX
 SG_ BattTracCell37_U_Actl : 11|12@0+ (0.001,1) [1|5.093] "volt" Vector__XXX
 SG_ BattTracCell36_U_Actl : 7|12@0+ (0.001,1) [1|5.093] "volt" Vector__XXX

BO_ 1174 HEV_Data_Monitor_7: 8 GWM
 SG_ BattTracCell35_U_Actl : 55|12@0+ (0.001,1) [1|5.093] "volt" Vector__XXX
 SG_ BattTracCell34_U_Actl : 35|12@0+ (0.001,1) [1|5.093] "volt" Vector__XXX
 SG_ BattTracCell33_U_Actl : 31|12@0+ (0.001,1) [1|5.093] "volt" Vector__XXX
 SG_ BattTracCell32_U_Actl : 11|12@0+ (0.001,1) [1|5.093] "volt" Vector__XXX
 SG_ BattTracCell31_U_Actl : 7|12@0+ (0.001,1) [1|5.093] "volt" Vector__XXX

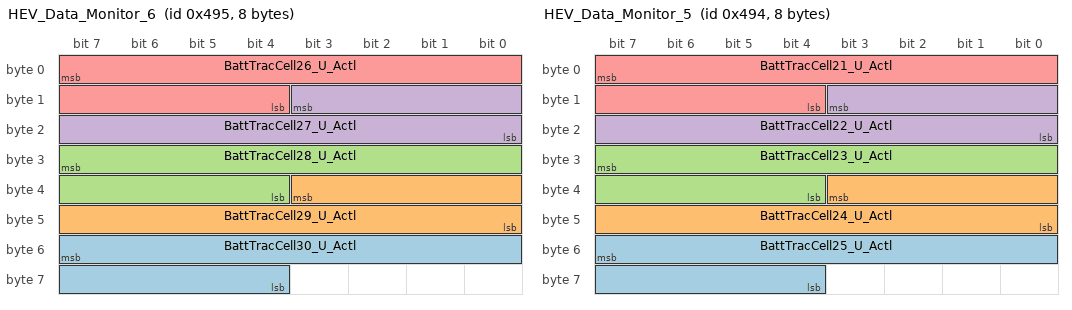
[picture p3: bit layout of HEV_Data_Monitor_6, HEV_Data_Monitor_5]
BO_ 1173 HEV_Data_Monitor_6: 8 GWM
 SG_ BattTracCell30_U_Actl : 55|12@0+ (0.001,1) [1|5.093] "volt" Vector__XXX
 SG_ BattTracCell29_U_Actl : 35|12@0+ (0.001,1) [1|5.093] "volt" Vector__XXX
 SG_ BattTracCell28_U_Actl : 31|12@0+ (0.001,1) [1|5.093] "volt" Vector__XXX
 SG_ BattTracCell27_U_Actl : 11|12@0+ (0.001,1) [1|5.093] "volt" Vector__XXX
 SG_ BattTracCell26_U_Actl : 7|12@0+ (0.001,1) [1|5.093] "volt" Vector__XXX

BO_ 1172 HEV_Data_Monitor_5: 8 GWM
 SG_ BattTracCell25_U_Actl : 55|12@0+ (0.001,1) [1|5.093] "volt" Vector__XXX
 SG_ BattTracCell24_U_Actl : 35|12@0+ (0.001,1) [1|5.093] "volt" Vector__XXX
 SG_ BattTracCell23_U_Actl : 31|12@0+ (0.001,1) [1|5.093] "volt" Vector__XXX
 SG_ BattTracCell22_U_Actl : 11|12@0+ (0.001,1) [1|5.093] "volt" Vector__XXX
 SG_ BattTracCell21_U_Actl : 7|12@0+ (0.001,1) [1|5.093] "volt" Vector__XXX

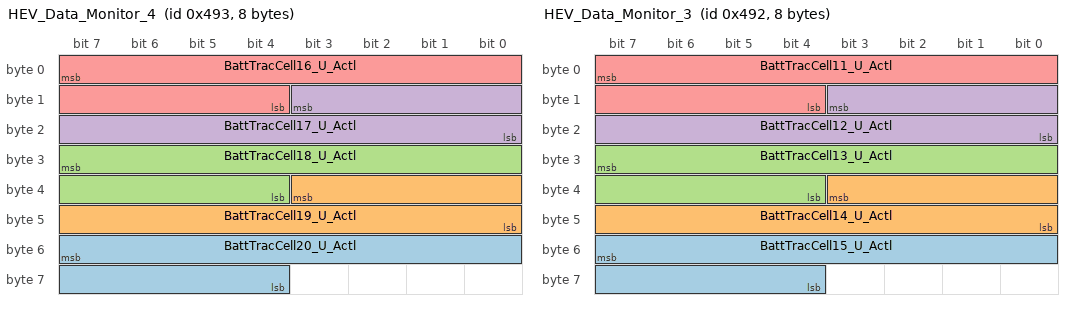
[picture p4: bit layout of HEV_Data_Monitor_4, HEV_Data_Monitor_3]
BO_ 1171 HEV_Data_Monitor_4: 8 GWM
 SG_ BattTracCell20_U_Actl : 55|12@0+ (0.001,1) [1|5.093] "volt" Vector__XXX
 SG_ BattTracCell19_U_Actl : 35|12@0+ (0.001,1) [1|5.093] "volt" Vector__XXX
 SG_ BattTracCell18_U_Actl : 31|12@0+ (0.001,1) [1|5.093] "volt" Vector__XXX
 SG_ BattTracCell17_U_Actl : 11|12@0+ (0.001,1) [1|5.093] "volt" Vector__XXX
 SG_ BattTracCell16_U_Actl : 7|12@0+ (0.001,1) [1|5.093] "volt" Vector__XXX

BO_ 1170 HEV_Data_Monitor_3: 8 GWM
 SG_ BattTracCell15_U_Actl : 55|12@0+ (0.001,1) [1|5.093] "volt" Vector__XXX
 SG_ BattTracCell14_U_Actl : 35|12@0+ (0.001,1) [1|5.093] "volt" Vector__XXX
 SG_ BattTracCell13_U_Actl : 31|12@0+ (0.001,1) [1|5.093] "volt" Vector__XXX
 SG_ BattTracCell12_U_Actl : 11|12@0+ (0.001,1) [1|5.093] "volt" Vector__XXX
 SG_ BattTracCell11_U_Actl : 7|12@0+ (0.001,1) [1|5.093] "volt" Vector__XXX

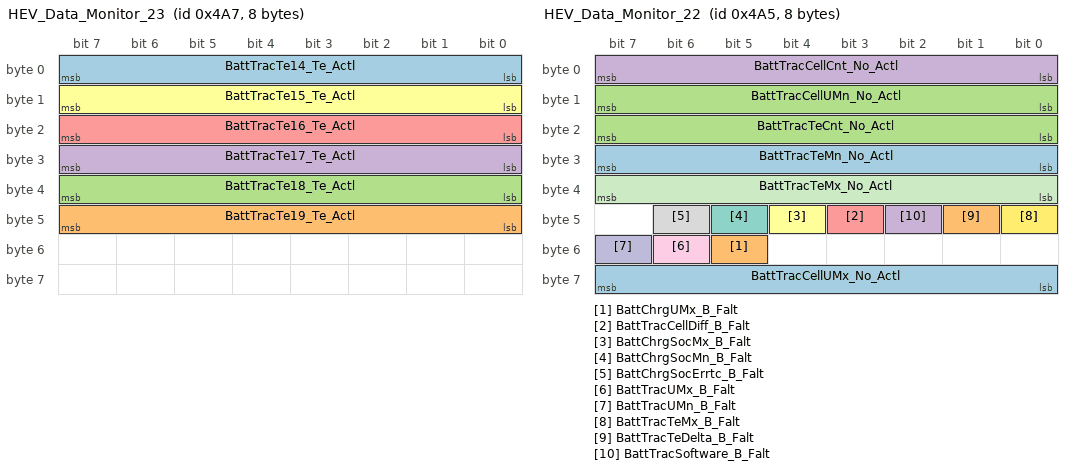
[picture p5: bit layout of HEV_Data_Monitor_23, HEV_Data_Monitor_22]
BO_ 1191 HEV_Data_Monitor_23: 8 GWM
 SG_ BattTracTe14_Te_Actl : 7|8@0+ (1,-50) [-50|203] "degC" Vector__XXX
 SG_ BattTracTe19_Te_Actl : 47|8@0+ (1,-50) [-50|203] "degC" Vector__XXX
 SG_ BattTracTe18_Te_Actl : 39|8@0+ (1,-50) [-50|203] "degC" Vector__XXX
 SG_ BattTracTe17_Te_Actl : 31|8@0+ (1,-50) [-50|203] "degC" Vector__XXX
 SG_ BattTracTe16_Te_Actl : 23|8@0+ (1,-50) [-50|203] "degC" Vector__XXX
 SG_ BattTracTe15_Te_Actl : 15|8@0+ (1,-50) [-50|203] "degC" Vector__XXX

BO_ 1189 HEV_Data_Monitor_22: 8 GWM
 SG_ BattTracCellUMx_No_Actl : 63|8@0+ (1,0) [0|253] "Unitless" Vector__XXX
 SG_ BattChrgUMx_B_Falt : 53|1@0+ (1,0) [0|1] "SED" Vector__XXX
 SG_ BattTracCellUMn_No_Actl : 15|8@0+ (1,0) [0|253] "Unitless" Vector__XXX
 SG_ BattTracCellCnt_No_Actl : 7|8@0+ (1,0) [0|253] "Unitless" Vector__XXX
 SG_ BattTracCellDiff_B_Falt : 43|1@0+ (1,0) [0|1] "SED" Vector__XXX
 SG_ BattChrgSocMx_B_Falt : 44|1@0+ (1,0) [0|1] "SED" Vector__XXX
 SG_ BattChrgSocMn_B_Falt : 45|1@0+ (1,0) [0|1] "SED" Vector__XXX
 SG_ BattChrgSocErrtc_B_Falt : 46|1@0+ (1,0) [0|1] "SED" Vector__XXX
 SG_ BattTracUMx_B_Falt : 54|1@0+ (1,0) [0|1] "SED" Vector__XXX
 SG_ BattTracUMn_B_Falt : 55|1@0+ (1,0) [0|1] "SED" Vector__XXX
 SG_ BattTracTeMx_No_Actl : 39|8@0+ (1,0) [0|253] "Unitless" Vector__XXX
 SG_ BattTracTeMx_B_Falt : 40|1@0+ (1,0) [0|1] "SED" Vector__XXX
 SG_ BattTracTeMn_No_Actl : 31|8@0+ (1,0) [0|253] "Unitless" Vector__XXX
 SG_ BattTracTeDelta_B_Falt : 41|1@0+ (1,0) [0|1] "SED" Vector__XXX
 SG_ BattTracTeCnt_No_Actl : 23|8@0+ (1,0) [0|253] "Unitless" Vector__XXX
 SG_ BattTracSoftware_B_Falt : 42|1@0+ (1,0) [0|1] "SED" Vector__XXX

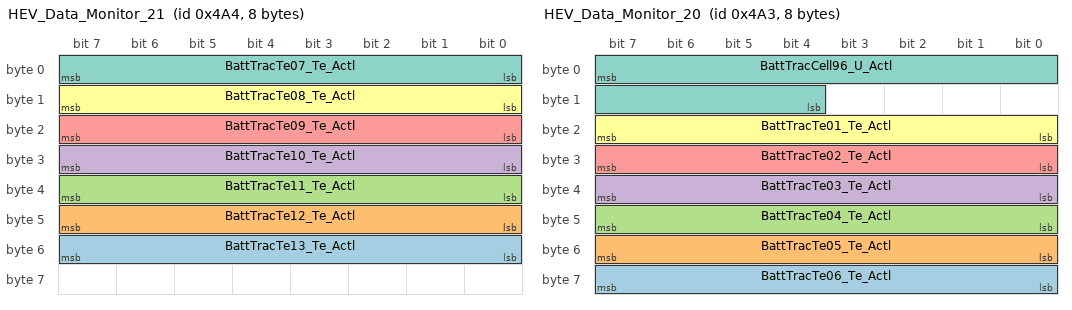
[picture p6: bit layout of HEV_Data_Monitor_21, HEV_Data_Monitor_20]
BO_ 1188 HEV_Data_Monitor_21: 8 GWM
 SG_ BattTracTe13_Te_Actl : 55|8@0+ (1,-50) [-50|203] "degC" Vector__XXX
 SG_ BattTracTe12_Te_Actl : 47|8@0+ (1,-50) [-50|203] "degC" Vector__XXX
 SG_ BattTracTe11_Te_Actl : 39|8@0+ (1,-50) [-50|203] "degC" Vector__XXX
 SG_ BattTracTe10_Te_Actl : 31|8@0+ (1,-50) [-50|203] "degC" Vector__XXX
 SG_ BattTracTe09_Te_Actl : 23|8@0+ (1,-50) [-50|203] "degC" Vector__XXX
 SG_ BattTracTe08_Te_Actl : 15|8@0+ (1,-50) [-50|203] "degC" Vector__XXX
 SG_ BattTracTe07_Te_Actl : 7|8@0+ (1,-50) [-50|203] "degC" Vector__XXX

BO_ 1187 HEV_Data_Monitor_20: 8 GWM
 SG_ BattTracTe06_Te_Actl : 63|8@0+ (1,-50) [-50|203] "degC" Vector__XXX
 SG_ BattTracTe05_Te_Actl : 55|8@0+ (1,-50) [-50|203] "degC" Vector__XXX
 SG_ BattTracTe04_Te_Actl : 47|8@0+ (1,-50) [-50|203] "degC" Vector__XXX
 SG_ BattTracTe03_Te_Actl : 39|8@0+ (1,-50) [-50|203] "degC" Vector__XXX
 SG_ BattTracTe02_Te_Actl : 31|8@0+ (1,-50) [-50|203] "degC" Vector__XXX
 SG_ BattTracTe01_Te_Actl : 23|8@0+ (1,-50) [-50|203] "degC" Vector__XXX
 SG_ BattTracCell96_U_Actl : 7|12@0+ (0.001,1) [1|5.093] "volt" Vector__XXX

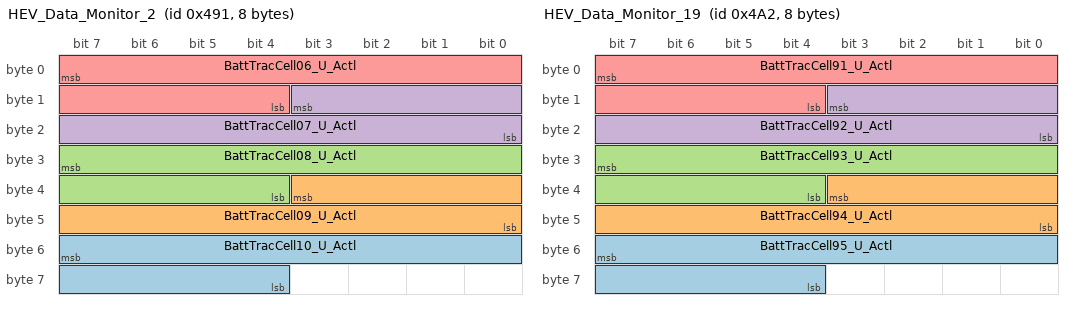
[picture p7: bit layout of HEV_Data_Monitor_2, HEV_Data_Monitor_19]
BO_ 1169 HEV_Data_Monitor_2: 8 GWM
 SG_ BattTracCell10_U_Actl : 55|12@0+ (0.001,1) [1|5.093] "volt" Vector__XXX
 SG_ BattTracCell09_U_Actl : 35|12@0+ (0.001,1) [1|5.093] "volt" Vector__XXX
 SG_ BattTracCell08_U_Actl : 31|12@0+ (0.001,1) [1|5.093] "volt" Vector__XXX
 SG_ BattTracCell07_U_Actl : 11|12@0+ (0.001,1) [1|5.093] "volt" Vector__XXX
 SG_ BattTracCell06_U_Actl : 7|12@0+ (0.001,1) [1|5.093] "volt" Vector__XXX

BO_ 1186 HEV_Data_Monitor_19: 8 GWM
 SG_ BattTracCell95_U_Actl : 55|12@0+ (0.001,1) [1|5.093] "volt" Vector__XXX
 SG_ BattTracCell94_U_Actl : 35|12@0+ (0.001,1) [1|5.093] "volt" Vector__XXX
 SG_ BattTracCell93_U_Actl : 31|12@0+ (0.001,1) [1|5.093] "volt" Vector__XXX
 SG_ BattTracCell92_U_Actl : 11|12@0+ (0.001,1) [1|5.093] "volt" Vector__XXX
 SG_ BattTracCell91_U_Actl : 7|12@0+ (0.001,1) [1|5.093] "volt" Vector__XXX

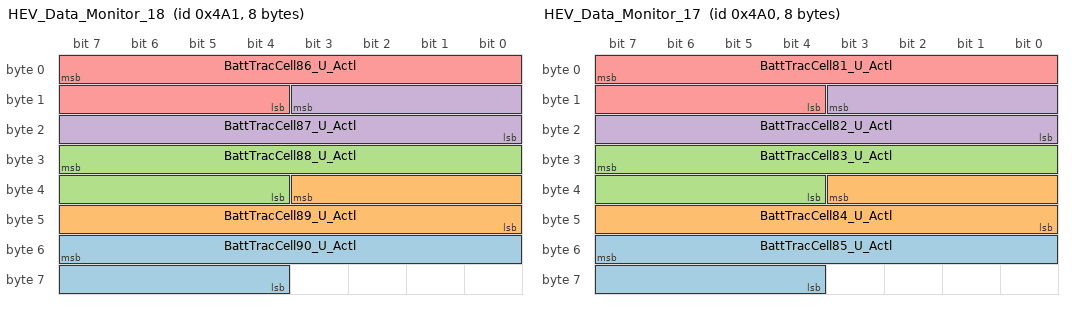
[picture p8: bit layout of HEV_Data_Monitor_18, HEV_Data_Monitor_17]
BO_ 1185 HEV_Data_Monitor_18: 8 GWM
 SG_ BattTracCell90_U_Actl : 55|12@0+ (0.001,1) [1|5.093] "volt" Vector__XXX
 SG_ BattTracCell89_U_Actl : 35|12@0+ (0.001,1) [1|5.093] "volt" Vector__XXX
 SG_ BattTracCell88_U_Actl : 31|12@0+ (0.001,1) [1|5.093] "volt" Vector__XXX
 SG_ BattTracCell87_U_Actl : 11|12@0+ (0.001,1) [1|5.093] "volt" Vector__XXX
 SG_ BattTracCell86_U_Actl : 7|12@0+ (0.001,1) [1|5.093] "volt" Vector__XXX

BO_ 1184 HEV_Data_Monitor_17: 8 GWM
 SG_ BattTracCell85_U_Actl : 55|12@0+ (0.001,1) [1|5.093] "volt" Vector__XXX
 SG_ BattTracCell84_U_Actl : 35|12@0+ (0.001,1) [1|5.093] "volt" Vector__XXX
 SG_ BattTracCell83_U_Actl : 31|12@0+ (0.001,1) [1|5.093] "volt" Vector__XXX
 SG_ BattTracCell82_U_Actl : 11|12@0+ (0.001,1) [1|5.093] "volt" Vector__XXX
 SG_ BattTracCell81_U_Actl : 7|12@0+ (0.001,1) [1|5.093] "volt" Vector__XXX

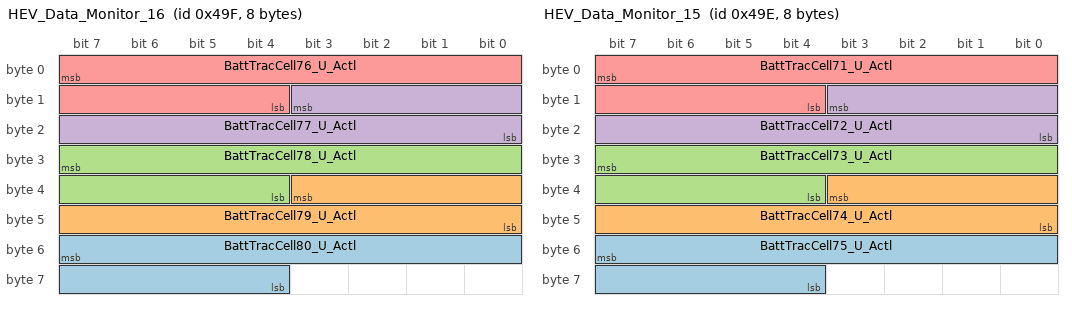
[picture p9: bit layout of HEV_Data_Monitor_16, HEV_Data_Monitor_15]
BO_ 1183 HEV_Data_Monitor_16: 8 GWM
 SG_ BattTracCell80_U_Actl : 55|12@0+ (0.001,1) [1|5.093] "volt" Vector__XXX
 SG_ BattTracCell79_U_Actl : 35|12@0+ (0.001,1) [1|5.093] "volt" Vector__XXX
 SG_ BattTracCell78_U_Actl : 31|12@0+ (0.001,1) [1|5.093] "volt" Vector__XXX
 SG_ BattTracCell77_U_Actl : 11|12@0+ (0.001,1) [1|5.093] "volt" Vector__XXX
 SG_ BattTracCell76_U_Actl : 7|12@0+ (0.001,1) [1|5.093] "volt" Vector__XXX

BO_ 1182 HEV_Data_Monitor_15: 8 GWM
 SG_ BattTracCell75_U_Actl : 55|12@0+ (0.001,1) [1|5.093] "volt" Vector__XXX
 SG_ BattTracCell74_U_Actl : 35|12@0+ (0.001,1) [1|5.093] "volt" Vector__XXX
 SG_ BattTracCell73_U_Actl : 31|12@0+ (0.001,1) [1|5.093] "volt" Vector__XXX
 SG_ BattTracCell72_U_Actl : 11|12@0+ (0.001,1) [1|5.093] "volt" Vector__XXX
 SG_ BattTracCell71_U_Actl : 7|12@0+ (0.001,1) [1|5.093] "volt" Vector__XXX

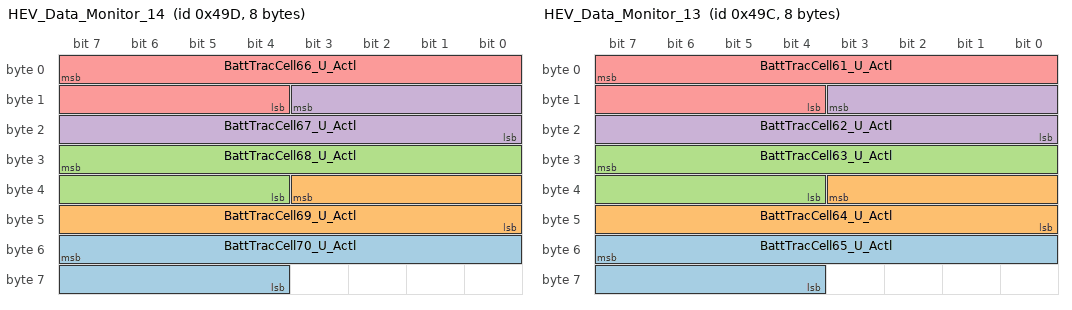
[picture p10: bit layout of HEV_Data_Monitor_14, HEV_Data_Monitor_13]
BO_ 1181 HEV_Data_Monitor_14: 8 GWM
 SG_ BattTracCell70_U_Actl : 55|12@0+ (0.001,1) [1|5.093] "volt" Vector__XXX
 SG_ BattTracCell69_U_Actl : 35|12@0+ (0.001,1) [1|5.093] "volt" Vector__XXX
 SG_ BattTracCell68_U_Actl : 31|12@0+ (0.001,1) [1|5.093] "volt" Vector__XXX
 SG_ BattTracCell67_U_Actl : 11|12@0+ (0.001,1) [1|5.093] "volt" Vector__XXX
 SG_ BattTracCell66_U_Actl : 7|12@0+ (0.001,1) [1|5.093] "volt" Vector__XXX

BO_ 1180 HEV_Data_Monitor_13: 8 GWM
 SG_ BattTracCell65_U_Actl : 55|12@0+ (0.001,1) [1|5.093] "volt" Vector__XXX
 SG_ BattTracCell64_U_Actl : 35|12@0+ (0.001,1) [1|5.093] "volt" Vector__XXX
 SG_ BattTracCell63_U_Actl : 31|12@0+ (0.001,1) [1|5.093] "volt" Vector__XXX
 SG_ BattTracCell62_U_Actl : 11|12@0+ (0.001,1) [1|5.093] "volt" Vector__XXX
 SG_ BattTracCell61_U_Actl : 7|12@0+ (0.001,1) [1|5.093] "volt" Vector__XXX

CM_ "FNV2 HS1 CAN";
CM_ BU_ SOBDMB_AWDC "Secondary OBD Control Module B, All Wheel Drive Control";
CM_ BU_ BCMC_CPDB "CAN Power Distribution Box";
CM_ BU_ BECMB_EPM "EPM (Extended Power Module) ";
CM_ BU_ PACM "PACM (Pedestrian Alert Control Module) or AVAS (Approaching Vehicle Audible System) use in electric vehicles operating in electric mode.";
CM_ BU_ GWM "Gateway Module CGEA1.3(Star Architecture)";
CM_ BU_ BCM "Body Ctrl. Mod, Smart Junction Box, SPDJB";
CM_ BU_ ACCM "Air-Condition Control Module";
CM_ BU_ DCDC_HEV "DC-DC Converter Ctrl. Mod., HEV Hybird Electric";
CM_ BU_ GENERIC "holding pattern ECU for developmental messages";
CM_ BU_ TSTR "Diagnostic Tester";
CM_ SG_ 1465 SOBDMB_AutoSarNMReserved4 "Signal not transmitted on gas and diesel variants.";
CM_ SG_ 1465 SOBDMB_AutoSarNMReserved3 "Signal not transmitted on gas and diesel variants.";
CM_ SG_ 1465 SOBDMB_AutoSarNMReserved2 "Signal not transmitted on gas and diesel variants.";
CM_ SG_ 1465 SOBDMB_AutoSarNMReserved1 "Signal not transmitted on gas and diesel variants.";
CM_ SG_ 1465 SOBDMB_AutoSarNMNodeId "Signal not transmitted on gas and diesel variants.";
CM_ SG_ 1465 SOBDMB_AutoSarNMControl "Signal not transmitted on gas and diesel variants.";
BA_DEF_  "BusType" STRING ;
BA_DEF_ BO_  "FrameRouting" STRING ;
BA_DEF_ BO_  "FrameGatewayNetwork" STRING ;
BA_DEF_ BO_  "NetworkInitialization" ENUM  "No","Yes";
BA_DEF_ BO_  "FrameGatewayId" HEX 0 1407;
BA_DEF_ BO_  "EventRateOfChange" INT 10 10000;
BA_DEF_ BO_  "GenMsgStartDelayTime" INT 0 10000;
BA_DEF_ BO_  "GenMsgNrOfRepetition" INT 0 100;
BA_DEF_ BO_  "GenMsgDelayTime" INT 0 1000;
BA_DEF_ BO_  "GenMsgCycleTime" INT 0 100000;
BA_DEF_ BO_  "GenMsgSendType" ENUM  "FixedPeriodic","Event","EnabledPeriodic","NotUsed","NotUsed","EventPeriodic","NotUsed","NotUsed","NoMsgSendType";
BA_DEF_ SG_  "U_CD764_MY2022_Tx" ENUM  "No","Yes";
BA_DEF_ SG_  "U_U55X_MY2022_Tx" ENUM  "No","Yes";
BA_DEF_ SG_  "U_CD542_MY2021_Tx" ENUM  "No","Yes";
BA_DEF_ SG_  "ECGUsedTxSignal" ENUM  "No","Yes";
BA_DEF_ SG_  "U_T6_MCA_MY2020_Tx" ENUM  "No","Yes";
BA_DEF_ SG_  "U_P702_MY2021_Tx" ENUM  "No","Yes";
BA_DEF_ SG_  "U_CX727_MY2021_Tx" ENUM  "No","Yes";
BA_DEF_ SG_  "U_CD764_MY2022_Rx" ENUM  "No","Yes";
BA_DEF_ SG_  "U_U55X_MY2022_Rx" ENUM  "No","Yes";
BA_DEF_ SG_  "U_CD542_MY2021_Rx" ENUM  "No","Yes";
BA_DEF_ SG_  "ECGUsedRxSignal" ENUM  "No","Yes";
BA_DEF_ SG_  "U_T6_MCA_MY2020_Rx" ENUM  "No","Yes";
BA_DEF_ SG_  "U_P702_MY2021_Rx" ENUM  "No","Yes";
BA_DEF_ SG_  "U_CX727_MY2021_Rx" ENUM  "No","Yes";
BA_DEF_ SG_  "GenSigStartValue" HEX 0 268435455;
BA_DEF_ SG_  "MetaData" ENUM  "No","Yes";
BA_DEF_ SG_  "ContentDependant" ENUM  "No","Yes";
BA_DEF_ SG_  "GenSigStartValueInteger" INT 0 1000000000;
BA_DEF_ SG_  "UsedOnPgmDBC" ENUM  "No","Yes";
BA_DEF_ SG_  "WakeupSignal" ENUM  "No","Yes";
BA_DEF_ SG_  "GenSigInactiveValue" INT 0 100000;
BA_DEF_ SG_  "GenSigSendType" ENUM  "Cyclic","OnWrite","vector_leerstring","OnChange","vector_leerstring","IfActive","vector_leerstring","NoSigSendType";
BA_DEF_ BO_  "OvtpPushApplication" ENUM  "FALSE","TRUE";
BA_DEF_ BO_  "SCP_FreshnessValueLength" INT 0 512;
BA_DEF_ BO_  "SCP_FreshnessValueTxLength" INT 0 512;
BA_DEF_ BO_  "SCP_AuthInfoTxLength" INT 0 512;
BA_DEF_ BO_  "GenMsgRoutingTimeoutTime" INT 0 5000;
BA_DEF_ BO_  "MessageGateway" ENUM  "No","Yes";
BA_DEF_ BO_  "NmAsrMessage" ENUM  "No","Yes";
BA_DEF_ BO_  "TpApplType" STRING ;
BA_DEF_ BO_  "DiagState" ENUM  "No","Yes";
BA_DEF_ BO_  "TpTxIndex" INT 0 536870911;
BA_DEF_ BO_  "DiagRequest" ENUM  "No","Yes";
BA_DEF_ BO_  "DiagResponse" ENUM  "No","Yes";
BA_DEF_ BO_  "GenMsgILSupport" ENUM  "No","Yes";
BA_DEF_ BU_  "OvtpOperationMode" ENUM  "SERVER","CLIENT";
BA_DEF_ BU_  "OvtpEcuAddress" INT 0 1022;
BA_DEF_ BU_  "ILUsed" ENUM  "No","Yes";
BA_DEF_ BU_  "Terminator" ENUM  "No","Yes";
BA_DEF_ BU_  "NodeWakeUpTime" INT 0 10000;
BA_DEF_ BU_  "NodeStartUpTime" INT 0 10000;
BA_DEF_ BU_  "NmAsrNodeIdentifier" HEX 0 255;
BA_DEF_ BU_  "NmAsrNode" ENUM  "No","Yes";
BA_DEF_ BU_  "PowerType" ENUM  "Switched","Latched","Sleep","vector_leerstring","vector_leerstring";
BA_DEF_ BU_  "DiagNode" ENUM  "GGDS","GDS","NONE";
BA_DEF_ BU_  "EOL_SB_Flash" ENUM  "GGDS","GDS","NONE","vector_leerstring";
BA_DEF_ BU_  "NmNode" ENUM  "No","Yes";
BA_DEF_ BU_  "NmStationAddress" INT 0 255;
BA_DEF_ BU_  "NosPackage" ENUM  "None","I3_1","I3_2","1.0.1","RP","EuCD","Volcano","I3_3","FNOS_Autosar";
BA_DEF_ BU_  "LIN_Master" ENUM  "No","Yes";
BA_DEF_ BU_  "PackageID" STRING ;
BA_DEF_ BU_  "GatewayECU" ENUM  "No","Yes";
BA_DEF_  "NetworkSpeed" ENUM  "500kBits/s","125kBit/s";
BA_DEF_  "VersionNumber" INT 0 10000;
BA_DEF_  "StarNetworkGwType" ENUM  "0=NotDefined","1=HS1","2=HS2","3=HS3","4=HS4","5=HS5","6=MS1","7=HS6","8=HS7","9=MS2","10=FD1","11=FD2","12=FD3","13=FD4","14=FD5","15=FD6","16=FD7","17=FD8";
BA_DEF_  "CMDB_Version" STRING ;
BA_DEF_  "NmType" STRING ;
BA_DEF_  "NmAsrMessageCount" INT 128 256;
BA_DEF_  "NmAsrBaseAddress" HEX 1280 1408;
BA_DEF_  "DBName" STRING ;
BA_DEF_  "VersionDay" INT 1 31;
BA_DEF_  "Manufacturer" STRING ;
BA_DEF_  "VersionMonth" INT 1 12;
BA_DEF_  "VersionYear" INT 2000 3000;
BA_DEF_  "NmBaseAddress" HEX 1280 1280;
BA_DEF_  "NmMessageCount" INT 0 128;
BA_DEF_DEF_  "BusType" "";
BA_DEF_DEF_  "FrameRouting" "";
BA_DEF_DEF_  "FrameGatewayNetwork" "NONE";
BA_DEF_DEF_  "NetworkInitialization" "Yes";
BA_DEF_DEF_  "FrameGatewayId" 0;
BA_DEF_DEF_  "EventRateOfChange" 10000;
BA_DEF_DEF_  "GenMsgStartDelayTime" 0;
BA_DEF_DEF_  "GenMsgNrOfRepetition" 1;
BA_DEF_DEF_  "GenMsgDelayTime" 20;
BA_DEF_DEF_  "GenMsgCycleTime" 0;
BA_DEF_DEF_  "GenMsgSendType" "NoMsgSendType";
BA_DEF_DEF_  "U_CD764_MY2022_Tx" "No";
BA_DEF_DEF_  "U_U55X_MY2022_Tx" "No";
BA_DEF_DEF_  "U_CD542_MY2021_Tx" "No";
BA_DEF_DEF_  "ECGUsedTxSignal" "No";
BA_DEF_DEF_  "U_T6_MCA_MY2020_Tx" "No";
BA_DEF_DEF_  "U_P702_MY2021_Tx" "No";
BA_DEF_DEF_  "U_CX727_MY2021_Tx" "No";
BA_DEF_DEF_  "U_CD764_MY2022_Rx" "No";
BA_DEF_DEF_  "U_U55X_MY2022_Rx" "No";
BA_DEF_DEF_  "U_CD542_MY2021_Rx" "No";
BA_DEF_DEF_  "ECGUsedRxSignal" "No";
BA_DEF_DEF_  "U_T6_MCA_MY2020_Rx" "No";
BA_DEF_DEF_  "U_P702_MY2021_Rx" "No";
BA_DEF_DEF_  "U_CX727_MY2021_Rx" "No";
BA_DEF_DEF_  "GenSigStartValue" 0;
BA_DEF_DEF_  "MetaData" "No";
BA_DEF_DEF_  "ContentDependant" "No";
BA_DEF_DEF_  "GenSigStartValueInteger" 0;
BA_DEF_DEF_  "UsedOnPgmDBC" "Yes";
BA_DEF_DEF_  "WakeupSignal" "No";
BA_DEF_DEF_  "GenSigInactiveValue" 0;
BA_DEF_DEF_  "GenSigSendType" "NoSigSendType";
BA_DEF_DEF_  "OvtpPushApplication" "FALSE";
BA_DEF_DEF_  "SCP_FreshnessValueLength" 64;
BA_DEF_DEF_  "SCP_FreshnessValueTxLength" 11;
BA_DEF_DEF_  "SCP_AuthInfoTxLength" 53;
BA_DEF_DEF_  "GenMsgRoutingTimeoutTime" 0;
BA_DEF_DEF_  "MessageGateway" "No";
BA_DEF_DEF_  "NmAsrMessage" "No";
BA_DEF_DEF_  "TpApplType" "";
BA_DEF_DEF_  "DiagState" "No";
BA_DEF_DEF_  "TpTxIndex" 0;
BA_DEF_DEF_  "DiagRequest" "No";
BA_DEF_DEF_  "DiagResponse" "No";
BA_DEF_DEF_  "GenMsgILSupport" "Yes";
BA_DEF_DEF_  "OvtpOperationMode" "SERVER";
BA_DEF_DEF_  "OvtpEcuAddress" 0;
BA_DEF_DEF_  "ILUsed" "Yes";
BA_DEF_DEF_  "Terminator" "No";
BA_DEF_DEF_  "NodeWakeUpTime" 100;
BA_DEF_DEF_  "NodeStartUpTime" 250;
BA_DEF_DEF_  "NmAsrNodeIdentifier" 128;
BA_DEF_DEF_  "NmAsrNode" "No";
BA_DEF_DEF_  "PowerType" "Switched";
BA_DEF_DEF_  "DiagNode" "GGDS";
BA_DEF_DEF_  "EOL_SB_Flash" "GGDS";
BA_DEF_DEF_  "NmNode" "No";
BA_DEF_DEF_  "NmStationAddress" 0;
BA_DEF_DEF_  "NosPackage" "I3_3";
BA_DEF_DEF_  "LIN_Master" "No";
BA_DEF_DEF_  "PackageID" "08.05.00.00.71.xx.xx.rr.00.00";
BA_DEF_DEF_  "GatewayECU" "No";
BA_DEF_DEF_  "NetworkSpeed" "500kBits/s";
BA_DEF_DEF_  "VersionNumber" 1;
BA_DEF_DEF_  "StarNetworkGwType" "0=NotDefined";
BA_DEF_DEF_  "CMDB_Version" "v11.01";
BA_DEF_DEF_  "NmType" "Ford-OSEK";
BA_DEF_DEF_  "NmAsrMessageCount" 128;
BA_DEF_DEF_  "NmAsrBaseAddress" 1408;
BA_DEF_DEF_  "DBName" "";
BA_DEF_DEF_  "VersionDay" 1;
BA_DEF_DEF_  "Manufacturer" "Ford";
BA_DEF_DEF_  "VersionMonth" 1;
BA_DEF_DEF_  "VersionYear" 2011;
BA_DEF_DEF_  "NmBaseAddress" 1280;
BA_DEF_DEF_  "NmMessageCount" 128;
BA_ "BusType" "CAN";
BA_ "VersionYear" 2020;
BA_ "VersionMonth" 10;
BA_ "VersionDay" 30;
BA_ "CMDB_Version" "FNV2_v20.12";
BA_ "StarNetworkGwType" 1;
BA_ "VersionNumber" 12;
BA_ "DBName" "HS1_CAN";
BA_ "NmStationAddress" BU_ SOBDMB_AWDC 57;
BA_ "NmAsrNode" BU_ SOBDMB_AWDC 1;
BA_ "NmAsrNodeIdentifier" BU_ SOBDMB_AWDC 150;
BA_ "OvtpEcuAddress" BU_ SOBDMB_AWDC 34;
BA_ "NmStationAddress" BU_ BCMC_CPDB 80;
BA_ "PowerType" BU_ BCMC_CPDB 2;
BA_ "NmAsrNode" BU_ BCMC_CPDB 1;
BA_ "NmAsrNodeIdentifier" BU_ BCMC_CPDB 208;
BA_ "NodeStartUpTime" BU_ BCMC_CPDB 500;
BA_ "NodeWakeUpTime" BU_ BCMC_CPDB 500;
BA_ "OvtpEcuAddress" BU_ BCMC_CPDB 66;
BA_ "NmStationAddress" BU_ BECMB_EPM 50;
BA_ "PowerType" BU_ BECMB_EPM 2;
BA_ "NmAsrNode" BU_ BECMB_EPM 1;
BA_ "NmAsrNodeIdentifier" BU_ BECMB_EPM 178;
BA_ "NodeWakeUpTime" BU_ BECMB_EPM 70;
BA_ "OvtpEcuAddress" BU_ BECMB_EPM 81;
BA_ "NmStationAddress" BU_ PACM 141;
BA_ "OvtpEcuAddress" BU_ PACM 62;
BA_ "NmStationAddress" BU_ GWM 30;
BA_ "PowerType" BU_ GWM 2;
BA_ "NmAsrNode" BU_ GWM 1;
BA_ "NmAsrNodeIdentifier" BU_ GWM 158;
BA_ "NodeStartUpTime" BU_ GWM 100;
BA_ "Terminator" BU_ GWM 1;
BA_ "OvtpEcuAddress" BU_ GWM 216;
BA_ "OvtpOperationMode" BU_ GWM 1;
BA_ "GatewayECU" BU_ GWM 1;
BA_ "NosPackage" BU_ GWM 4;
BA_ "NmStationAddress" BU_ BCM 1;
BA_ "PowerType" BU_ BCM 2;
BA_ "NmAsrNode" BU_ BCM 1;
BA_ "NmAsrNodeIdentifier" BU_ BCM 129;
BA_ "NodeStartUpTime" BU_ BCM 1000;
BA_ "OvtpEcuAddress" BU_ BCM 82;
BA_ "PackageID" BU_ BCM "08.06.00.00.81";
BA_ "LIN_Master" BU_ BCM 1;
BA_ "NmStationAddress" BU_ ACCM 101;
BA_ "OvtpEcuAddress" BU_ ACCM 148;
BA_ "NmStationAddress" BU_ DCDC_HEV 56;
BA_ "OvtpEcuAddress" BU_ DCDC_HEV 204;
BA_ "TpTxIndex" BO_ 2612037848 464554200;
BA_ "OvtpPushApplication" BO_ 2612037848 1;
BA_ "GenMsgSendType" BO_ 2612037848 1;
BA_ "GenMsgDelayTime" BO_ 2612037848 0;
BA_ "TpTxIndex" BO_ 2610989272 463505624;
BA_ "GenMsgSendType" BO_ 2610989272 1;
BA_ "GenMsgDelayTime" BO_ 2610989272 0;
BA_ "TpTxIndex" BO_ 2609940696 462457048;
BA_ "GenMsgSendType" BO_ 2609940696 1;
BA_ "GenMsgDelayTime" BO_ 2609940696 0;
BA_ "GenMsgILSupport" BO_ 2023 0;
BA_ "DiagRequest" BO_ 2023 1;
BA_ "GenMsgSendType" BO_ 2023 1;
BA_ "GenMsgDelayTime" BO_ 2023 0;
BA_ "NetworkInitialization" BO_ 2023 0;
BA_ "GenMsgSendType" BO_ 1167 0;
BA_ "GenMsgCycleTime" BO_ 1167 1000;
BA_ "GenMsgSendType" BO_ 1199 0;
BA_ "GenMsgCycleTime" BO_ 1199 1000;
BA_ "GenMsgILSupport" BO_ 1705 0;
BA_ "TpApplType" BO_ 1705 "DiagUUDTResponse";
BA_ "GenMsgSendType" BO_ 1705 1;
BA_ "GenMsgDelayTime" BO_ 1705 0;
BA_ "NetworkInitialization" BO_ 1705 0;
BA_ "GenMsgILSupport" BO_ 1704 0;
BA_ "TpApplType" BO_ 1704 "DiagUUDTResponse";
BA_ "GenMsgSendType" BO_ 1704 1;
BA_ "GenMsgDelayTime" BO_ 1704 0;
BA_ "NetworkInitialization" BO_ 1704 0;
BA_ "TpTxIndex" BO_ 2612224034 464554200;
BA_ "OvtpPushApplication" BO_ 2612224034 1;
BA_ "GenMsgSendType" BO_ 2612224034 1;
BA_ "GenMsgDelayTime" BO_ 2612224034 0;
BA_ "TpTxIndex" BO_ 2611175458 463505624;
BA_ "GenMsgSendType" BO_ 2611175458 1;
BA_ "GenMsgDelayTime" BO_ 2611175458 0;
BA_ "TpTxIndex" BO_ 2610126882 462457048;
BA_ "GenMsgSendType" BO_ 2610126882 1;
BA_ "GenMsgDelayTime" BO_ 2610126882 0;
BA_ "GenMsgILSupport" BO_ 2031 0;
BA_ "DiagResponse" BO_ 2031 1;
BA_ "GenMsgSendType" BO_ 2031 1;
BA_ "GenMsgDelayTime" BO_ 2031 0;
BA_ "NetworkInitialization" BO_ 2031 0;
BA_ "GenMsgILSupport" BO_ 1465 0;
BA_ "NmAsrMessage" BO_ 1465 1;
BA_ "GenMsgSendType" BO_ 1465 0;
BA_ "GenMsgCycleTime" BO_ 1465 1000;
BA_ "NetworkInitialization" BO_ 1465 0;
BA_ "FrameGatewayId" BO_ 1176 1176;
BA_ "FrameRouting" BO_ 1176 "HS5_CAN,0x498";
BA_ "FrameGatewayNetwork" BO_ 1176 "HS5_CAN";
BA_ "FrameGatewayId" BO_ 1175 1175;
BA_ "FrameRouting" BO_ 1175 "HS5_CAN,0x497";
BA_ "FrameGatewayNetwork" BO_ 1175 "HS5_CAN";
BA_ "FrameGatewayId" BO_ 1174 1174;
BA_ "FrameRouting" BO_ 1174 "HS5_CAN,0x496";
BA_ "FrameGatewayNetwork" BO_ 1174 "HS5_CAN";
BA_ "FrameGatewayId" BO_ 1173 1173;
BA_ "FrameRouting" BO_ 1173 "HS5_CAN,0x495";
BA_ "FrameGatewayNetwork" BO_ 1173 "HS5_CAN";
BA_ "FrameGatewayId" BO_ 1172 1172;
BA_ "FrameRouting" BO_ 1172 "HS5_CAN,0x494";
BA_ "FrameGatewayNetwork" BO_ 1172 "HS5_CAN";
BA_ "FrameGatewayId" BO_ 1171 1171;
BA_ "FrameRouting" BO_ 1171 "HS5_CAN,0x493";
BA_ "FrameGatewayNetwork" BO_ 1171 "HS5_CAN";
BA_ "FrameGatewayId" BO_ 1170 1170;
BA_ "FrameRouting" BO_ 1170 "HS5_CAN,0x492";
BA_ "FrameGatewayNetwork" BO_ 1170 "HS5_CAN";
BA_ "FrameGatewayId" BO_ 1191 1191;
BA_ "FrameRouting" BO_ 1191 "HS5_CAN,0x4A7";
BA_ "FrameGatewayNetwork" BO_ 1191 "HS5_CAN";
BA_ "FrameGatewayId" BO_ 1189 1189;
BA_ "FrameRouting" BO_ 1189 "HS5_CAN,0x4A5";
BA_ "FrameGatewayNetwork" BO_ 1189 "HS5_CAN";
BA_ "FrameGatewayId" BO_ 1188 1188;
BA_ "FrameRouting" BO_ 1188 "HS5_CAN,0x4A4";
BA_ "FrameGatewayNetwork" BO_ 1188 "HS5_CAN";
BA_ "FrameGatewayId" BO_ 1187 1187;
BA_ "FrameRouting" BO_ 1187 "HS5_CAN,0x4A3";
BA_ "FrameGatewayNetwork" BO_ 1187 "HS5_CAN";
BA_ "FrameGatewayId" BO_ 1169 1169;
BA_ "FrameRouting" BO_ 1169 "HS5_CAN,0x491";
BA_ "FrameGatewayNetwork" BO_ 1169 "HS5_CAN";
BA_ "FrameGatewayId" BO_ 1186 1186;
BA_ "FrameRouting" BO_ 1186 "HS5_CAN,0x4A2";
BA_ "FrameGatewayNetwork" BO_ 1186 "HS5_CAN";
BA_ "FrameGatewayId" BO_ 1185 1185;
BA_ "FrameRouting" BO_ 1185 "HS5_CAN,0x4A1";
BA_ "FrameGatewayNetwork" BO_ 1185 "HS5_CAN";
BA_ "FrameGatewayId" BO_ 1184 1184;
BA_ "FrameRouting" BO_ 1184 "HS5_CAN,0x4A0";
BA_ "FrameGatewayNetwork" BO_ 1184 "HS5_CAN";
BA_ "FrameGatewayId" BO_ 1183 1183;
BA_ "FrameRouting" BO_ 1183 "HS5_CAN,0x49F";
BA_ "FrameGatewayNetwork" BO_ 1183 "HS5_CAN";
BA_ "FrameRouting" BO_ 1182 "HS5_CAN,0x49E";
BA_ "FrameGatewayId" BO_ 1182 1182;
BA_ "FrameGatewayNetwork" BO_ 1182 "HS5_CAN";
BA_ "FrameGatewayId" BO_ 1181 1181;
BA_ "FrameRouting" BO_ 1181 "HS5_CAN,0x49D";
BA_ "FrameGatewayNetwork" BO_ 1181 "HS5_CAN";
BA_ "FrameGatewayId" BO_ 1180 1180;
BA_ "FrameRouting" BO_ 1180 "HS5_CAN,0x49C";
BA_ "FrameGatewayNetwork" BO_ 1180 "HS5_CAN";
BA_ "GenSigSendType" SG_ 2612037848 PARSEDPushFcGWMECGtoSOBDMB 3;
BA_ "ECGUsedTxSignal" SG_ 2612037848 PARSEDPushFcGWMECGtoSOBDMB 1;
BA_ "GenSigSendType" SG_ 2610989272 PARSEDPhysGWM_ECGtoSOBDMB 3;
BA_ "ECGUsedTxSignal" SG_ 2610989272 PARSEDPhysGWM_ECGtoSOBDMB 1;
BA_ "GenSigSendType" SG_ 2609940696 OTAPhysGWM_ECGtoSOBDMB 3;
BA_ "ECGUsedTxSignal" SG_ 2609940696 OTAPhysGWM_ECGtoSOBDMB 1;
BA_ "GenSigSendType" SG_ 2023 TesterPhysicalReqSOBDMB 3;
BA_ "GenSigStartValue" SG_ 1167 PrplAxlScnd_Tq_ActlMntr 32768;
BA_ "ECGUsedRxSignal" SG_ 1167 PrplAxlScnd_Tq_ActlMntr 1;
BA_ "U_CD542_MY2021_Rx" SG_ 1167 PrplAxlScnd_Tq_ActlMntr 1;
BA_ "U_CD764_MY2022_Rx" SG_ 1167 PrplAxlScnd_Tq_ActlMntr 1;
BA_ "ECGUsedRxSignal" SG_ 1167 Inv4TeAlrm_B_ActlMntr 1;
BA_ "U_CD542_MY2021_Rx" SG_ 1167 Inv4TeAlrm_B_ActlMntr 1;
BA_ "U_CD764_MY2022_Rx" SG_ 1167 Inv4TeAlrm_B_ActlMntr 1;
BA_ "ECGUsedRxSignal" SG_ 1167 Inv4Ain_U_ActlMntr 1;
BA_ "U_CD542_MY2021_Rx" SG_ 1167 Inv4Ain_U_ActlMntr 1;
BA_ "U_CD764_MY2022_Rx" SG_ 1167 Inv4Ain_U_ActlMntr 1;
BA_ "GenSigStartValue" SG_ 1167 Inv4Ain_I_ActlMntr 32766;
BA_ "ECGUsedRxSignal" SG_ 1167 Inv4Ain_I_ActlMntr 1;
BA_ "U_CD542_MY2021_Rx" SG_ 1167 Inv4Ain_I_ActlMntr 1;
BA_ "U_CD764_MY2022_Rx" SG_ 1167 Inv4Ain_I_ActlMntr 1;
BA_ "GenSigStartValue" SG_ 1167 Inv4_Te_ActlMntr 254;
BA_ "ECGUsedRxSignal" SG_ 1167 Inv4_Te_ActlMntr 1;
BA_ "U_CD542_MY2021_Rx" SG_ 1167 Inv4_Te_ActlMntr 1;
BA_ "U_CD764_MY2022_Rx" SG_ 1167 Inv4_Te_ActlMntr 1;
BA_ "ECGUsedRxSignal" SG_ 1199 Mtr4TeAlrm_B_ActlMntr 1;
BA_ "U_CD542_MY2021_Rx" SG_ 1199 Mtr4TeAlrm_B_ActlMntr 1;
BA_ "U_CD764_MY2022_Rx" SG_ 1199 Mtr4TeAlrm_B_ActlMntr 1;
BA_ "GenSigStartValue" SG_ 1199 Mtr4Aout_W_ActlMntr 1023;
BA_ "ECGUsedRxSignal" SG_ 1199 Mtr4Aout_W_ActlMntr 1;
BA_ "U_CD542_MY2021_Rx" SG_ 1199 Mtr4Aout_W_ActlMntr 1;
BA_ "U_CD764_MY2022_Rx" SG_ 1199 Mtr4Aout_W_ActlMntr 1;
BA_ "GenSigStartValue" SG_ 1199 Mtr4Aout_Tq_ActlMntr 2047;
BA_ "ECGUsedRxSignal" SG_ 1199 Mtr4Aout_Tq_ActlMntr 1;
BA_ "U_CD542_MY2021_Rx" SG_ 1199 Mtr4Aout_Tq_ActlMntr 1;
BA_ "U_CD764_MY2022_Rx" SG_ 1199 Mtr4Aout_Tq_ActlMntr 1;
BA_ "GenSigStartValue" SG_ 1199 Mtr4_Te_ActlMntr 254;
BA_ "ECGUsedRxSignal" SG_ 1199 Mtr4_Te_ActlMntr 1;
BA_ "U_CD542_MY2021_Rx" SG_ 1199 Mtr4_Te_ActlMntr 1;
BA_ "U_CD764_MY2022_Rx" SG_ 1199 Mtr4_Te_ActlMntr 1;
BA_ "ECGUsedRxSignal" SG_ 1199 Mtr4_D_StatMntr 1;
BA_ "U_CD542_MY2021_Rx" SG_ 1199 Mtr4_D_StatMntr 1;
BA_ "U_CD764_MY2022_Rx" SG_ 1199 Mtr4_D_StatMntr 1;
BA_ "GenSigSendType" SG_ 1705 UUDTSOBDMBResponse2 3;
BA_ "GenSigSendType" SG_ 1704 UUDTSOBDMBResponse1 3;
BA_ "GenSigSendType" SG_ 2612224034 PARSEDPushSOBDMBtoGWM_ECG 3;
BA_ "ECGUsedRxSignal" SG_ 2612224034 PARSEDPushSOBDMBtoGWM_ECG 1;
BA_ "GenSigSendType" SG_ 2611175458 PARSEDPhysSOBDMBtoGWM_ECG 3;
BA_ "ECGUsedRxSignal" SG_ 2611175458 PARSEDPhysSOBDMBtoGWM_ECG 1;
BA_ "GenSigSendType" SG_ 2610126882 OTAPhysSOBDMBtoGWM_ECG 3;
BA_ "ECGUsedRxSignal" SG_ 2610126882 OTAPhysSOBDMBtoGWM_ECG 1;
BA_ "GenSigSendType" SG_ 2031 TesterPhysicalResSOBDMB 3;
BA_ "GenSigStartValueInteger" SG_ 1465 SOBDMB_GWOnBoardTester 255;
BA_ "ContentDependant" SG_ 1465 SOBDMB_GWOnBoardTester 1;
BA_ "GenSigStartValue" SG_ 1465 SOBDMB_GWOnBoardTester 255;
BA_ "GenSigStartValueInteger" SG_ 1465 SOBDMB_GWNMProxy 255;
BA_ "ContentDependant" SG_ 1465 SOBDMB_GWNMProxy 1;
BA_ "GenSigStartValue" SG_ 1465 SOBDMB_GWNMProxy 255;
BA_ "GenSigStartValueInteger" SG_ 1465 SOBDMB_AutoSarNMReserved4 255;
BA_ "ContentDependant" SG_ 1465 SOBDMB_AutoSarNMReserved4 1;
BA_ "GenSigStartValue" SG_ 1465 SOBDMB_AutoSarNMReserved4 255;
BA_ "GenSigStartValueInteger" SG_ 1465 SOBDMB_AutoSarNMReserved3 255;
BA_ "ContentDependant" SG_ 1465 SOBDMB_AutoSarNMReserved3 1;
BA_ "GenSigStartValue" SG_ 1465 SOBDMB_AutoSarNMReserved3 255;
BA_ "GenSigStartValueInteger" SG_ 1465 SOBDMB_AutoSarNMReserved2 255;
BA_ "ContentDependant" SG_ 1465 SOBDMB_AutoSarNMReserved2 1;
BA_ "GenSigStartValue" SG_ 1465 SOBDMB_AutoSarNMReserved2 255;
BA_ "GenSigStartValueInteger" SG_ 1465 SOBDMB_AutoSarNMReserved1 255;
BA_ "ContentDependant" SG_ 1465 SOBDMB_AutoSarNMReserved1 1;
BA_ "GenSigStartValue" SG_ 1465 SOBDMB_AutoSarNMReserved1 255;
BA_ "GenSigStartValueInteger" SG_ 1465 SOBDMB_AutoSarNMNodeId 185;
BA_ "ContentDependant" SG_ 1465 SOBDMB_AutoSarNMNodeId 1;
BA_ "GenSigStartValue" SG_ 1465 SOBDMB_AutoSarNMNodeId 185;
BA_ "ContentDependant" SG_ 1465 SOBDMB_AutoSarNMControl 1;
BA_ "U_CD542_MY2021_Tx" SG_ 1176 BattTracCell45_U_Actl 1;
BA_ "U_CX727_MY2021_Tx" SG_ 1176 BattTracCell45_U_Actl 1;
BA_ "U_U55X_MY2022_Rx" SG_ 1176 BattTracCell45_U_Actl 1;
BA_ "U_CD542_MY2021_Rx" SG_ 1176 BattTracCell45_U_Actl 1;
BA_ "ECGUsedRxSignal" SG_ 1176 BattTracCell45_U_Actl 1;
BA_ "GenSigStartValue" SG_ 1176 BattTracCell45_U_Actl 4094;
BA_ "GenSigStartValueInteger" SG_ 1176 BattTracCell45_U_Actl 4094;
BA_ "U_CD542_MY2021_Tx" SG_ 1176 BattTracCell44_U_Actl 1;
BA_ "U_CX727_MY2021_Tx" SG_ 1176 BattTracCell44_U_Actl 1;
BA_ "U_U55X_MY2022_Rx" SG_ 1176 BattTracCell44_U_Actl 1;
BA_ "U_CD542_MY2021_Rx" SG_ 1176 BattTracCell44_U_Actl 1;
BA_ "ECGUsedRxSignal" SG_ 1176 BattTracCell44_U_Actl 1;
BA_ "GenSigStartValue" SG_ 1176 BattTracCell44_U_Actl 4094;
BA_ "GenSigStartValueInteger" SG_ 1176 BattTracCell44_U_Actl 4094;
BA_ "U_CD542_MY2021_Tx" SG_ 1176 BattTracCell43_U_Actl 1;
BA_ "U_CX727_MY2021_Tx" SG_ 1176 BattTracCell43_U_Actl 1;
BA_ "U_U55X_MY2022_Rx" SG_ 1176 BattTracCell43_U_Actl 1;
BA_ "U_CD542_MY2021_Rx" SG_ 1176 BattTracCell43_U_Actl 1;
BA_ "ECGUsedRxSignal" SG_ 1176 BattTracCell43_U_Actl 1;
BA_ "GenSigStartValue" SG_ 1176 BattTracCell43_U_Actl 4094;
BA_ "GenSigStartValueInteger" SG_ 1176 BattTracCell43_U_Actl 4094;
BA_ "U_CD542_MY2021_Tx" SG_ 1176 BattTracCell42_U_Actl 1;
BA_ "U_CX727_MY2021_Tx" SG_ 1176 BattTracCell42_U_Actl 1;
BA_ "U_U55X_MY2022_Rx" SG_ 1176 BattTracCell42_U_Actl 1;
BA_ "U_CD542_MY2021_Rx" SG_ 1176 BattTracCell42_U_Actl 1;
BA_ "ECGUsedRxSignal" SG_ 1176 BattTracCell42_U_Actl 1;
BA_ "GenSigStartValue" SG_ 1176 BattTracCell42_U_Actl 4094;
BA_ "GenSigStartValueInteger" SG_ 1176 BattTracCell42_U_Actl 4094;
BA_ "U_CD542_MY2021_Tx" SG_ 1176 BattTracCell41_U_Actl 1;
BA_ "U_CX727_MY2021_Tx" SG_ 1176 BattTracCell41_U_Actl 1;
BA_ "U_U55X_MY2022_Rx" SG_ 1176 BattTracCell41_U_Actl 1;
BA_ "U_CD542_MY2021_Rx" SG_ 1176 BattTracCell41_U_Actl 1;
BA_ "ECGUsedRxSignal" SG_ 1176 BattTracCell41_U_Actl 1;
BA_ "GenSigStartValue" SG_ 1176 BattTracCell41_U_Actl 4094;
BA_ "GenSigStartValueInteger" SG_ 1176 BattTracCell41_U_Actl 4094;
BA_ "U_CD542_MY2021_Tx" SG_ 1175 BattTracCell40_U_Actl 1;
BA_ "U_CX727_MY2021_Tx" SG_ 1175 BattTracCell40_U_Actl 1;
BA_ "U_U55X_MY2022_Rx" SG_ 1175 BattTracCell40_U_Actl 1;
BA_ "U_CD542_MY2021_Rx" SG_ 1175 BattTracCell40_U_Actl 1;
BA_ "ECGUsedRxSignal" SG_ 1175 BattTracCell40_U_Actl 1;
BA_ "GenSigStartValue" SG_ 1175 BattTracCell40_U_Actl 4094;
BA_ "GenSigStartValueInteger" SG_ 1175 BattTracCell40_U_Actl 4094;
BA_ "U_CD542_MY2021_Tx" SG_ 1175 BattTracCell39_U_Actl 1;
BA_ "U_CX727_MY2021_Tx" SG_ 1175 BattTracCell39_U_Actl 1;
BA_ "U_U55X_MY2022_Rx" SG_ 1175 BattTracCell39_U_Actl 1;
BA_ "U_CD542_MY2021_Rx" SG_ 1175 BattTracCell39_U_Actl 1;
BA_ "ECGUsedRxSignal" SG_ 1175 BattTracCell39_U_Actl 1;
BA_ "GenSigStartValue" SG_ 1175 BattTracCell39_U_Actl 4094;
BA_ "GenSigStartValueInteger" SG_ 1175 BattTracCell39_U_Actl 4094;
BA_ "U_CD542_MY2021_Tx" SG_ 1175 BattTracCell38_U_Actl 1;
BA_ "U_CX727_MY2021_Tx" SG_ 1175 BattTracCell38_U_Actl 1;
BA_ "U_U55X_MY2022_Rx" SG_ 1175 BattTracCell38_U_Actl 1;
BA_ "U_CD542_MY2021_Rx" SG_ 1175 BattTracCell38_U_Actl 1;
BA_ "ECGUsedRxSignal" SG_ 1175 BattTracCell38_U_Actl 1;
BA_ "GenSigStartValue" SG_ 1175 BattTracCell38_U_Actl 4094;
BA_ "GenSigStartValueInteger" SG_ 1175 BattTracCell38_U_Actl 4094;
BA_ "U_CD542_MY2021_Tx" SG_ 1175 BattTracCell37_U_Actl 1;
BA_ "U_CX727_MY2021_Tx" SG_ 1175 BattTracCell37_U_Actl 1;
BA_ "U_U55X_MY2022_Rx" SG_ 1175 BattTracCell37_U_Actl 1;
BA_ "U_CD542_MY2021_Rx" SG_ 1175 BattTracCell37_U_Actl 1;
BA_ "ECGUsedRxSignal" SG_ 1175 BattTracCell37_U_Actl 1;
BA_ "GenSigStartValue" SG_ 1175 BattTracCell37_U_Actl 4094;
BA_ "GenSigStartValueInteger" SG_ 1175 BattTracCell37_U_Actl 4094;
BA_ "U_CD542_MY2021_Tx" SG_ 1175 BattTracCell36_U_Actl 1;
BA_ "U_CX727_MY2021_Tx" SG_ 1175 BattTracCell36_U_Actl 1;
BA_ "U_U55X_MY2022_Rx" SG_ 1175 BattTracCell36_U_Actl 1;
BA_ "U_CD542_MY2021_Rx" SG_ 1175 BattTracCell36_U_Actl 1;
BA_ "ECGUsedRxSignal" SG_ 1175 BattTracCell36_U_Actl 1;
BA_ "GenSigStartValue" SG_ 1175 BattTracCell36_U_Actl 4094;
BA_ "GenSigStartValueInteger" SG_ 1175 BattTracCell36_U_Actl 4094;
BA_ "U_CD542_MY2021_Tx" SG_ 1174 BattTracCell35_U_Actl 1;
BA_ "U_CX727_MY2021_Tx" SG_ 1174 BattTracCell35_U_Actl 1;
BA_ "U_U55X_MY2022_Rx" SG_ 1174 BattTracCell35_U_Actl 1;
BA_ "U_CD542_MY2021_Rx" SG_ 1174 BattTracCell35_U_Actl 1;
BA_ "ECGUsedRxSignal" SG_ 1174 BattTracCell35_U_Actl 1;
BA_ "GenSigStartValue" SG_ 1174 BattTracCell35_U_Actl 4094;
BA_ "GenSigStartValueInteger" SG_ 1174 BattTracCell35_U_Actl 4094;
BA_ "U_CD542_MY2021_Tx" SG_ 1174 BattTracCell34_U_Actl 1;
BA_ "U_CX727_MY2021_Tx" SG_ 1174 BattTracCell34_U_Actl 1;
BA_ "U_U55X_MY2022_Rx" SG_ 1174 BattTracCell34_U_Actl 1;
BA_ "U_CD542_MY2021_Rx" SG_ 1174 BattTracCell34_U_Actl 1;
BA_ "ECGUsedRxSignal" SG_ 1174 BattTracCell34_U_Actl 1;
BA_ "GenSigStartValue" SG_ 1174 BattTracCell34_U_Actl 4094;
BA_ "GenSigStartValueInteger" SG_ 1174 BattTracCell34_U_Actl 4094;
BA_ "U_CD542_MY2021_Tx" SG_ 1174 BattTracCell33_U_Actl 1;
BA_ "U_CX727_MY2021_Tx" SG_ 1174 BattTracCell33_U_Actl 1;
BA_ "U_U55X_MY2022_Rx" SG_ 1174 BattTracCell33_U_Actl 1;
BA_ "U_CD542_MY2021_Rx" SG_ 1174 BattTracCell33_U_Actl 1;
BA_ "ECGUsedRxSignal" SG_ 1174 BattTracCell33_U_Actl 1;
BA_ "GenSigStartValue" SG_ 1174 BattTracCell33_U_Actl 4094;
BA_ "GenSigStartValueInteger" SG_ 1174 BattTracCell33_U_Actl 4094;
BA_ "U_CD542_MY2021_Tx" SG_ 1174 BattTracCell32_U_Actl 1;
BA_ "U_CX727_MY2021_Tx" SG_ 1174 BattTracCell32_U_Actl 1;
BA_ "U_U55X_MY2022_Rx" SG_ 1174 BattTracCell32_U_Actl 1;
BA_ "U_CD542_MY2021_Rx" SG_ 1174 BattTracCell32_U_Actl 1;
BA_ "ECGUsedRxSignal" SG_ 1174 BattTracCell32_U_Actl 1;
BA_ "GenSigStartValue" SG_ 1174 BattTracCell32_U_Actl 4094;
BA_ "GenSigStartValueInteger" SG_ 1174 BattTracCell32_U_Actl 4094;
BA_ "U_CD542_MY2021_Tx" SG_ 1174 BattTracCell31_U_Actl 1;
BA_ "U_CX727_MY2021_Tx" SG_ 1174 BattTracCell31_U_Actl 1;
BA_ "U_U55X_MY2022_Rx" SG_ 1174 BattTracCell31_U_Actl 1;
BA_ "U_CD542_MY2021_Rx" SG_ 1174 BattTracCell31_U_Actl 1;
BA_ "ECGUsedRxSignal" SG_ 1174 BattTracCell31_U_Actl 1;
BA_ "GenSigStartValue" SG_ 1174 BattTracCell31_U_Actl 4094;
BA_ "GenSigStartValueInteger" SG_ 1174 BattTracCell31_U_Actl 4094;
BA_ "U_CD542_MY2021_Tx" SG_ 1173 BattTracCell30_U_Actl 1;
BA_ "U_CX727_MY2021_Tx" SG_ 1173 BattTracCell30_U_Actl 1;
BA_ "U_U55X_MY2022_Rx" SG_ 1173 BattTracCell30_U_Actl 1;
BA_ "U_CD542_MY2021_Rx" SG_ 1173 BattTracCell30_U_Actl 1;
BA_ "ECGUsedRxSignal" SG_ 1173 BattTracCell30_U_Actl 1;
BA_ "GenSigStartValue" SG_ 1173 BattTracCell30_U_Actl 4094;
BA_ "GenSigStartValueInteger" SG_ 1173 BattTracCell30_U_Actl 4094;
BA_ "U_CD542_MY2021_Tx" SG_ 1173 BattTracCell29_U_Actl 1;
BA_ "U_CX727_MY2021_Tx" SG_ 1173 BattTracCell29_U_Actl 1;
BA_ "U_U55X_MY2022_Rx" SG_ 1173 BattTracCell29_U_Actl 1;
BA_ "U_CD542_MY2021_Rx" SG_ 1173 BattTracCell29_U_Actl 1;
BA_ "ECGUsedRxSignal" SG_ 1173 BattTracCell29_U_Actl 1;
BA_ "GenSigStartValue" SG_ 1173 BattTracCell29_U_Actl 4094;
BA_ "GenSigStartValueInteger" SG_ 1173 BattTracCell29_U_Actl 4094;
BA_ "U_CD542_MY2021_Tx" SG_ 1173 BattTracCell28_U_Actl 1;
BA_ "U_CX727_MY2021_Tx" SG_ 1173 BattTracCell28_U_Actl 1;
BA_ "U_U55X_MY2022_Rx" SG_ 1173 BattTracCell28_U_Actl 1;
BA_ "U_CD542_MY2021_Rx" SG_ 1173 BattTracCell28_U_Actl 1;
BA_ "ECGUsedRxSignal" SG_ 1173 BattTracCell28_U_Actl 1;
BA_ "GenSigStartValue" SG_ 1173 BattTracCell28_U_Actl 4094;
BA_ "GenSigStartValueInteger" SG_ 1173 BattTracCell28_U_Actl 4094;
BA_ "U_CD542_MY2021_Tx" SG_ 1173 BattTracCell27_U_Actl 1;
BA_ "U_CX727_MY2021_Tx" SG_ 1173 BattTracCell27_U_Actl 1;
BA_ "U_U55X_MY2022_Rx" SG_ 1173 BattTracCell27_U_Actl 1;
BA_ "U_CD542_MY2021_Rx" SG_ 1173 BattTracCell27_U_Actl 1;
BA_ "ECGUsedRxSignal" SG_ 1173 BattTracCell27_U_Actl 1;
BA_ "GenSigStartValue" SG_ 1173 BattTracCell27_U_Actl 4094;
BA_ "GenSigStartValueInteger" SG_ 1173 BattTracCell27_U_Actl 4094;
BA_ "U_CD542_MY2021_Tx" SG_ 1173 BattTracCell26_U_Actl 1;
BA_ "U_CX727_MY2021_Tx" SG_ 1173 BattTracCell26_U_Actl 1;
BA_ "U_U55X_MY2022_Rx" SG_ 1173 BattTracCell26_U_Actl 1;
BA_ "U_CD542_MY2021_Rx" SG_ 1173 BattTracCell26_U_Actl 1;
BA_ "ECGUsedRxSignal" SG_ 1173 BattTracCell26_U_Actl 1;
BA_ "GenSigStartValue" SG_ 1173 BattTracCell26_U_Actl 4094;
BA_ "GenSigStartValueInteger" SG_ 1173 BattTracCell26_U_Actl 4094;
BA_ "U_CD542_MY2021_Tx" SG_ 1172 BattTracCell25_U_Actl 1;
BA_ "U_CX727_MY2021_Tx" SG_ 1172 BattTracCell25_U_Actl 1;
BA_ "U_U55X_MY2022_Rx" SG_ 1172 BattTracCell25_U_Actl 1;
BA_ "U_CD542_MY2021_Rx" SG_ 1172 BattTracCell25_U_Actl 1;
BA_ "ECGUsedRxSignal" SG_ 1172 BattTracCell25_U_Actl 1;
BA_ "GenSigStartValue" SG_ 1172 BattTracCell25_U_Actl 4094;
BA_ "GenSigStartValueInteger" SG_ 1172 BattTracCell25_U_Actl 4094;
BA_ "U_CD542_MY2021_Tx" SG_ 1172 BattTracCell24_U_Actl 1;
BA_ "U_CX727_MY2021_Tx" SG_ 1172 BattTracCell24_U_Actl 1;
BA_ "U_U55X_MY2022_Rx" SG_ 1172 BattTracCell24_U_Actl 1;
BA_ "U_CD542_MY2021_Rx" SG_ 1172 BattTracCell24_U_Actl 1;
BA_ "ECGUsedRxSignal" SG_ 1172 BattTracCell24_U_Actl 1;
BA_ "GenSigStartValue" SG_ 1172 BattTracCell24_U_Actl 4094;
BA_ "GenSigStartValueInteger" SG_ 1172 BattTracCell24_U_Actl 4094;
BA_ "U_CD542_MY2021_Tx" SG_ 1172 BattTracCell23_U_Actl 1;
BA_ "U_CX727_MY2021_Tx" SG_ 1172 BattTracCell23_U_Actl 1;
BA_ "U_U55X_MY2022_Rx" SG_ 1172 BattTracCell23_U_Actl 1;
BA_ "U_CD542_MY2021_Rx" SG_ 1172 BattTracCell23_U_Actl 1;
BA_ "ECGUsedRxSignal" SG_ 1172 BattTracCell23_U_Actl 1;
BA_ "GenSigStartValue" SG_ 1172 BattTracCell23_U_Actl 4094;
BA_ "GenSigStartValueInteger" SG_ 1172 BattTracCell23_U_Actl 4094;
BA_ "U_CD542_MY2021_Tx" SG_ 1172 BattTracCell22_U_Actl 1;
BA_ "U_CX727_MY2021_Tx" SG_ 1172 BattTracCell22_U_Actl 1;
BA_ "U_U55X_MY2022_Rx" SG_ 1172 BattTracCell22_U_Actl 1;
BA_ "U_CD542_MY2021_Rx" SG_ 1172 BattTracCell22_U_Actl 1;
BA_ "ECGUsedRxSignal" SG_ 1172 BattTracCell22_U_Actl 1;
BA_ "GenSigStartValue" SG_ 1172 BattTracCell22_U_Actl 4094;
BA_ "GenSigStartValueInteger" SG_ 1172 BattTracCell22_U_Actl 4094;
BA_ "U_CD542_MY2021_Tx" SG_ 1172 BattTracCell21_U_Actl 1;
BA_ "U_CX727_MY2021_Tx" SG_ 1172 BattTracCell21_U_Actl 1;
BA_ "U_U55X_MY2022_Rx" SG_ 1172 BattTracCell21_U_Actl 1;
BA_ "U_CD542_MY2021_Rx" SG_ 1172 BattTracCell21_U_Actl 1;
BA_ "ECGUsedRxSignal" SG_ 1172 BattTracCell21_U_Actl 1;
BA_ "GenSigStartValue" SG_ 1172 BattTracCell21_U_Actl 4094;
BA_ "GenSigStartValueInteger" SG_ 1172 BattTracCell21_U_Actl 4094;
BA_ "U_CD542_MY2021_Tx" SG_ 1171 BattTracCell20_U_Actl 1;
BA_ "U_CX727_MY2021_Tx" SG_ 1171 BattTracCell20_U_Actl 1;
BA_ "U_U55X_MY2022_Rx" SG_ 1171 BattTracCell20_U_Actl 1;
BA_ "U_CD542_MY2021_Rx" SG_ 1171 BattTracCell20_U_Actl 1;
BA_ "ECGUsedRxSignal" SG_ 1171 BattTracCell20_U_Actl 1;
BA_ "GenSigStartValue" SG_ 1171 BattTracCell20_U_Actl 4094;
BA_ "GenSigStartValueInteger" SG_ 1171 BattTracCell20_U_Actl 4094;
BA_ "U_CD542_MY2021_Tx" SG_ 1171 BattTracCell19_U_Actl 1;
BA_ "U_CX727_MY2021_Tx" SG_ 1171 BattTracCell19_U_Actl 1;
BA_ "U_U55X_MY2022_Rx" SG_ 1171 BattTracCell19_U_Actl 1;
BA_ "U_CD542_MY2021_Rx" SG_ 1171 BattTracCell19_U_Actl 1;
BA_ "ECGUsedRxSignal" SG_ 1171 BattTracCell19_U_Actl 1;
BA_ "GenSigStartValue" SG_ 1171 BattTracCell19_U_Actl 4094;
BA_ "GenSigStartValueInteger" SG_ 1171 BattTracCell19_U_Actl 4094;
BA_ "U_CD542_MY2021_Tx" SG_ 1171 BattTracCell18_U_Actl 1;
BA_ "U_CX727_MY2021_Tx" SG_ 1171 BattTracCell18_U_Actl 1;
BA_ "U_U55X_MY2022_Rx" SG_ 1171 BattTracCell18_U_Actl 1;
BA_ "U_CD542_MY2021_Rx" SG_ 1171 BattTracCell18_U_Actl 1;
BA_ "ECGUsedRxSignal" SG_ 1171 BattTracCell18_U_Actl 1;
BA_ "GenSigStartValue" SG_ 1171 BattTracCell18_U_Actl 4094;
BA_ "GenSigStartValueInteger" SG_ 1171 BattTracCell18_U_Actl 4094;
BA_ "U_CD542_MY2021_Tx" SG_ 1171 BattTracCell17_U_Actl 1;
BA_ "U_CX727_MY2021_Tx" SG_ 1171 BattTracCell17_U_Actl 1;
BA_ "U_U55X_MY2022_Rx" SG_ 1171 BattTracCell17_U_Actl 1;
BA_ "U_CD542_MY2021_Rx" SG_ 1171 BattTracCell17_U_Actl 1;
BA_ "ECGUsedRxSignal" SG_ 1171 BattTracCell17_U_Actl 1;
BA_ "GenSigStartValue" SG_ 1171 BattTracCell17_U_Actl 4094;
BA_ "GenSigStartValueInteger" SG_ 1171 BattTracCell17_U_Actl 4094;
BA_ "U_CD542_MY2021_Tx" SG_ 1171 BattTracCell16_U_Actl 1;
BA_ "U_CX727_MY2021_Tx" SG_ 1171 BattTracCell16_U_Actl 1;
BA_ "U_U55X_MY2022_Rx" SG_ 1171 BattTracCell16_U_Actl 1;
BA_ "U_CD542_MY2021_Rx" SG_ 1171 BattTracCell16_U_Actl 1;
BA_ "ECGUsedRxSignal" SG_ 1171 BattTracCell16_U_Actl 1;
BA_ "GenSigStartValue" SG_ 1171 BattTracCell16_U_Actl 4094;
BA_ "GenSigStartValueInteger" SG_ 1171 BattTracCell16_U_Actl 4094;
BA_ "U_CD542_MY2021_Tx" SG_ 1170 BattTracCell15_U_Actl 1;
BA_ "U_CX727_MY2021_Tx" SG_ 1170 BattTracCell15_U_Actl 1;
BA_ "U_U55X_MY2022_Rx" SG_ 1170 BattTracCell15_U_Actl 1;
BA_ "U_CD542_MY2021_Rx" SG_ 1170 BattTracCell15_U_Actl 1;
BA_ "ECGUsedRxSignal" SG_ 1170 BattTracCell15_U_Actl 1;
BA_ "GenSigStartValue" SG_ 1170 BattTracCell15_U_Actl 4094;
BA_ "GenSigStartValueInteger" SG_ 1170 BattTracCell15_U_Actl 4094;
BA_ "U_CD542_MY2021_Tx" SG_ 1170 BattTracCell14_U_Actl 1;
BA_ "U_CX727_MY2021_Tx" SG_ 1170 BattTracCell14_U_Actl 1;
BA_ "U_U55X_MY2022_Rx" SG_ 1170 BattTracCell14_U_Actl 1;
BA_ "U_CD542_MY2021_Rx" SG_ 1170 BattTracCell14_U_Actl 1;
BA_ "ECGUsedRxSignal" SG_ 1170 BattTracCell14_U_Actl 1;
BA_ "GenSigStartValue" SG_ 1170 BattTracCell14_U_Actl 4094;
BA_ "GenSigStartValueInteger" SG_ 1170 BattTracCell14_U_Actl 4094;
BA_ "U_CD542_MY2021_Tx" SG_ 1170 BattTracCell13_U_Actl 1;
BA_ "U_CX727_MY2021_Tx" SG_ 1170 BattTracCell13_U_Actl 1;
BA_ "U_U55X_MY2022_Rx" SG_ 1170 BattTracCell13_U_Actl 1;
BA_ "U_CD542_MY2021_Rx" SG_ 1170 BattTracCell13_U_Actl 1;
BA_ "ECGUsedRxSignal" SG_ 1170 BattTracCell13_U_Actl 1;
BA_ "GenSigStartValue" SG_ 1170 BattTracCell13_U_Actl 4094;
BA_ "GenSigStartValueInteger" SG_ 1170 BattTracCell13_U_Actl 4094;
BA_ "U_CD542_MY2021_Tx" SG_ 1170 BattTracCell12_U_Actl 1;
BA_ "U_CX727_MY2021_Tx" SG_ 1170 BattTracCell12_U_Actl 1;
BA_ "U_U55X_MY2022_Rx" SG_ 1170 BattTracCell12_U_Actl 1;
BA_ "U_CD542_MY2021_Rx" SG_ 1170 BattTracCell12_U_Actl 1;
BA_ "ECGUsedRxSignal" SG_ 1170 BattTracCell12_U_Actl 1;
BA_ "GenSigStartValue" SG_ 1170 BattTracCell12_U_Actl 4094;
BA_ "GenSigStartValueInteger" SG_ 1170 BattTracCell12_U_Actl 4094;
BA_ "U_CD542_MY2021_Tx" SG_ 1170 BattTracCell11_U_Actl 1;
BA_ "U_CX727_MY2021_Tx" SG_ 1170 BattTracCell11_U_Actl 1;
BA_ "U_U55X_MY2022_Rx" SG_ 1170 BattTracCell11_U_Actl 1;
BA_ "U_CD542_MY2021_Rx" SG_ 1170 BattTracCell11_U_Actl 1;
BA_ "ECGUsedRxSignal" SG_ 1170 BattTracCell11_U_Actl 1;
BA_ "GenSigStartValue" SG_ 1170 BattTracCell11_U_Actl 4094;
BA_ "GenSigStartValueInteger" SG_ 1170 BattTracCell11_U_Actl 4094;
BA_ "U_CD542_MY2021_Tx" SG_ 1191 BattTracTe14_Te_Actl 1;
BA_ "U_CX727_MY2021_Tx" SG_ 1191 BattTracTe14_Te_Actl 1;
BA_ "U_U55X_MY2022_Rx" SG_ 1191 BattTracTe14_Te_Actl 1;
BA_ "U_CD542_MY2021_Rx" SG_ 1191 BattTracTe14_Te_Actl 1;
BA_ "ECGUsedRxSignal" SG_ 1191 BattTracTe14_Te_Actl 1;
BA_ "GenSigStartValue" SG_ 1191 BattTracTe14_Te_Actl 254;
BA_ "GenSigStartValueInteger" SG_ 1191 BattTracTe14_Te_Actl 254;
BA_ "U_CD542_MY2021_Tx" SG_ 1191 BattTracTe19_Te_Actl 1;
BA_ "U_CX727_MY2021_Tx" SG_ 1191 BattTracTe19_Te_Actl 1;
BA_ "U_U55X_MY2022_Rx" SG_ 1191 BattTracTe19_Te_Actl 1;
BA_ "U_CD542_MY2021_Rx" SG_ 1191 BattTracTe19_Te_Actl 1;
BA_ "ECGUsedRxSignal" SG_ 1191 BattTracTe19_Te_Actl 1;
BA_ "GenSigStartValue" SG_ 1191 BattTracTe19_Te_Actl 254;
BA_ "GenSigStartValueInteger" SG_ 1191 BattTracTe19_Te_Actl 254;
BA_ "U_CD542_MY2021_Tx" SG_ 1191 BattTracTe18_Te_Actl 1;
BA_ "U_CX727_MY2021_Tx" SG_ 1191 BattTracTe18_Te_Actl 1;
BA_ "U_U55X_MY2022_Rx" SG_ 1191 BattTracTe18_Te_Actl 1;
BA_ "U_CD542_MY2021_Rx" SG_ 1191 BattTracTe18_Te_Actl 1;
BA_ "ECGUsedRxSignal" SG_ 1191 BattTracTe18_Te_Actl 1;
BA_ "GenSigStartValue" SG_ 1191 BattTracTe18_Te_Actl 254;
BA_ "GenSigStartValueInteger" SG_ 1191 BattTracTe18_Te_Actl 254;
BA_ "U_CD542_MY2021_Tx" SG_ 1191 BattTracTe17_Te_Actl 1;
BA_ "U_CX727_MY2021_Tx" SG_ 1191 BattTracTe17_Te_Actl 1;
BA_ "U_U55X_MY2022_Rx" SG_ 1191 BattTracTe17_Te_Actl 1;
BA_ "U_CD542_MY2021_Rx" SG_ 1191 BattTracTe17_Te_Actl 1;
BA_ "ECGUsedRxSignal" SG_ 1191 BattTracTe17_Te_Actl 1;
BA_ "GenSigStartValue" SG_ 1191 BattTracTe17_Te_Actl 254;
BA_ "GenSigStartValueInteger" SG_ 1191 BattTracTe17_Te_Actl 254;
BA_ "U_CD542_MY2021_Tx" SG_ 1191 BattTracTe16_Te_Actl 1;
BA_ "U_CX727_MY2021_Tx" SG_ 1191 BattTracTe16_Te_Actl 1;
BA_ "U_U55X_MY2022_Rx" SG_ 1191 BattTracTe16_Te_Actl 1;
BA_ "U_CD542_MY2021_Rx" SG_ 1191 BattTracTe16_Te_Actl 1;
BA_ "ECGUsedRxSignal" SG_ 1191 BattTracTe16_Te_Actl 1;
BA_ "GenSigStartValue" SG_ 1191 BattTracTe16_Te_Actl 254;
BA_ "GenSigStartValueInteger" SG_ 1191 BattTracTe16_Te_Actl 254;
BA_ "U_CD542_MY2021_Tx" SG_ 1191 BattTracTe15_Te_Actl 1;
BA_ "U_CX727_MY2021_Tx" SG_ 1191 BattTracTe15_Te_Actl 1;
BA_ "U_U55X_MY2022_Rx" SG_ 1191 BattTracTe15_Te_Actl 1;
BA_ "U_CD542_MY2021_Rx" SG_ 1191 BattTracTe15_Te_Actl 1;
BA_ "ECGUsedRxSignal" SG_ 1191 BattTracTe15_Te_Actl 1;
BA_ "GenSigStartValue" SG_ 1191 BattTracTe15_Te_Actl 254;
BA_ "GenSigStartValueInteger" SG_ 1191 BattTracTe15_Te_Actl 254;
BA_ "U_CD542_MY2021_Tx" SG_ 1189 BattTracCellUMx_No_Actl 1;
BA_ "U_CX727_MY2021_Tx" SG_ 1189 BattTracCellUMx_No_Actl 1;
BA_ "U_U55X_MY2022_Rx" SG_ 1189 BattTracCellUMx_No_Actl 1;
BA_ "U_CD542_MY2021_Rx" SG_ 1189 BattTracCellUMx_No_Actl 1;
BA_ "ECGUsedRxSignal" SG_ 1189 BattTracCellUMx_No_Actl 1;
BA_ "GenSigStartValue" SG_ 1189 BattTracCellUMx_No_Actl 254;
BA_ "GenSigStartValueInteger" SG_ 1189 BattTracCellUMx_No_Actl 254;
BA_ "U_CD542_MY2021_Tx" SG_ 1189 BattChrgUMx_B_Falt 1;
BA_ "U_CX727_MY2021_Tx" SG_ 1189 BattChrgUMx_B_Falt 1;
BA_ "U_U55X_MY2022_Rx" SG_ 1189 BattChrgUMx_B_Falt 1;
BA_ "U_CD542_MY2021_Rx" SG_ 1189 BattChrgUMx_B_Falt 1;
BA_ "ECGUsedRxSignal" SG_ 1189 BattChrgUMx_B_Falt 1;
BA_ "U_CD542_MY2021_Tx" SG_ 1189 BattTracCellUMn_No_Actl 1;
BA_ "U_CX727_MY2021_Tx" SG_ 1189 BattTracCellUMn_No_Actl 1;
BA_ "U_U55X_MY2022_Rx" SG_ 1189 BattTracCellUMn_No_Actl 1;
BA_ "U_CD542_MY2021_Rx" SG_ 1189 BattTracCellUMn_No_Actl 1;
BA_ "ECGUsedRxSignal" SG_ 1189 BattTracCellUMn_No_Actl 1;
BA_ "GenSigStartValue" SG_ 1189 BattTracCellUMn_No_Actl 254;
BA_ "GenSigStartValueInteger" SG_ 1189 BattTracCellUMn_No_Actl 254;
BA_ "U_CD542_MY2021_Tx" SG_ 1189 BattTracCellCnt_No_Actl 1;
BA_ "U_CX727_MY2021_Tx" SG_ 1189 BattTracCellCnt_No_Actl 1;
BA_ "U_U55X_MY2022_Rx" SG_ 1189 BattTracCellCnt_No_Actl 1;
BA_ "U_CD542_MY2021_Rx" SG_ 1189 BattTracCellCnt_No_Actl 1;
BA_ "ECGUsedRxSignal" SG_ 1189 BattTracCellCnt_No_Actl 1;
BA_ "GenSigStartValue" SG_ 1189 BattTracCellCnt_No_Actl 254;
BA_ "GenSigStartValueInteger" SG_ 1189 BattTracCellCnt_No_Actl 254;
BA_ "U_CD542_MY2021_Tx" SG_ 1189 BattTracCellDiff_B_Falt 1;
BA_ "U_CX727_MY2021_Tx" SG_ 1189 BattTracCellDiff_B_Falt 1;
BA_ "U_U55X_MY2022_Rx" SG_ 1189 BattTracCellDiff_B_Falt 1;
BA_ "U_CD542_MY2021_Rx" SG_ 1189 BattTracCellDiff_B_Falt 1;
BA_ "ECGUsedRxSignal" SG_ 1189 BattTracCellDiff_B_Falt 1;
BA_ "U_CD542_MY2021_Tx" SG_ 1189 BattChrgSocMx_B_Falt 1;
BA_ "U_CX727_MY2021_Tx" SG_ 1189 BattChrgSocMx_B_Falt 1;
BA_ "U_U55X_MY2022_Rx" SG_ 1189 BattChrgSocMx_B_Falt 1;
BA_ "U_CD542_MY2021_Rx" SG_ 1189 BattChrgSocMx_B_Falt 1;
BA_ "ECGUsedRxSignal" SG_ 1189 BattChrgSocMx_B_Falt 1;
BA_ "U_CD542_MY2021_Tx" SG_ 1189 BattChrgSocMn_B_Falt 1;
BA_ "U_CX727_MY2021_Tx" SG_ 1189 BattChrgSocMn_B_Falt 1;
BA_ "U_U55X_MY2022_Rx" SG_ 1189 BattChrgSocMn_B_Falt 1;
BA_ "U_CD542_MY2021_Rx" SG_ 1189 BattChrgSocMn_B_Falt 1;
BA_ "ECGUsedRxSignal" SG_ 1189 BattChrgSocMn_B_Falt 1;
BA_ "U_CD542_MY2021_Tx" SG_ 1189 BattChrgSocErrtc_B_Falt 1;
BA_ "U_CX727_MY2021_Tx" SG_ 1189 BattChrgSocErrtc_B_Falt 1;
BA_ "U_U55X_MY2022_Rx" SG_ 1189 BattChrgSocErrtc_B_Falt 1;
BA_ "U_CD542_MY2021_Rx" SG_ 1189 BattChrgSocErrtc_B_Falt 1;
BA_ "ECGUsedRxSignal" SG_ 1189 BattChrgSocErrtc_B_Falt 1;
BA_ "U_CD542_MY2021_Tx" SG_ 1189 BattTracUMx_B_Falt 1;
BA_ "U_CX727_MY2021_Tx" SG_ 1189 BattTracUMx_B_Falt 1;
BA_ "U_U55X_MY2022_Rx" SG_ 1189 BattTracUMx_B_Falt 1;
BA_ "U_CD542_MY2021_Rx" SG_ 1189 BattTracUMx_B_Falt 1;
BA_ "ECGUsedRxSignal" SG_ 1189 BattTracUMx_B_Falt 1;
BA_ "U_CD542_MY2021_Tx" SG_ 1189 BattTracUMn_B_Falt 1;
BA_ "U_CX727_MY2021_Tx" SG_ 1189 BattTracUMn_B_Falt 1;
BA_ "U_U55X_MY2022_Rx" SG_ 1189 BattTracUMn_B_Falt 1;
BA_ "U_CD542_MY2021_Rx" SG_ 1189 BattTracUMn_B_Falt 1;
BA_ "ECGUsedRxSignal" SG_ 1189 BattTracUMn_B_Falt 1;
BA_ "U_CD542_MY2021_Tx" SG_ 1189 BattTracTeMx_No_Actl 1;
BA_ "U_CX727_MY2021_Tx" SG_ 1189 BattTracTeMx_No_Actl 1;
BA_ "U_U55X_MY2022_Rx" SG_ 1189 BattTracTeMx_No_Actl 1;
BA_ "U_CD542_MY2021_Rx" SG_ 1189 BattTracTeMx_No_Actl 1;
BA_ "ECGUsedRxSignal" SG_ 1189 BattTracTeMx_No_Actl 1;
BA_ "GenSigStartValue" SG_ 1189 BattTracTeMx_No_Actl 254;
BA_ "GenSigStartValueInteger" SG_ 1189 BattTracTeMx_No_Actl 254;
BA_ "U_CD542_MY2021_Tx" SG_ 1189 BattTracTeMx_B_Falt 1;
BA_ "U_CX727_MY2021_Tx" SG_ 1189 BattTracTeMx_B_Falt 1;
BA_ "U_U55X_MY2022_Rx" SG_ 1189 BattTracTeMx_B_Falt 1;
BA_ "U_CD542_MY2021_Rx" SG_ 1189 BattTracTeMx_B_Falt 1;
BA_ "ECGUsedRxSignal" SG_ 1189 BattTracTeMx_B_Falt 1;
BA_ "U_CD542_MY2021_Tx" SG_ 1189 BattTracTeMn_No_Actl 1;
BA_ "U_CX727_MY2021_Tx" SG_ 1189 BattTracTeMn_No_Actl 1;
BA_ "U_U55X_MY2022_Rx" SG_ 1189 BattTracTeMn_No_Actl 1;
BA_ "U_CD542_MY2021_Rx" SG_ 1189 BattTracTeMn_No_Actl 1;
BA_ "ECGUsedRxSignal" SG_ 1189 BattTracTeMn_No_Actl 1;
BA_ "GenSigStartValue" SG_ 1189 BattTracTeMn_No_Actl 254;
BA_ "GenSigStartValueInteger" SG_ 1189 BattTracTeMn_No_Actl 254;
BA_ "U_CD542_MY2021_Tx" SG_ 1189 BattTracTeDelta_B_Falt 1;
BA_ "U_CX727_MY2021_Tx" SG_ 1189 BattTracTeDelta_B_Falt 1;
BA_ "U_U55X_MY2022_Rx" SG_ 1189 BattTracTeDelta_B_Falt 1;
BA_ "U_CD542_MY2021_Rx" SG_ 1189 BattTracTeDelta_B_Falt 1;
BA_ "ECGUsedRxSignal" SG_ 1189 BattTracTeDelta_B_Falt 1;
BA_ "U_CD542_MY2021_Tx" SG_ 1189 BattTracTeCnt_No_Actl 1;
BA_ "U_CX727_MY2021_Tx" SG_ 1189 BattTracTeCnt_No_Actl 1;
BA_ "U_U55X_MY2022_Rx" SG_ 1189 BattTracTeCnt_No_Actl 1;
BA_ "U_CD542_MY2021_Rx" SG_ 1189 BattTracTeCnt_No_Actl 1;
BA_ "ECGUsedRxSignal" SG_ 1189 BattTracTeCnt_No_Actl 1;
BA_ "GenSigStartValue" SG_ 1189 BattTracTeCnt_No_Actl 254;
BA_ "GenSigStartValueInteger" SG_ 1189 BattTracTeCnt_No_Actl 254;
BA_ "U_CD542_MY2021_Tx" SG_ 1189 BattTracSoftware_B_Falt 1;
BA_ "U_CX727_MY2021_Tx" SG_ 1189 BattTracSoftware_B_Falt 1;
BA_ "U_U55X_MY2022_Rx" SG_ 1189 BattTracSoftware_B_Falt 1;
BA_ "U_CD542_MY2021_Rx" SG_ 1189 BattTracSoftware_B_Falt 1;
BA_ "ECGUsedRxSignal" SG_ 1189 BattTracSoftware_B_Falt 1;
BA_ "U_CD542_MY2021_Tx" SG_ 1188 BattTracTe13_Te_Actl 1;
BA_ "U_CX727_MY2021_Tx" SG_ 1188 BattTracTe13_Te_Actl 1;
BA_ "U_U55X_MY2022_Rx" SG_ 1188 BattTracTe13_Te_Actl 1;
BA_ "U_CD542_MY2021_Rx" SG_ 1188 BattTracTe13_Te_Actl 1;
BA_ "ECGUsedRxSignal" SG_ 1188 BattTracTe13_Te_Actl 1;
BA_ "GenSigStartValue" SG_ 1188 BattTracTe13_Te_Actl 254;
BA_ "GenSigStartValueInteger" SG_ 1188 BattTracTe13_Te_Actl 254;
BA_ "U_CD542_MY2021_Tx" SG_ 1188 BattTracTe12_Te_Actl 1;
BA_ "U_CX727_MY2021_Tx" SG_ 1188 BattTracTe12_Te_Actl 1;
BA_ "U_U55X_MY2022_Rx" SG_ 1188 BattTracTe12_Te_Actl 1;
BA_ "U_CD542_MY2021_Rx" SG_ 1188 BattTracTe12_Te_Actl 1;
BA_ "ECGUsedRxSignal" SG_ 1188 BattTracTe12_Te_Actl 1;
BA_ "GenSigStartValue" SG_ 1188 BattTracTe12_Te_Actl 254;
BA_ "GenSigStartValueInteger" SG_ 1188 BattTracTe12_Te_Actl 254;
BA_ "U_CD542_MY2021_Tx" SG_ 1188 BattTracTe11_Te_Actl 1;
BA_ "U_CX727_MY2021_Tx" SG_ 1188 BattTracTe11_Te_Actl 1;
BA_ "U_U55X_MY2022_Rx" SG_ 1188 BattTracTe11_Te_Actl 1;
BA_ "U_CD542_MY2021_Rx" SG_ 1188 BattTracTe11_Te_Actl 1;
BA_ "ECGUsedRxSignal" SG_ 1188 BattTracTe11_Te_Actl 1;
BA_ "GenSigStartValue" SG_ 1188 BattTracTe11_Te_Actl 254;
BA_ "GenSigStartValueInteger" SG_ 1188 BattTracTe11_Te_Actl 254;
BA_ "U_CD542_MY2021_Tx" SG_ 1188 BattTracTe10_Te_Actl 1;
BA_ "U_CX727_MY2021_Tx" SG_ 1188 BattTracTe10_Te_Actl 1;
BA_ "U_U55X_MY2022_Rx" SG_ 1188 BattTracTe10_Te_Actl 1;
BA_ "U_CD542_MY2021_Rx" SG_ 1188 BattTracTe10_Te_Actl 1;
BA_ "ECGUsedRxSignal" SG_ 1188 BattTracTe10_Te_Actl 1;
BA_ "GenSigStartValue" SG_ 1188 BattTracTe10_Te_Actl 254;
BA_ "GenSigStartValueInteger" SG_ 1188 BattTracTe10_Te_Actl 254;
BA_ "U_CD542_MY2021_Tx" SG_ 1188 BattTracTe09_Te_Actl 1;
BA_ "U_CX727_MY2021_Tx" SG_ 1188 BattTracTe09_Te_Actl 1;
BA_ "U_U55X_MY2022_Rx" SG_ 1188 BattTracTe09_Te_Actl 1;
BA_ "U_CD542_MY2021_Rx" SG_ 1188 BattTracTe09_Te_Actl 1;
BA_ "ECGUsedRxSignal" SG_ 1188 BattTracTe09_Te_Actl 1;
BA_ "GenSigStartValue" SG_ 1188 BattTracTe09_Te_Actl 254;
BA_ "GenSigStartValueInteger" SG_ 1188 BattTracTe09_Te_Actl 254;
BA_ "U_CD542_MY2021_Tx" SG_ 1188 BattTracTe08_Te_Actl 1;
BA_ "U_CX727_MY2021_Tx" SG_ 1188 BattTracTe08_Te_Actl 1;
BA_ "U_U55X_MY2022_Rx" SG_ 1188 BattTracTe08_Te_Actl 1;
BA_ "U_CD542_MY2021_Rx" SG_ 1188 BattTracTe08_Te_Actl 1;
BA_ "ECGUsedRxSignal" SG_ 1188 BattTracTe08_Te_Actl 1;
BA_ "GenSigStartValue" SG_ 1188 BattTracTe08_Te_Actl 254;
BA_ "GenSigStartValueInteger" SG_ 1188 BattTracTe08_Te_Actl 254;
BA_ "U_CD542_MY2021_Tx" SG_ 1188 BattTracTe07_Te_Actl 1;
BA_ "U_CX727_MY2021_Tx" SG_ 1188 BattTracTe07_Te_Actl 1;
BA_ "U_U55X_MY2022_Rx" SG_ 1188 BattTracTe07_Te_Actl 1;
BA_ "U_CD542_MY2021_Rx" SG_ 1188 BattTracTe07_Te_Actl 1;
BA_ "ECGUsedRxSignal" SG_ 1188 BattTracTe07_Te_Actl 1;
BA_ "GenSigStartValue" SG_ 1188 BattTracTe07_Te_Actl 254;
BA_ "GenSigStartValueInteger" SG_ 1188 BattTracTe07_Te_Actl 254;
BA_ "U_CD542_MY2021_Tx" SG_ 1187 BattTracTe06_Te_Actl 1;
BA_ "U_CX727_MY2021_Tx" SG_ 1187 BattTracTe06_Te_Actl 1;
BA_ "U_U55X_MY2022_Rx" SG_ 1187 BattTracTe06_Te_Actl 1;
BA_ "U_CD542_MY2021_Rx" SG_ 1187 BattTracTe06_Te_Actl 1;
BA_ "ECGUsedRxSignal" SG_ 1187 BattTracTe06_Te_Actl 1;
BA_ "GenSigStartValue" SG_ 1187 BattTracTe06_Te_Actl 254;
BA_ "GenSigStartValueInteger" SG_ 1187 BattTracTe06_Te_Actl 254;
BA_ "U_CD542_MY2021_Tx" SG_ 1187 BattTracTe05_Te_Actl 1;
BA_ "U_CX727_MY2021_Tx" SG_ 1187 BattTracTe05_Te_Actl 1;
BA_ "U_U55X_MY2022_Rx" SG_ 1187 BattTracTe05_Te_Actl 1;
BA_ "U_CD542_MY2021_Rx" SG_ 1187 BattTracTe05_Te_Actl 1;
BA_ "ECGUsedRxSignal" SG_ 1187 BattTracTe05_Te_Actl 1;
BA_ "GenSigStartValue" SG_ 1187 BattTracTe05_Te_Actl 254;
BA_ "GenSigStartValueInteger" SG_ 1187 BattTracTe05_Te_Actl 254;
BA_ "U_CD542_MY2021_Tx" SG_ 1187 BattTracTe04_Te_Actl 1;
BA_ "U_CX727_MY2021_Tx" SG_ 1187 BattTracTe04_Te_Actl 1;
BA_ "U_U55X_MY2022_Rx" SG_ 1187 BattTracTe04_Te_Actl 1;
BA_ "U_CD542_MY2021_Rx" SG_ 1187 BattTracTe04_Te_Actl 1;
BA_ "ECGUsedRxSignal" SG_ 1187 BattTracTe04_Te_Actl 1;
BA_ "GenSigStartValue" SG_ 1187 BattTracTe04_Te_Actl 254;
BA_ "GenSigStartValueInteger" SG_ 1187 BattTracTe04_Te_Actl 254;
BA_ "U_CD542_MY2021_Tx" SG_ 1187 BattTracTe03_Te_Actl 1;
BA_ "U_CX727_MY2021_Tx" SG_ 1187 BattTracTe03_Te_Actl 1;
BA_ "U_U55X_MY2022_Rx" SG_ 1187 BattTracTe03_Te_Actl 1;
BA_ "U_CD542_MY2021_Rx" SG_ 1187 BattTracTe03_Te_Actl 1;
BA_ "ECGUsedRxSignal" SG_ 1187 BattTracTe03_Te_Actl 1;
BA_ "GenSigStartValue" SG_ 1187 BattTracTe03_Te_Actl 254;
BA_ "GenSigStartValueInteger" SG_ 1187 BattTracTe03_Te_Actl 254;
BA_ "U_CD542_MY2021_Tx" SG_ 1187 BattTracTe02_Te_Actl 1;
BA_ "U_CX727_MY2021_Tx" SG_ 1187 BattTracTe02_Te_Actl 1;
BA_ "U_U55X_MY2022_Rx" SG_ 1187 BattTracTe02_Te_Actl 1;
BA_ "U_CD542_MY2021_Rx" SG_ 1187 BattTracTe02_Te_Actl 1;
BA_ "ECGUsedRxSignal" SG_ 1187 BattTracTe02_Te_Actl 1;
BA_ "GenSigStartValue" SG_ 1187 BattTracTe02_Te_Actl 254;
BA_ "GenSigStartValueInteger" SG_ 1187 BattTracTe02_Te_Actl 254;
BA_ "U_CD542_MY2021_Tx" SG_ 1187 BattTracTe01_Te_Actl 1;
BA_ "U_CX727_MY2021_Tx" SG_ 1187 BattTracTe01_Te_Actl 1;
BA_ "U_U55X_MY2022_Rx" SG_ 1187 BattTracTe01_Te_Actl 1;
BA_ "U_CD542_MY2021_Rx" SG_ 1187 BattTracTe01_Te_Actl 1;
BA_ "ECGUsedRxSignal" SG_ 1187 BattTracTe01_Te_Actl 1;
BA_ "GenSigStartValue" SG_ 1187 BattTracTe01_Te_Actl 254;
BA_ "GenSigStartValueInteger" SG_ 1187 BattTracTe01_Te_Actl 254;
BA_ "U_CD542_MY2021_Tx" SG_ 1187 BattTracCell96_U_Actl 1;
BA_ "U_CX727_MY2021_Tx" SG_ 1187 BattTracCell96_U_Actl 1;
BA_ "U_U55X_MY2022_Rx" SG_ 1187 BattTracCell96_U_Actl 1;
BA_ "U_CD542_MY2021_Rx" SG_ 1187 BattTracCell96_U_Actl 1;
BA_ "ECGUsedRxSignal" SG_ 1187 BattTracCell96_U_Actl 1;
BA_ "GenSigStartValue" SG_ 1187 BattTracCell96_U_Actl 4094;
BA_ "GenSigStartValueInteger" SG_ 1187 BattTracCell96_U_Actl 4094;
BA_ "U_CD542_MY2021_Tx" SG_ 1169 BattTracCell10_U_Actl 1;
BA_ "U_CX727_MY2021_Tx" SG_ 1169 BattTracCell10_U_Actl 1;
BA_ "U_U55X_MY2022_Rx" SG_ 1169 BattTracCell10_U_Actl 1;
BA_ "U_CD542_MY2021_Rx" SG_ 1169 BattTracCell10_U_Actl 1;
BA_ "ECGUsedRxSignal" SG_ 1169 BattTracCell10_U_Actl 1;
BA_ "GenSigStartValue" SG_ 1169 BattTracCell10_U_Actl 4094;
BA_ "GenSigStartValueInteger" SG_ 1169 BattTracCell10_U_Actl 4094;
BA_ "U_CD542_MY2021_Tx" SG_ 1169 BattTracCell09_U_Actl 1;
BA_ "U_CX727_MY2021_Tx" SG_ 1169 BattTracCell09_U_Actl 1;
BA_ "U_U55X_MY2022_Rx" SG_ 1169 BattTracCell09_U_Actl 1;
BA_ "U_CD542_MY2021_Rx" SG_ 1169 BattTracCell09_U_Actl 1;
BA_ "ECGUsedRxSignal" SG_ 1169 BattTracCell09_U_Actl 1;
BA_ "GenSigStartValue" SG_ 1169 BattTracCell09_U_Actl 4094;
BA_ "GenSigStartValueInteger" SG_ 1169 BattTracCell09_U_Actl 4094;
BA_ "U_CD542_MY2021_Tx" SG_ 1169 BattTracCell08_U_Actl 1;
BA_ "U_CX727_MY2021_Tx" SG_ 1169 BattTracCell08_U_Actl 1;
BA_ "U_U55X_MY2022_Rx" SG_ 1169 BattTracCell08_U_Actl 1;
BA_ "U_CD542_MY2021_Rx" SG_ 1169 BattTracCell08_U_Actl 1;
BA_ "ECGUsedRxSignal" SG_ 1169 BattTracCell08_U_Actl 1;
BA_ "GenSigStartValue" SG_ 1169 BattTracCell08_U_Actl 4094;
BA_ "GenSigStartValueInteger" SG_ 1169 BattTracCell08_U_Actl 4094;
BA_ "U_CD542_MY2021_Tx" SG_ 1169 BattTracCell07_U_Actl 1;
BA_ "U_CX727_MY2021_Tx" SG_ 1169 BattTracCell07_U_Actl 1;
BA_ "U_U55X_MY2022_Rx" SG_ 1169 BattTracCell07_U_Actl 1;
BA_ "U_CD542_MY2021_Rx" SG_ 1169 BattTracCell07_U_Actl 1;
BA_ "ECGUsedRxSignal" SG_ 1169 BattTracCell07_U_Actl 1;
BA_ "GenSigStartValue" SG_ 1169 BattTracCell07_U_Actl 4094;
BA_ "GenSigStartValueInteger" SG_ 1169 BattTracCell07_U_Actl 4094;
BA_ "U_CD542_MY2021_Tx" SG_ 1169 BattTracCell06_U_Actl 1;
BA_ "U_CX727_MY2021_Tx" SG_ 1169 BattTracCell06_U_Actl 1;
BA_ "U_U55X_MY2022_Rx" SG_ 1169 BattTracCell06_U_Actl 1;
BA_ "U_CD542_MY2021_Rx" SG_ 1169 BattTracCell06_U_Actl 1;
BA_ "ECGUsedRxSignal" SG_ 1169 BattTracCell06_U_Actl 1;
BA_ "GenSigStartValue" SG_ 1169 BattTracCell06_U_Actl 4094;
BA_ "GenSigStartValueInteger" SG_ 1169 BattTracCell06_U_Actl 4094;
BA_ "U_CD542_MY2021_Tx" SG_ 1186 BattTracCell95_U_Actl 1;
BA_ "U_CX727_MY2021_Tx" SG_ 1186 BattTracCell95_U_Actl 1;
BA_ "U_U55X_MY2022_Rx" SG_ 1186 BattTracCell95_U_Actl 1;
BA_ "U_CD542_MY2021_Rx" SG_ 1186 BattTracCell95_U_Actl 1;
BA_ "ECGUsedRxSignal" SG_ 1186 BattTracCell95_U_Actl 1;
BA_ "GenSigStartValue" SG_ 1186 BattTracCell95_U_Actl 4094;
BA_ "GenSigStartValueInteger" SG_ 1186 BattTracCell95_U_Actl 4094;
BA_ "U_CD542_MY2021_Tx" SG_ 1186 BattTracCell94_U_Actl 1;
BA_ "U_CX727_MY2021_Tx" SG_ 1186 BattTracCell94_U_Actl 1;
BA_ "U_U55X_MY2022_Rx" SG_ 1186 BattTracCell94_U_Actl 1;
BA_ "U_CD542_MY2021_Rx" SG_ 1186 BattTracCell94_U_Actl 1;
BA_ "ECGUsedRxSignal" SG_ 1186 BattTracCell94_U_Actl 1;
BA_ "GenSigStartValue" SG_ 1186 BattTracCell94_U_Actl 4094;
BA_ "GenSigStartValueInteger" SG_ 1186 BattTracCell94_U_Actl 4094;
BA_ "U_CD542_MY2021_Tx" SG_ 1186 BattTracCell93_U_Actl 1;
BA_ "U_CX727_MY2021_Tx" SG_ 1186 BattTracCell93_U_Actl 1;
BA_ "U_U55X_MY2022_Rx" SG_ 1186 BattTracCell93_U_Actl 1;
BA_ "U_CD542_MY2021_Rx" SG_ 1186 BattTracCell93_U_Actl 1;
BA_ "ECGUsedRxSignal" SG_ 1186 BattTracCell93_U_Actl 1;
BA_ "GenSigStartValue" SG_ 1186 BattTracCell93_U_Actl 4094;
BA_ "GenSigStartValueInteger" SG_ 1186 BattTracCell93_U_Actl 4094;
BA_ "U_CD542_MY2021_Tx" SG_ 1186 BattTracCell92_U_Actl 1;
BA_ "U_CX727_MY2021_Tx" SG_ 1186 BattTracCell92_U_Actl 1;
BA_ "U_U55X_MY2022_Rx" SG_ 1186 BattTracCell92_U_Actl 1;
BA_ "U_CD542_MY2021_Rx" SG_ 1186 BattTracCell92_U_Actl 1;
BA_ "ECGUsedRxSignal" SG_ 1186 BattTracCell92_U_Actl 1;
BA_ "GenSigStartValue" SG_ 1186 BattTracCell92_U_Actl 4094;
BA_ "GenSigStartValueInteger" SG_ 1186 BattTracCell92_U_Actl 4094;
BA_ "U_CD542_MY2021_Tx" SG_ 1186 BattTracCell91_U_Actl 1;
BA_ "U_CX727_MY2021_Tx" SG_ 1186 BattTracCell91_U_Actl 1;
BA_ "U_U55X_MY2022_Rx" SG_ 1186 BattTracCell91_U_Actl 1;
BA_ "U_CD542_MY2021_Rx" SG_ 1186 BattTracCell91_U_Actl 1;
BA_ "ECGUsedRxSignal" SG_ 1186 BattTracCell91_U_Actl 1;
BA_ "GenSigStartValue" SG_ 1186 BattTracCell91_U_Actl 4094;
BA_ "GenSigStartValueInteger" SG_ 1186 BattTracCell91_U_Actl 4094;
BA_ "U_CD542_MY2021_Tx" SG_ 1185 BattTracCell90_U_Actl 1;
BA_ "U_CX727_MY2021_Tx" SG_ 1185 BattTracCell90_U_Actl 1;
BA_ "U_U55X_MY2022_Rx" SG_ 1185 BattTracCell90_U_Actl 1;
BA_ "U_CD542_MY2021_Rx" SG_ 1185 BattTracCell90_U_Actl 1;
BA_ "ECGUsedRxSignal" SG_ 1185 BattTracCell90_U_Actl 1;
BA_ "GenSigStartValue" SG_ 1185 BattTracCell90_U_Actl 4094;
BA_ "GenSigStartValueInteger" SG_ 1185 BattTracCell90_U_Actl 4094;
BA_ "U_CD542_MY2021_Tx" SG_ 1185 BattTracCell89_U_Actl 1;
BA_ "U_CX727_MY2021_Tx" SG_ 1185 BattTracCell89_U_Actl 1;
BA_ "U_U55X_MY2022_Rx" SG_ 1185 BattTracCell89_U_Actl 1;
BA_ "U_CD542_MY2021_Rx" SG_ 1185 BattTracCell89_U_Actl 1;
BA_ "ECGUsedRxSignal" SG_ 1185 BattTracCell89_U_Actl 1;
BA_ "GenSigStartValue" SG_ 1185 BattTracCell89_U_Actl 4094;
BA_ "GenSigStartValueInteger" SG_ 1185 BattTracCell89_U_Actl 4094;
BA_ "U_CD542_MY2021_Tx" SG_ 1185 BattTracCell88_U_Actl 1;
BA_ "U_CX727_MY2021_Tx" SG_ 1185 BattTracCell88_U_Actl 1;
BA_ "U_U55X_MY2022_Rx" SG_ 1185 BattTracCell88_U_Actl 1;
BA_ "U_CD542_MY2021_Rx" SG_ 1185 BattTracCell88_U_Actl 1;
BA_ "ECGUsedRxSignal" SG_ 1185 BattTracCell88_U_Actl 1;
BA_ "GenSigStartValue" SG_ 1185 BattTracCell88_U_Actl 4094;
BA_ "GenSigStartValueInteger" SG_ 1185 BattTracCell88_U_Actl 4094;
BA_ "U_CD542_MY2021_Tx" SG_ 1185 BattTracCell87_U_Actl 1;
BA_ "U_CX727_MY2021_Tx" SG_ 1185 BattTracCell87_U_Actl 1;
BA_ "U_U55X_MY2022_Rx" SG_ 1185 BattTracCell87_U_Actl 1;
BA_ "U_CD542_MY2021_Rx" SG_ 1185 BattTracCell87_U_Actl 1;
BA_ "ECGUsedRxSignal" SG_ 1185 BattTracCell87_U_Actl 1;
BA_ "GenSigStartValue" SG_ 1185 BattTracCell87_U_Actl 4094;
BA_ "GenSigStartValueInteger" SG_ 1185 BattTracCell87_U_Actl 4094;
BA_ "U_CD542_MY2021_Tx" SG_ 1185 BattTracCell86_U_Actl 1;
BA_ "U_CX727_MY2021_Tx" SG_ 1185 BattTracCell86_U_Actl 1;
BA_ "U_U55X_MY2022_Rx" SG_ 1185 BattTracCell86_U_Actl 1;
BA_ "U_CD542_MY2021_Rx" SG_ 1185 BattTracCell86_U_Actl 1;
BA_ "ECGUsedRxSignal" SG_ 1185 BattTracCell86_U_Actl 1;
BA_ "GenSigStartValue" SG_ 1185 BattTracCell86_U_Actl 4094;
BA_ "GenSigStartValueInteger" SG_ 1185 BattTracCell86_U_Actl 4094;
BA_ "U_CD542_MY2021_Tx" SG_ 1184 BattTracCell85_U_Actl 1;
BA_ "U_CX727_MY2021_Tx" SG_ 1184 BattTracCell85_U_Actl 1;
BA_ "U_U55X_MY2022_Rx" SG_ 1184 BattTracCell85_U_Actl 1;
BA_ "U_CD542_MY2021_Rx" SG_ 1184 BattTracCell85_U_Actl 1;
BA_ "ECGUsedRxSignal" SG_ 1184 BattTracCell85_U_Actl 1;
BA_ "GenSigStartValue" SG_ 1184 BattTracCell85_U_Actl 4094;
BA_ "GenSigStartValueInteger" SG_ 1184 BattTracCell85_U_Actl 4094;
BA_ "U_CD542_MY2021_Tx" SG_ 1184 BattTracCell84_U_Actl 1;
BA_ "U_CX727_MY2021_Tx" SG_ 1184 BattTracCell84_U_Actl 1;
BA_ "U_U55X_MY2022_Rx" SG_ 1184 BattTracCell84_U_Actl 1;
BA_ "U_CD542_MY2021_Rx" SG_ 1184 BattTracCell84_U_Actl 1;
BA_ "ECGUsedRxSignal" SG_ 1184 BattTracCell84_U_Actl 1;
BA_ "GenSigStartValue" SG_ 1184 BattTracCell84_U_Actl 4094;
BA_ "GenSigStartValueInteger" SG_ 1184 BattTracCell84_U_Actl 4094;
BA_ "U_CD542_MY2021_Tx" SG_ 1184 BattTracCell83_U_Actl 1;
BA_ "U_CX727_MY2021_Tx" SG_ 1184 BattTracCell83_U_Actl 1;
BA_ "U_U55X_MY2022_Rx" SG_ 1184 BattTracCell83_U_Actl 1;
BA_ "U_CD542_MY2021_Rx" SG_ 1184 BattTracCell83_U_Actl 1;
BA_ "ECGUsedRxSignal" SG_ 1184 BattTracCell83_U_Actl 1;
BA_ "GenSigStartValue" SG_ 1184 BattTracCell83_U_Actl 4094;
BA_ "GenSigStartValueInteger" SG_ 1184 BattTracCell83_U_Actl 4094;
BA_ "U_CD542_MY2021_Tx" SG_ 1184 BattTracCell82_U_Actl 1;
BA_ "U_CX727_MY2021_Tx" SG_ 1184 BattTracCell82_U_Actl 1;
BA_ "U_U55X_MY2022_Rx" SG_ 1184 BattTracCell82_U_Actl 1;
BA_ "U_CD542_MY2021_Rx" SG_ 1184 BattTracCell82_U_Actl 1;
BA_ "ECGUsedRxSignal" SG_ 1184 BattTracCell82_U_Actl 1;
BA_ "GenSigStartValue" SG_ 1184 BattTracCell82_U_Actl 4094;
BA_ "GenSigStartValueInteger" SG_ 1184 BattTracCell82_U_Actl 4094;
BA_ "U_CD542_MY2021_Tx" SG_ 1184 BattTracCell81_U_Actl 1;
BA_ "U_CX727_MY2021_Tx" SG_ 1184 BattTracCell81_U_Actl 1;
BA_ "U_U55X_MY2022_Rx" SG_ 1184 BattTracCell81_U_Actl 1;
BA_ "U_CD542_MY2021_Rx" SG_ 1184 BattTracCell81_U_Actl 1;
BA_ "ECGUsedRxSignal" SG_ 1184 BattTracCell81_U_Actl 1;
BA_ "GenSigStartValue" SG_ 1184 BattTracCell81_U_Actl 4094;
BA_ "GenSigStartValueInteger" SG_ 1184 BattTracCell81_U_Actl 4094;
BA_ "U_CD542_MY2021_Tx" SG_ 1183 BattTracCell80_U_Actl 1;
BA_ "U_CX727_MY2021_Tx" SG_ 1183 BattTracCell80_U_Actl 1;
BA_ "U_U55X_MY2022_Rx" SG_ 1183 BattTracCell80_U_Actl 1;
BA_ "U_CD542_MY2021_Rx" SG_ 1183 BattTracCell80_U_Actl 1;
BA_ "ECGUsedRxSignal" SG_ 1183 BattTracCell80_U_Actl 1;
BA_ "GenSigStartValue" SG_ 1183 BattTracCell80_U_Actl 4094;
BA_ "GenSigStartValueInteger" SG_ 1183 BattTracCell80_U_Actl 4094;
BA_ "U_CD542_MY2021_Tx" SG_ 1183 BattTracCell79_U_Actl 1;
BA_ "U_CX727_MY2021_Tx" SG_ 1183 BattTracCell79_U_Actl 1;
BA_ "U_U55X_MY2022_Rx" SG_ 1183 BattTracCell79_U_Actl 1;
BA_ "U_CD542_MY2021_Rx" SG_ 1183 BattTracCell79_U_Actl 1;
BA_ "ECGUsedRxSignal" SG_ 1183 BattTracCell79_U_Actl 1;
BA_ "GenSigStartValue" SG_ 1183 BattTracCell79_U_Actl 4094;
BA_ "GenSigStartValueInteger" SG_ 1183 BattTracCell79_U_Actl 4094;
BA_ "U_CD542_MY2021_Tx" SG_ 1183 BattTracCell78_U_Actl 1;
BA_ "U_CX727_MY2021_Tx" SG_ 1183 BattTracCell78_U_Actl 1;
BA_ "U_U55X_MY2022_Rx" SG_ 1183 BattTracCell78_U_Actl 1;
BA_ "U_CD542_MY2021_Rx" SG_ 1183 BattTracCell78_U_Actl 1;
BA_ "ECGUsedRxSignal" SG_ 1183 BattTracCell78_U_Actl 1;
BA_ "GenSigStartValue" SG_ 1183 BattTracCell78_U_Actl 4094;
BA_ "GenSigStartValueInteger" SG_ 1183 BattTracCell78_U_Actl 4094;
BA_ "U_CD542_MY2021_Tx" SG_ 1183 BattTracCell77_U_Actl 1;
BA_ "U_CX727_MY2021_Tx" SG_ 1183 BattTracCell77_U_Actl 1;
BA_ "U_U55X_MY2022_Rx" SG_ 1183 BattTracCell77_U_Actl 1;
BA_ "U_CD542_MY2021_Rx" SG_ 1183 BattTracCell77_U_Actl 1;
BA_ "ECGUsedRxSignal" SG_ 1183 BattTracCell77_U_Actl 1;
BA_ "GenSigStartValue" SG_ 1183 BattTracCell77_U_Actl 4094;
BA_ "GenSigStartValueInteger" SG_ 1183 BattTracCell77_U_Actl 4094;
BA_ "U_CD542_MY2021_Tx" SG_ 1183 BattTracCell76_U_Actl 1;
BA_ "U_CX727_MY2021_Tx" SG_ 1183 BattTracCell76_U_Actl 1;
BA_ "U_U55X_MY2022_Rx" SG_ 1183 BattTracCell76_U_Actl 1;
BA_ "U_CD542_MY2021_Rx" SG_ 1183 BattTracCell76_U_Actl 1;
BA_ "ECGUsedRxSignal" SG_ 1183 BattTracCell76_U_Actl 1;
BA_ "GenSigStartValue" SG_ 1183 BattTracCell76_U_Actl 4094;
BA_ "GenSigStartValueInteger" SG_ 1183 BattTracCell76_U_Actl 4094;
BA_ "U_CD542_MY2021_Tx" SG_ 1182 BattTracCell75_U_Actl 1;
BA_ "U_CX727_MY2021_Tx" SG_ 1182 BattTracCell75_U_Actl 1;
BA_ "U_U55X_MY2022_Rx" SG_ 1182 BattTracCell75_U_Actl 1;
BA_ "U_CD542_MY2021_Rx" SG_ 1182 BattTracCell75_U_Actl 1;
BA_ "ECGUsedRxSignal" SG_ 1182 BattTracCell75_U_Actl 1;
BA_ "GenSigStartValue" SG_ 1182 BattTracCell75_U_Actl 4094;
BA_ "GenSigStartValueInteger" SG_ 1182 BattTracCell75_U_Actl 4094;
BA_ "U_CD542_MY2021_Tx" SG_ 1182 BattTracCell74_U_Actl 1;
BA_ "U_CX727_MY2021_Tx" SG_ 1182 BattTracCell74_U_Actl 1;
BA_ "U_U55X_MY2022_Rx" SG_ 1182 BattTracCell74_U_Actl 1;
BA_ "U_CD542_MY2021_Rx" SG_ 1182 BattTracCell74_U_Actl 1;
BA_ "ECGUsedRxSignal" SG_ 1182 BattTracCell74_U_Actl 1;
BA_ "GenSigStartValue" SG_ 1182 BattTracCell74_U_Actl 4094;
BA_ "GenSigStartValueInteger" SG_ 1182 BattTracCell74_U_Actl 4094;
BA_ "U_CD542_MY2021_Tx" SG_ 1182 BattTracCell73_U_Actl 1;
BA_ "U_CX727_MY2021_Tx" SG_ 1182 BattTracCell73_U_Actl 1;
BA_ "U_U55X_MY2022_Rx" SG_ 1182 BattTracCell73_U_Actl 1;
BA_ "U_CD542_MY2021_Rx" SG_ 1182 BattTracCell73_U_Actl 1;
BA_ "ECGUsedRxSignal" SG_ 1182 BattTracCell73_U_Actl 1;
BA_ "GenSigStartValue" SG_ 1182 BattTracCell73_U_Actl 4094;
BA_ "GenSigStartValueInteger" SG_ 1182 BattTracCell73_U_Actl 4094;
BA_ "U_CD542_MY2021_Tx" SG_ 1182 BattTracCell72_U_Actl 1;
BA_ "U_CX727_MY2021_Tx" SG_ 1182 BattTracCell72_U_Actl 1;
BA_ "U_U55X_MY2022_Rx" SG_ 1182 BattTracCell72_U_Actl 1;
BA_ "U_CD542_MY2021_Rx" SG_ 1182 BattTracCell72_U_Actl 1;
BA_ "ECGUsedRxSignal" SG_ 1182 BattTracCell72_U_Actl 1;
BA_ "GenSigStartValue" SG_ 1182 BattTracCell72_U_Actl 4094;
BA_ "GenSigStartValueInteger" SG_ 1182 BattTracCell72_U_Actl 4094;
BA_ "U_CD542_MY2021_Tx" SG_ 1182 BattTracCell71_U_Actl 1;
BA_ "U_CX727_MY2021_Tx" SG_ 1182 BattTracCell71_U_Actl 1;
BA_ "U_U55X_MY2022_Rx" SG_ 1182 BattTracCell71_U_Actl 1;
BA_ "U_CD542_MY2021_Rx" SG_ 1182 BattTracCell71_U_Actl 1;
BA_ "ECGUsedRxSignal" SG_ 1182 BattTracCell71_U_Actl 1;
BA_ "GenSigStartValue" SG_ 1182 BattTracCell71_U_Actl 4094;
BA_ "GenSigStartValueInteger" SG_ 1182 BattTracCell71_U_Actl 4094;
BA_ "U_CD542_MY2021_Tx" SG_ 1181 BattTracCell70_U_Actl 1;
BA_ "U_CX727_MY2021_Tx" SG_ 1181 BattTracCell70_U_Actl 1;
BA_ "U_U55X_MY2022_Rx" SG_ 1181 BattTracCell70_U_Actl 1;
BA_ "U_CD542_MY2021_Rx" SG_ 1181 BattTracCell70_U_Actl 1;
BA_ "ECGUsedRxSignal" SG_ 1181 BattTracCell70_U_Actl 1;
BA_ "GenSigStartValue" SG_ 1181 BattTracCell70_U_Actl 4094;
BA_ "GenSigStartValueInteger" SG_ 1181 BattTracCell70_U_Actl 4094;
BA_ "U_CD542_MY2021_Tx" SG_ 1181 BattTracCell69_U_Actl 1;
BA_ "U_CX727_MY2021_Tx" SG_ 1181 BattTracCell69_U_Actl 1;
BA_ "U_U55X_MY2022_Rx" SG_ 1181 BattTracCell69_U_Actl 1;
BA_ "U_CD542_MY2021_Rx" SG_ 1181 BattTracCell69_U_Actl 1;
BA_ "ECGUsedRxSignal" SG_ 1181 BattTracCell69_U_Actl 1;
BA_ "GenSigStartValue" SG_ 1181 BattTracCell69_U_Actl 4094;
BA_ "GenSigStartValueInteger" SG_ 1181 BattTracCell69_U_Actl 4094;
BA_ "U_CD542_MY2021_Tx" SG_ 1181 BattTracCell68_U_Actl 1;
BA_ "U_CX727_MY2021_Tx" SG_ 1181 BattTracCell68_U_Actl 1;
BA_ "U_U55X_MY2022_Rx" SG_ 1181 BattTracCell68_U_Actl 1;
BA_ "U_CD542_MY2021_Rx" SG_ 1181 BattTracCell68_U_Actl 1;
BA_ "ECGUsedRxSignal" SG_ 1181 BattTracCell68_U_Actl 1;
BA_ "GenSigStartValue" SG_ 1181 BattTracCell68_U_Actl 4094;
BA_ "GenSigStartValueInteger" SG_ 1181 BattTracCell68_U_Actl 4094;
BA_ "U_CD542_MY2021_Tx" SG_ 1181 BattTracCell67_U_Actl 1;
BA_ "U_CX727_MY2021_Tx" SG_ 1181 BattTracCell67_U_Actl 1;
BA_ "U_U55X_MY2022_Rx" SG_ 1181 BattTracCell67_U_Actl 1;
BA_ "U_CD542_MY2021_Rx" SG_ 1181 BattTracCell67_U_Actl 1;
BA_ "ECGUsedRxSignal" SG_ 1181 BattTracCell67_U_Actl 1;
BA_ "GenSigStartValue" SG_ 1181 BattTracCell67_U_Actl 4094;
BA_ "GenSigStartValueInteger" SG_ 1181 BattTracCell67_U_Actl 4094;
BA_ "U_CD542_MY2021_Tx" SG_ 1181 BattTracCell66_U_Actl 1;
BA_ "U_CX727_MY2021_Tx" SG_ 1181 BattTracCell66_U_Actl 1;
BA_ "U_U55X_MY2022_Rx" SG_ 1181 BattTracCell66_U_Actl 1;
BA_ "U_CD542_MY2021_Rx" SG_ 1181 BattTracCell66_U_Actl 1;
BA_ "ECGUsedRxSignal" SG_ 1181 BattTracCell66_U_Actl 1;
BA_ "GenSigStartValue" SG_ 1181 BattTracCell66_U_Actl 4094;
BA_ "GenSigStartValueInteger" SG_ 1181 BattTracCell66_U_Actl 4094;
BA_ "U_CD542_MY2021_Tx" SG_ 1180 BattTracCell65_U_Actl 1;
BA_ "U_CX727_MY2021_Tx" SG_ 1180 BattTracCell65_U_Actl 1;
BA_ "U_U55X_MY2022_Rx" SG_ 1180 BattTracCell65_U_Actl 1;
BA_ "U_CD542_MY2021_Rx" SG_ 1180 BattTracCell65_U_Actl 1;
BA_ "ECGUsedRxSignal" SG_ 1180 BattTracCell65_U_Actl 1;
BA_ "GenSigStartValue" SG_ 1180 BattTracCell65_U_Actl 4094;
BA_ "GenSigStartValueInteger" SG_ 1180 BattTracCell65_U_Actl 4094;
BA_ "U_CD542_MY2021_Tx" SG_ 1180 BattTracCell64_U_Actl 1;
BA_ "U_CX727_MY2021_Tx" SG_ 1180 BattTracCell64_U_Actl 1;
BA_ "U_U55X_MY2022_Rx" SG_ 1180 BattTracCell64_U_Actl 1;
BA_ "U_CD542_MY2021_Rx" SG_ 1180 BattTracCell64_U_Actl 1;
BA_ "ECGUsedRxSignal" SG_ 1180 BattTracCell64_U_Actl 1;
BA_ "GenSigStartValue" SG_ 1180 BattTracCell64_U_Actl 4094;
BA_ "GenSigStartValueInteger" SG_ 1180 BattTracCell64_U_Actl 4094;
BA_ "U_CD542_MY2021_Tx" SG_ 1180 BattTracCell63_U_Actl 1;
BA_ "U_CX727_MY2021_Tx" SG_ 1180 BattTracCell63_U_Actl 1;
BA_ "U_U55X_MY2022_Rx" SG_ 1180 BattTracCell63_U_Actl 1;
BA_ "U_CD542_MY2021_Rx" SG_ 1180 BattTracCell63_U_Actl 1;
BA_ "ECGUsedRxSignal" SG_ 1180 BattTracCell63_U_Actl 1;
BA_ "GenSigStartValue" SG_ 1180 BattTracCell63_U_Actl 4094;
BA_ "GenSigStartValueInteger" SG_ 1180 BattTracCell63_U_Actl 4094;
BA_ "U_CD542_MY2021_Tx" SG_ 1180 BattTracCell62_U_Actl 1;
BA_ "U_CX727_MY2021_Tx" SG_ 1180 BattTracCell62_U_Actl 1;
BA_ "U_U55X_MY2022_Rx" SG_ 1180 BattTracCell62_U_Actl 1;
BA_ "U_CD542_MY2021_Rx" SG_ 1180 BattTracCell62_U_Actl 1;
BA_ "ECGUsedRxSignal" SG_ 1180 BattTracCell62_U_Actl 1;
BA_ "GenSigStartValue" SG_ 1180 BattTracCell62_U_Actl 4094;
BA_ "GenSigStartValueInteger" SG_ 1180 BattTracCell62_U_Actl 4094;
BA_ "U_CD542_MY2021_Tx" SG_ 1180 BattTracCell61_U_Actl 1;
BA_ "U_CX727_MY2021_Tx" SG_ 1180 BattTracCell61_U_Actl 1;
BA_ "U_U55X_MY2022_Rx" SG_ 1180 BattTracCell61_U_Actl 1;
BA_ "U_CD542_MY2021_Rx" SG_ 1180 BattTracCell61_U_Actl 1;
BA_ "ECGUsedRxSignal" SG_ 1180 BattTracCell61_U_Actl 1;
BA_ "GenSigStartValue" SG_ 1180 BattTracCell61_U_Actl 4094;
BA_ "GenSigStartValueInteger" SG_ 1180 BattTracCell61_U_Actl 4094;
VAL_ 1167 PrplAxlScnd_Tq_ActlMntr 65535 "Faulty" 65534 "NoDataExists" ;
VAL_ 1167 Inv4TeAlrm_B_ActlMntr 1 "Active" 0 "Inactive" ;
VAL_ 1167 Inv4Ain_U_ActlMntr 1023 "Faulty" 1022 "NoDataExists" ;
VAL_ 1167 Inv4Ain_I_ActlMntr 32767 "Faulty" 32766 "NoDataExists" ;
VAL_ 1167 Inv4_Te_ActlMntr 255 "Faulty" 254 "NoDataExists" ;
VAL_ 1199 Mtr4TeAlrm_B_ActlMntr 1 "Active" 0 "Inactive" ;
VAL_ 1199 Mtr4Aout_W_ActlMntr 1023 "Faulty" ;
VAL_ 1199 Mtr4_Te_ActlMntr 255 "Faulty" 254 "NoDataExists" ;
VAL_ 1199 Mtr4_D_StatMntr 7 "Faulty" 6 "NotDataExists" 5 "NotUsed" 4 "ReadinessState" 3 "DeactivationState" 2 "PowerGeneration" 1 "PowerConsumption" 0 "Null" ;
VAL_ 1176 BattTracCell45_U_Actl 4095 "Fault" 4094 "NoDataExists" ;
VAL_ 1176 BattTracCell44_U_Actl 4095 "Fault" 4094 "NoDataExists" ;
VAL_ 1176 BattTracCell43_U_Actl 4095 "Fault" 4094 "NoDataExists" ;
VAL_ 1176 BattTracCell42_U_Actl 4095 "Fault" 4094 "NoDataExists" ;
VAL_ 1176 BattTracCell41_U_Actl 4095 "Fault" 4094 "NoDataExists" ;
VAL_ 1175 BattTracCell40_U_Actl 4095 "Fault" 4094 "NoDataExists" ;
VAL_ 1175 BattTracCell39_U_Actl 4095 "Fault" 4094 "NoDataExists" ;
VAL_ 1175 BattTracCell38_U_Actl 4095 "Fault" 4094 "NoDataExists" ;
VAL_ 1175 BattTracCell37_U_Actl 4095 "Fault" 4094 "NoDataExists" ;
VAL_ 1175 BattTracCell36_U_Actl 4095 "Fault" 4094 "NoDataExists" ;
VAL_ 1174 BattTracCell35_U_Actl 4095 "Fault" 4094 "NoDataExists" ;
VAL_ 1174 BattTracCell34_U_Actl 4095 "Fault" 4094 "NoDataExists" ;
VAL_ 1174 BattTracCell33_U_Actl 4095 "Fault" 4094 "NoDataExists" ;
VAL_ 1174 BattTracCell32_U_Actl 4095 "Fault" 4094 "NoDataExists" ;
VAL_ 1174 BattTracCell31_U_Actl 4095 "Fault" 4094 "NoDataExists" ;
VAL_ 1173 BattTracCell30_U_Actl 4095 "Fault" 4094 "NoDataExists" ;
VAL_ 1173 BattTracCell29_U_Actl 4095 "Fault" 4094 "NoDataExists" ;
VAL_ 1173 BattTracCell28_U_Actl 4095 "Fault" 4094 "NoDataExists" ;
VAL_ 1173 BattTracCell27_U_Actl 4095 "Fault" 4094 "NoDataExists" ;
VAL_ 1173 BattTracCell26_U_Actl 4095 "Fault" 4094 "NoDataExists" ;
VAL_ 1172 BattTracCell25_U_Actl 4095 "Fault" 4094 "NoDataExists" ;
VAL_ 1172 BattTracCell24_U_Actl 4095 "Fault" 4094 "NoDataExists" ;
VAL_ 1172 BattTracCell23_U_Actl 4095 "Fault" 4094 "NoDataExists" ;
VAL_ 1172 BattTracCell22_U_Actl 4095 "Fault" 4094 "NoDataExists" ;
VAL_ 1172 BattTracCell21_U_Actl 4095 "Fault" 4094 "NoDataExists" ;
VAL_ 1171 BattTracCell20_U_Actl 4095 "Fault" 4094 "NoDataExists" ;
VAL_ 1171 BattTracCell19_U_Actl 4095 "Fault" 4094 "NoDataExists" ;
VAL_ 1171 BattTracCell18_U_Actl 4095 "Fault" 4094 "NoDataExists" ;
VAL_ 1171 BattTracCell17_U_Actl 4095 "Fault" 4094 "NoDataExists" ;
VAL_ 1171 BattTracCell16_U_Actl 4095 "Fault" 4094 "NoDataExists" ;
VAL_ 1170 BattTracCell15_U_Actl 4095 "Fault" 4094 "NoDataExists" ;
VAL_ 1170 BattTracCell14_U_Actl 4095 "Fault" 4094 "NoDataExists" ;
VAL_ 1170 BattTracCell13_U_Actl 4095 "Fault" 4094 "NoDataExists" ;
VAL_ 1170 BattTracCell12_U_Actl 4095 "Fault" 4094 "NoDataExists" ;
VAL_ 1170 BattTracCell11_U_Actl 4095 "Fault" 4094 "NoDataExists" ;
VAL_ 1191 BattTracTe14_Te_Actl 255 "Faulty" 254 "NoDataExists" ;
VAL_ 1191 BattTracTe19_Te_Actl 255 "Faulty" 254 "NoDataExists" ;
VAL_ 1191 BattTracTe18_Te_Actl 255 "Faulty" 254 "NoDataExists" ;
VAL_ 1191 BattTracTe17_Te_Actl 255 "Faulty" 254 "NoDataExists" ;
VAL_ 1191 BattTracTe16_Te_Actl 255 "Faulty" 254 "NoDataExists" ;
VAL_ 1191 BattTracTe15_Te_Actl 255 "Faulty" 254 "NoDataExists" ;
VAL_ 1189 BattTracCellUMx_No_Actl 255 "Faulty" 254 "NoDataExists" ;
VAL_ 1189 BattChrgUMx_B_Falt 1 "Yes" 0 "No" ;
VAL_ 1189 BattTracCellUMn_No_Actl 255 "Faulty" 254 "NoDataExists" ;
VAL_ 1189 BattTracCellCnt_No_Actl 255 "Faulty" 254 "NoDataExists" ;
VAL_ 1189 BattTracCellDiff_B_Falt 1 "Yes" 0 "No" ;
VAL_ 1189 BattChrgSocMx_B_Falt 1 "Yes" 0 "No" ;
VAL_ 1189 BattChrgSocMn_B_Falt 1 "Yes" 0 "No" ;
VAL_ 1189 BattChrgSocErrtc_B_Falt 1 "Yes" 0 "No" ;
VAL_ 1189 BattTracUMx_B_Falt 1 "Yes" 0 "No" ;
VAL_ 1189 BattTracUMn_B_Falt 1 "Yes" 0 "No" ;
VAL_ 1189 BattTracTeMx_No_Actl 255 "Faulty" 254 "NoDataExists" ;
VAL_ 1189 BattTracTeMx_B_Falt 1 "Yes" 0 "No" ;
VAL_ 1189 BattTracTeMn_No_Actl 255 "Faulty" 254 "NoDataExists" ;
VAL_ 1189 BattTracTeDelta_B_Falt 1 "Yes" 0 "No" ;
VAL_ 1189 BattTracTeCnt_No_Actl 255 "Faulty" 254 "NoDataExists" ;
VAL_ 1189 BattTracSoftware_B_Falt 1 "Yes" 0 "No" ;
VAL_ 1188 BattTracTe13_Te_Actl 255 "Faulty" 254 "NoDataExists" ;
VAL_ 1188 BattTracTe12_Te_Actl 255 "Faulty" 254 "NoDataExists" ;
VAL_ 1188 BattTracTe11_Te_Actl 255 "Faulty" 254 "NoDataExists" ;
VAL_ 1188 BattTracTe10_Te_Actl 255 "Faulty" 254 "NoDataExists" ;
VAL_ 1188 BattTracTe09_Te_Actl 255 "Faulty" 254 "NoDataExists" ;
VAL_ 1188 BattTracTe08_Te_Actl 255 "Faulty" 254 "NoDataExists" ;
VAL_ 1188 BattTracTe07_Te_Actl 255 "Faulty" 254 "NoDataExists" ;
VAL_ 1187 BattTracTe06_Te_Actl 255 "Faulty" 254 "NoDataExists" ;
VAL_ 1187 BattTracTe05_Te_Actl 255 "Faulty" 254 "NoDataExists" ;
VAL_ 1187 BattTracTe04_Te_Actl 255 "Faulty" 254 "NoDataExists" ;
VAL_ 1187 BattTracTe03_Te_Actl 255 "Faulty" 254 "NoDataExists" ;
VAL_ 1187 BattTracTe02_Te_Actl 255 "Faulty" 254 "NoDataExists" ;
VAL_ 1187 BattTracTe01_Te_Actl 255 "Faulty" 254 "NoDataExists" ;
VAL_ 1187 BattTracCell96_U_Actl 4095 "Fault" 4094 "NoDataExists" ;
VAL_ 1169 BattTracCell10_U_Actl 4095 "Fault" 4094 "NoDataExists" ;
VAL_ 1169 BattTracCell09_U_Actl 4095 "Fault" 4094 "NoDataExists" ;
VAL_ 1169 BattTracCell08_U_Actl 4095 "Fault" 4094 "NoDataExists" ;
VAL_ 1169 BattTracCell07_U_Actl 4095 "Fault" 4094 "NoDataExists" ;
VAL_ 1169 BattTracCell06_U_Actl 4095 "Fault" 4094 "NoDataExists" ;
VAL_ 1186 BattTracCell95_U_Actl 4095 "Fault" 4094 "NoDataExists" ;
VAL_ 1186 BattTracCell94_U_Actl 4095 "Fault" 4094 "NoDataExists" ;
VAL_ 1186 BattTracCell93_U_Actl 4095 "Fault" 4094 "NoDataExists" ;
VAL_ 1186 BattTracCell92_U_Actl 4095 "Fault" 4094 "NoDataExists" ;
VAL_ 1186 BattTracCell91_U_Actl 4095 "Fault" 4094 "NoDataExists" ;
VAL_ 1185 BattTracCell90_U_Actl 4095 "Fault" 4094 "NoDataExists" ;
VAL_ 1185 BattTracCell89_U_Actl 4095 "Fault" 4094 "NoDataExists" ;
VAL_ 1185 BattTracCell88_U_Actl 4095 "Fault" 4094 "NoDataExists" ;
VAL_ 1185 BattTracCell87_U_Actl 4095 "Fault" 4094 "NoDataExists" ;
VAL_ 1185 BattTracCell86_U_Actl 4095 "Fault" 4094 "NoDataExists" ;
VAL_ 1184 BattTracCell85_U_Actl 4095 "Fault" 4094 "NoDataExists" ;
VAL_ 1184 BattTracCell84_U_Actl 4095 "Fault" 4094 "NoDataExists" ;
VAL_ 1184 BattTracCell83_U_Actl 4095 "Fault" 4094 "NoDataExists" ;
VAL_ 1184 BattTracCell82_U_Actl 4095 "Fault" 4094 "NoDataExists" ;
VAL_ 1184 BattTracCell81_U_Actl 4095 "Fault" 4094 "NoDataExists" ;
VAL_ 1183 BattTracCell80_U_Actl 4095 "Fault" 4094 "NoDataExists" ;
VAL_ 1183 BattTracCell79_U_Actl 4095 "Fault" 4094 "NoDataExists" ;
VAL_ 1183 BattTracCell78_U_Actl 4095 "Fault" 4094 "NoDataExists" ;
VAL_ 1183 BattTracCell77_U_Actl 4095 "Fault" 4094 "NoDataExists" ;
VAL_ 1183 BattTracCell76_U_Actl 4095 "Fault" 4094 "NoDataExists" ;
VAL_ 1182 BattTracCell75_U_Actl 4095 "Fault" 4094 "NoDataExists" ;
VAL_ 1182 BattTracCell74_U_Actl 4095 "Fault" 4094 "NoDataExists" ;
VAL_ 1182 BattTracCell73_U_Actl 4095 "Fault" 4094 "NoDataExists" ;
VAL_ 1182 BattTracCell72_U_Actl 4095 "Fault" 4094 "NoDataExists" ;
VAL_ 1182 BattTracCell71_U_Actl 4095 "Fault" 4094 "NoDataExists" ;
VAL_ 1181 BattTracCell70_U_Actl 4095 "Fault" 4094 "NoDataExists" ;
VAL_ 1181 BattTracCell69_U_Actl 4095 "Fault" 4094 "NoDataExists" ;
VAL_ 1181 BattTracCell68_U_Actl 4095 "Fault" 4094 "NoDataExists" ;
VAL_ 1181 BattTracCell67_U_Actl 4095 "Fault" 4094 "NoDataExists" ;
VAL_ 1181 BattTracCell66_U_Actl 4095 "Fault" 4094 "NoDataExists" ;
VAL_ 1180 BattTracCell65_U_Actl 4095 "Fault" 4094 "NoDataExists" ;
VAL_ 1180 BattTracCell64_U_Actl 4095 "Fault" 4094 "NoDataExists" ;
VAL_ 1180 BattTracCell63_U_Actl 4095 "Fault" 4094 "NoDataExists" ;
VAL_ 1180 BattTracCell62_U_Actl 4095 "Fault" 4094 "NoDataExists" ;
VAL_ 1180 BattTracCell61_U_Actl 4095 "Fault" 4094 "NoDataExists" ;
